VERSION ""

NS_ :

BS_:

BU_: A_IVC BLM CGW VKM

BO_ 1469 IVI_UserSetPref_A4: 8 CGW
  SG_ MeterVolumeRequest : 10|3@0+ (1,0) [0|0] "" A_IVC
  SG_ ADB_ActivationRequest2 : 61|2@0+ (1,0) [0|0] "" A_IVC

BO_ 1470 AVM_N105: 6 CGW
  SG_ RPK_RegistAddress2 : 7|48@0+ (1,0) [0|2.81474976710655E14] "-" VKM

BO_ 1471 PSCU_R1: 4 CGW
  SG_ PassengerMassageIntensityState : 12|3@0+ (1,0) [0|0] "" A_IVC
  SG_ PassengerMassageVelocityState : 15|3@0+ (1,0) [0|0] "" A_IVC
  SG_ PassengerMassageActivationState : 19|1@0+ (1,0) [0|0] "" A_IVC

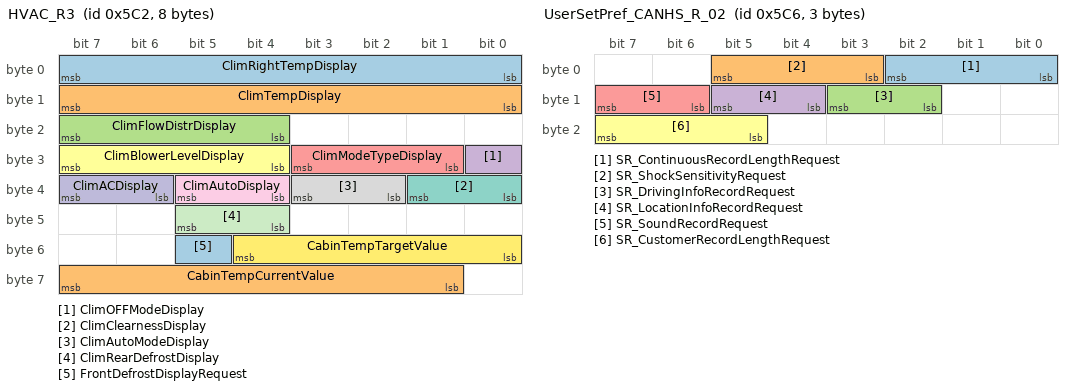
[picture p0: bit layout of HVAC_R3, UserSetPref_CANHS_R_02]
BO_ 1474 HVAC_R3: 8 CGW
  SG_ ClimRightTempDisplay : 7|8@0+ (0.5,0) [10|127.5] "°" A_IVC
  SG_ ClimTempDisplay : 15|8@0+ (0.5,0) [10|127.5] "°" A_IVC
  SG_ ClimFlowDistrDisplay : 23|4@0+ (1,0) [0|0] "" A_IVC
  SG_ ClimOFFModeDisplay : 24|1@0+ (1,0) [0|0] "" A_IVC
  SG_ ClimModeTypeDisplay : 27|3@0+ (1,0) [0|0] "" A_IVC
  SG_ ClimBlowerLevelDisplay : 31|4@0+ (1,0) [0|0] "" A_IVC
  SG_ ClimClearnessDisplay : 33|2@0+ (1,0) [0|0] "" A_IVC
  SG_ ClimAutoModeDisplay : 35|2@0+ (1,0) [0|0] "" A_IVC
  SG_ ClimAutoDisplay : 37|2@0+ (1,0) [0|0] "" A_IVC
  SG_ ClimACDisplay : 39|2@0+ (1,0) [0|0] "" A_IVC
  SG_ ClimRearDefrostDisplay : 45|2@0+ (1,0) [0|0] "" A_IVC
  SG_ CabinTempTargetValue : 52|5@0+ (0.5,16) [16|26] "°C" A_IVC
  SG_ FrontDefrostDisplayRequest : 53|1@0+ (1,0) [0|0] "" A_IVC
  SG_ CabinTempCurrentValue : 63|7@0+ (1,-40) [-40|60] "°C" A_IVC

BO_ 1475 BMS_R2: 8 CGW
  SG_ HVB_Cell111Voltage : 7|12@0+ (0.001,2) [2|4.6] "V" A_IVC
  SG_ HVB_Cell112Voltage : 11|12@0+ (0.001,2) [2|4.6] "V" A_IVC
  SG_ HVB_Cell113Voltage : 31|12@0+ (0.001,2) [2|4.6] "V" A_IVC
  SG_ HVB_Cell114Voltage : 35|12@0+ (0.001,2) [2|4.6] "V" A_IVC
  SG_ HVB_Cell115Voltage : 55|12@0+ (0.001,2) [2|4.6] "V" A_IVC

BO_ 1478 UserSetPref_CANHS_R_02: 3 CGW
  SG_ SR_ContinuousRecordLengthRequest : 2|3@0+ (1,0) [0|0] "" A_IVC
  SG_ SR_ShockSensitivityRequest : 5|3@0+ (1,0) [0|0] "" A_IVC
  SG_ SR_DrivingInfoRecordRequest : 11|2@0+ (1,0) [0|0] "" A_IVC
  SG_ SR_LocationInfoRecordRequest : 13|2@0+ (1,0) [0|0] "" A_IVC
  SG_ SR_SoundRecordRequest : 15|2@0+ (1,0) [0|0] "" A_IVC
  SG_ SR_CustomerRecordLengthRequest : 23|3@0+ (1,0) [0|0] "" A_IVC

BO_ 1479 IVI_R102: 6 CGW
  SG_ ERP_ActivationStatus : 34|1@0+ (1,0) [0|0] "" A_IVC

BO_ 1480 HEVC_A152: 8 CGW
  SG_ ChargeTimeDisplayAtAPrct : 23|12@0+ (1,0) [1|4094] "min" A_IVC
  SG_ ChargeTimeDisplayAtBPrct : 27|12@0+ (1,0) [1|4094] "min" A_IVC
  SG_ ChargeTimeDisplayAtCPrct : 47|12@0+ (1,0) [1|4094] "min" A_IVC
  SG_ ChargeTimeDisplayAtDPrct : 51|12@0+ (1,0) [1|4094] "min" A_IVC

BO_ 1481 BMS_A22: 8 CGW
  SG_ HVB_Cell61Voltage : 7|12@0+ (0.001,2) [2|4.6] "V" A_IVC
  SG_ HVB_Cell62Voltage : 11|12@0+ (0.001,2) [2|4.6] "V" A_IVC
  SG_ HVB_Cell63Voltage : 31|12@0+ (0.001,2) [2|4.6] "V" A_IVC
  SG_ HVB_Cell64Voltage : 35|12@0+ (0.001,2) [2|4.6] "V" A_IVC
  SG_ HVB_Cell65Voltage : 55|12@0+ (0.001,2) [2|4.6] "V" A_IVC

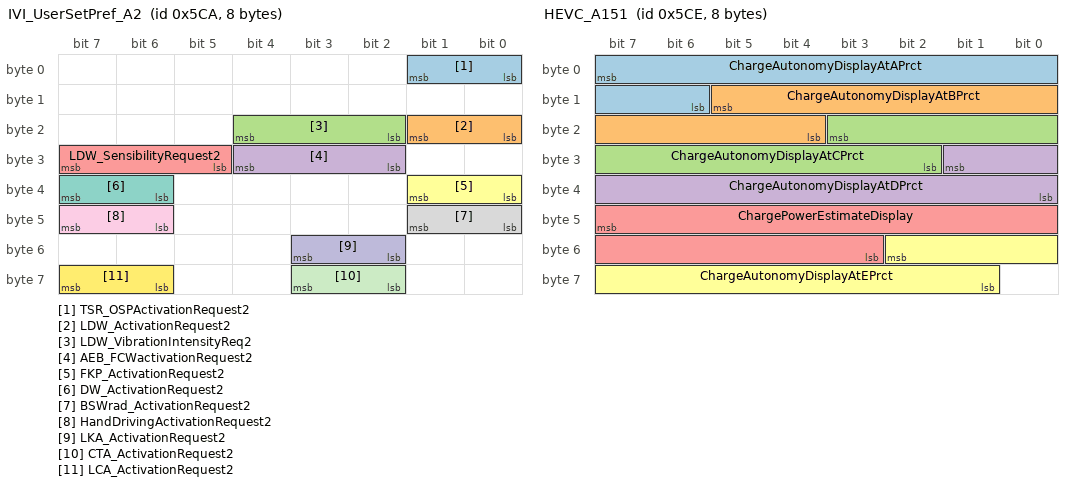
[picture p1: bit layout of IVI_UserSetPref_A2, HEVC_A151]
BO_ 1482 IVI_UserSetPref_A2: 8 CGW
  SG_ TSR_OSPActivationRequest2 : 1|2@0+ (1,0) [0|0] "" A_IVC
  SG_ LDW_ActivationRequest2 : 17|2@0+ (1,0) [0|0] "" A_IVC
  SG_ LDW_VibrationIntensityReq2 : 20|3@0+ (1,0) [0|0] "" A_IVC
  SG_ AEB_FCWactivationRequest2 : 28|3@0+ (1,0) [0|0] "" A_IVC
  SG_ LDW_SensibilityRequest2 : 31|3@0+ (1,0) [0|0] "" A_IVC
  SG_ FKP_ActivationRequest2 : 33|2@0+ (1,0) [0|0] "" A_IVC
  SG_ DW_ActivationRequest2 : 39|2@0+ (1,0) [0|0] "" A_IVC
  SG_ BSWrad_ActivationRequest2 : 41|2@0+ (1,0) [0|0] "" A_IVC
  SG_ HandDrivingActivationRequest2 : 47|2@0+ (1,0) [0|0] "" A_IVC
  SG_ LKA_ActivationRequest2 : 51|2@0+ (1,0) [0|0] "" A_IVC
  SG_ CTA_ActivationRequest2 : 59|2@0+ (1,0) [0|0] "" A_IVC
  SG_ LCA_ActivationRequest2 : 63|2@0+ (1,0) [0|0] "" A_IVC

BO_ 1483 BMS_A21: 8 CGW
  SG_ HVB_Cell56Voltage : 7|12@0+ (0.001,2) [2|4.6] "V" A_IVC
  SG_ HVB_Cell57Voltage : 11|12@0+ (0.001,2) [2|4.6] "V" A_IVC
  SG_ HVB_Cell58Voltage : 31|12@0+ (0.001,2) [2|4.6] "V" A_IVC
  SG_ HVB_Cell59Voltage : 35|12@0+ (0.001,2) [2|4.6] "V" A_IVC
  SG_ HVB_Cell60Voltage : 55|12@0+ (0.001,2) [2|4.6] "V" A_IVC

BO_ 1484 BMS_A20: 8 CGW
  SG_ HVB_Cell51Voltage : 7|12@0+ (0.001,2) [2|4.6] "V" A_IVC
  SG_ HVB_Cell52Voltage : 11|12@0+ (0.001,2) [2|4.6] "V" A_IVC
  SG_ HVB_Cell53Voltage : 31|12@0+ (0.001,2) [2|4.6] "V" A_IVC
  SG_ HVB_Cell54Voltage : 35|12@0+ (0.001,2) [2|4.6] "V" A_IVC
  SG_ HVB_Cell55Voltage : 55|12@0+ (0.001,2) [2|4.6] "V" A_IVC

BO_ 1485 RemoteFunctionService_BCM_Frame: 8 CGW
  SG_ RemoteFunctionService_BCM : 7|64@0+ (1,0) [0|0] "" A_IVC

BO_ 1486 HEVC_A151: 8 CGW
  SG_ ChargeAutonomyDisplayAtAPrct : 7|10@0+ (1,0) [1|1022] "km" A_IVC
  SG_ ChargeAutonomyDisplayAtBPrct : 13|10@0+ (1,0) [1|1022] "km" A_IVC
  SG_ ChargeAutonomyDisplayAtCPrct : 19|10@0+ (1,0) [1|1022] "km" A_IVC
  SG_ ChargeAutonomyDisplayAtDPrct : 25|10@0+ (1,0) [1|1022] "km" A_IVC
  SG_ ChargePowerEstimateDisplay : 47|13@0+ (0.1,0) [0.1|500] "kW" A_IVC
  SG_ ChargeAutonomyDisplayAtEPrct : 50|10@0+ (1,0) [1|1022] "km" A_IVC

BO_ 1488 ADAS_A110: 8 CGW
  SG_ ACC_StatusDisplay_v2 : 63|3@0+ (1,0) [0|0] "" A_IVC

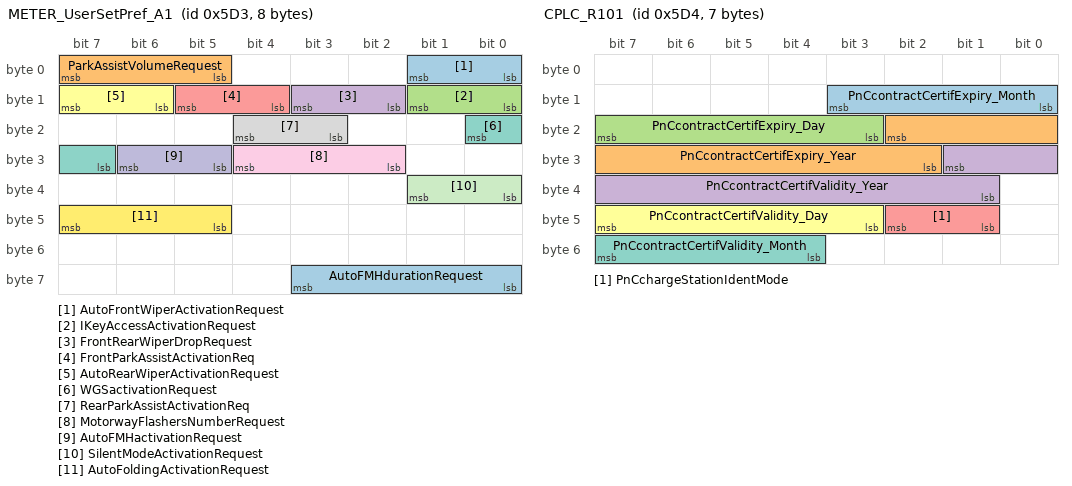
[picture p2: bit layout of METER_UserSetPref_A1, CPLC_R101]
BO_ 1491 METER_UserSetPref_A1: 8 CGW
  SG_ AutoFrontWiperActivationRequest : 1|2@0+ (1,0) [0|0] "" A_IVC
  SG_ ParkAssistVolumeRequest : 7|3@0+ (1,0) [0|0] "" A_IVC
  SG_ IKeyAccessActivationRequest : 9|2@0+ (1,0) [0|0] "" A_IVC
  SG_ FrontRearWiperDropRequest : 11|2@0+ (1,0) [0|0] "" A_IVC
  SG_ FrontParkAssistActivationReq : 13|2@0+ (1,0) [0|0] "" A_IVC
  SG_ AutoRearWiperActivationRequest : 15|2@0+ (1,0) [0|0] "" A_IVC
  SG_ WGSactivationRequest : 16|2@0+ (1,0) [0|0] "" A_IVC
  SG_ RearParkAssistActivationReq : 20|2@0+ (1,0) [0|0] "" A_IVC
  SG_ MotorwayFlashersNumberRequest : 28|3@0+ (1,0) [0|0] "" A_IVC
  SG_ AutoFMHactivationRequest : 30|2@0+ (1,0) [0|0] "" A_IVC
  SG_ SilentModeActivationRequest : 33|2@0+ (1,0) [0|0] "" A_IVC
  SG_ AutoFoldingActivationRequest : 47|3@0+ (1,0) [0|0] "" A_IVC
  SG_ AutoFMHdurationRequest : 59|4@0+ (1,0) [0|0] "" A_IVC

BO_ 1492 CPLC_R101: 7 CGW
  SG_ PnCcontractCertifExpiry_Month : 11|4@0+ (1,0) [0|12] "month" A_IVC
  SG_ PnCcontractCertifExpiry_Year : 18|9@0+ (1,2000) [2000|2500] "year" A_IVC
  SG_ PnCcontractCertifExpiry_Day : 23|5@0+ (1,0) [0|31] "day" A_IVC
  SG_ PnCcontractCertifValidity_Year : 25|9@0+ (1,2000) [2000|2500] "year" A_IVC
  SG_ PnCchargeStationIdentMode : 42|2@0+ (1,0) [0|0] "" A_IVC
  SG_ PnCcontractCertifValidity_Day : 47|5@0+ (1,0) [0|31] "day" A_IVC
  SG_ PnCcontractCertifValidity_Month : 55|4@0+ (1,0) [0|12] "month" A_IVC

BO_ 1493 HEVC_A150: 8 CGW
  SG_ CumulatedEnergyCharged_BLMS : 7|8@0+ (0.5,0) [0|100] "kWh" A_IVC
  SG_ CumulatedEnergyDisharged_BLMS : 15|14@0+ (0.01,0) [0|100] "GWh" A_IVC
  SG_ NumACsmartchargingBreak_BLMS : 17|12@0+ (10,0) [0|40000] "" A_IVC
  SG_ RE_ElecMachineTorque_BLMS : 37|11@0+ (0.5,-300) [-300|500] "Nm" A_IVC
  SG_ RE_ElecMachineWorkingMode_BLMS : 42|1@0+ (1,0) [0|0] "" A_IVC

BO_ 1494 BMS_A19: 8 CGW
  SG_ HVB_Cell46Voltage : 7|12@0+ (0.001,2) [2|4.6] "V" A_IVC
  SG_ HVB_Cell47Voltage : 11|12@0+ (0.001,2) [2|4.6] "V" A_IVC
  SG_ HVB_Cell48Voltage : 31|12@0+ (0.001,2) [2|4.6] "V" A_IVC
  SG_ HVB_Cell49Voltage : 35|12@0+ (0.001,2) [2|4.6] "V" A_IVC
  SG_ HVB_Cell50Voltage : 55|12@0+ (0.001,2) [2|4.6] "V" A_IVC

BO_ 1495 BMS_A18: 8 CGW
  SG_ HVB_Cell41Voltage : 7|12@0+ (0.001,2) [2|4.6] "V" A_IVC
  SG_ HVB_Cell42Voltage : 11|12@0+ (0.001,2) [2|4.6] "V" A_IVC
  SG_ HVB_Cell43Voltage : 31|12@0+ (0.001,2) [2|4.6] "V" A_IVC
  SG_ HVB_Cell44Voltage : 35|12@0+ (0.001,2) [2|4.6] "V" A_IVC
  SG_ HVB_Cell45Voltage : 55|12@0+ (0.001,2) [2|4.6] "V" A_IVC

BO_ 1497 BMS_A17: 8 CGW
  SG_ HVB_Cell36Voltage : 7|12@0+ (0.001,2) [2|4.6] "V" A_IVC
  SG_ HVB_Cell37Voltage : 11|12@0+ (0.001,2) [2|4.6] "V" A_IVC
  SG_ HVB_Cell38Voltage : 31|12@0+ (0.001,2) [2|4.6] "V" A_IVC
  SG_ HVB_Cell39Voltage : 35|12@0+ (0.001,2) [2|4.6] "V" A_IVC
  SG_ HVB_Cell40Voltage : 55|12@0+ (0.001,2) [2|4.6] "V" A_IVC

BO_ 1499 RemoteFunctionService_HFM_Frame: 8 CGW
  SG_ RemoteFunctionService_HFM : 7|64@0+ (1,0) [0|0] "" A_IVC

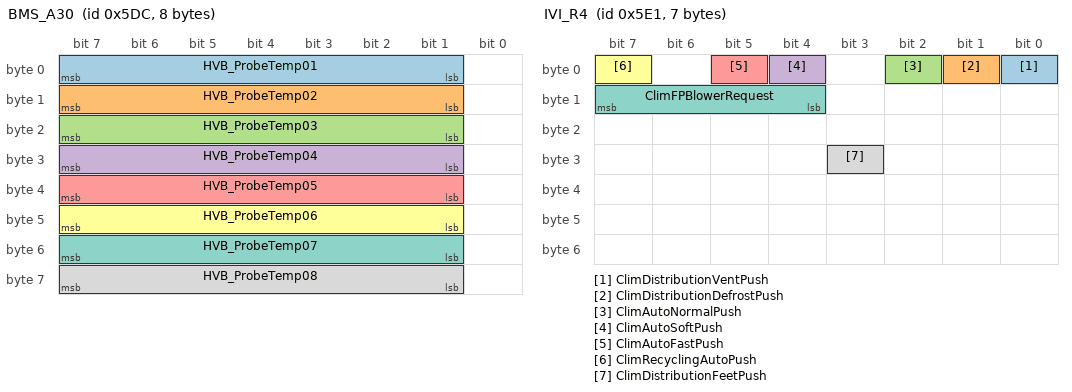
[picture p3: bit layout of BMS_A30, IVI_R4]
BO_ 1500 BMS_A30: 8 CGW
  SG_ HVB_ProbeTemp01 : 7|7@0+ (1,-40) [-40|80] "°C" A_IVC
  SG_ HVB_ProbeTemp02 : 15|7@0+ (1,-40) [-40|80] "°C" A_IVC
  SG_ HVB_ProbeTemp03 : 23|7@0+ (1,-40) [-40|80] "°C" A_IVC
  SG_ HVB_ProbeTemp04 : 31|7@0+ (1,-40) [-40|80] "°C" A_IVC
  SG_ HVB_ProbeTemp05 : 39|7@0+ (1,-40) [-40|80] "°C" A_IVC
  SG_ HVB_ProbeTemp06 : 47|7@0+ (1,-40) [-40|80] "°C" A_IVC
  SG_ HVB_ProbeTemp07 : 55|7@0+ (1,-40) [-40|80] "°C" A_IVC
  SG_ HVB_ProbeTemp08 : 63|7@0+ (1,-40) [-40|80] "°C" A_IVC

BO_ 1501 FRCAMERA_A109: 5 CGW
  SG_ OverspeedAlertStatusDisplay : 38|2@0+ (1,0) [0|0] "" A_IVC

BO_ 1502 CDM_A107: 3 CGW
  SG_ MultiDriveMode_ECM_v2 : 7|4@0+ (1,0) [0|0] "" A_IVC

BO_ 1504 BMS_A101: 8 CGW
  SG_ HVB_Cell96Voltage : 7|12@0+ (0.001,2) [2|4.6] "V" A_IVC
  SG_ HVB_Cell97Voltage : 11|12@0+ (0.001,2) [2|4.6] "V" A_IVC
  SG_ HVB_Cell98Voltage : 31|12@0+ (0.001,2) [2|4.6] "V" A_IVC
  SG_ HVB_Cell99Voltage : 35|12@0+ (0.001,2) [2|4.6] "V" A_IVC
  SG_ HVB_Cell100Voltage : 55|12@0+ (0.001,2) [2|4.6] "V" A_IVC

BO_ 1505 IVI_R4: 7 CGW
  SG_ ClimDistributionVentPush : 0|1@0+ (1,0) [0|1] "" A_IVC
  SG_ ClimDistributionDefrostPush : 1|1@0+ (1,0) [0|1] "" A_IVC
  SG_ ClimAutoNormalPush : 2|1@0+ (1,0) [0|1] "" A_IVC
  SG_ ClimAutoSoftPush : 4|1@0+ (1,0) [0|1] "" A_IVC
  SG_ ClimAutoFastPush : 5|1@0+ (1,0) [0|1] "" A_IVC
  SG_ ClimRecyclingAutoPush : 7|1@0+ (1,0) [0|1] "" A_IVC
  SG_ ClimFPBlowerRequest : 15|4@0+ (1,0) [0|0] "" A_IVC
  SG_ ClimDistributionFeetPush : 27|1@0+ (1,0) [0|1] "" A_IVC

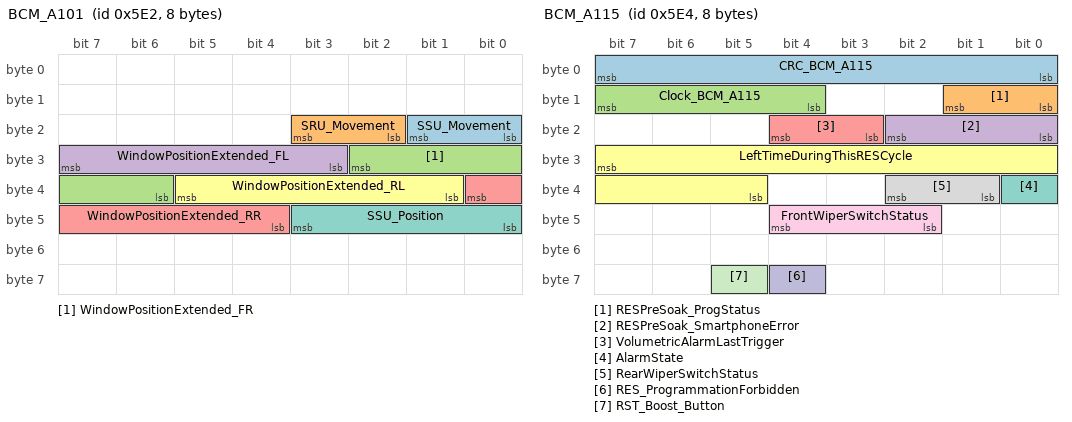
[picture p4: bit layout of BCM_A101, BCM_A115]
BO_ 1506 BCM_A101: 8 CGW
  SG_ SSU_Movement : 17|2@0+ (1,0) [0|0] "" VKM
  SG_ SRU_Movement : 19|2@0+ (1,0) [0|0] "" VKM
  SG_ WindowPositionExtended_FR : 26|5@0+ (1,0) [0|0] "" VKM
  SG_ WindowPositionExtended_FL : 31|5@0+ (1,0) [0|0] "" VKM
  SG_ WindowPositionExtended_RR : 32|5@0+ (1,0) [0|0] "" VKM
  SG_ WindowPositionExtended_RL : 37|5@0+ (1,0) [0|0] "" VKM
  SG_ SSU_Position : 43|4@0+ (1,0) [0|0] "" VKM

BO_ 1508 BCM_A115: 8 CGW
  SG_ CRC_BCM_A115 : 7|8@0+ (1,0) [0|255] "" A_IVC
  SG_ RESPreSoak_ProgStatus : 9|2@0+ (1,0) [0|0] "" A_IVC
  SG_ Clock_BCM_A115 : 15|4@0+ (1,0) [0|15] "" A_IVC
  SG_ RESPreSoak_SmartphoneError : 18|3@0+ (1,0) [0|0] "" A_IVC
  SG_ VolumetricAlarmLastTrigger : 20|2@0+ (1,0) [0|0] "" A_IVC
  SG_ LeftTimeDuringThisRESCycle : 31|11@0+ (1,0) [0|1200] "s" A_IVC
  SG_ AlarmState : 32|1@0+ (1,0) [0|0] "" A_IVC
  SG_ RearWiperSwitchStatus : 34|2@0+ (1,0) [0|0] "" A_IVC
  SG_ FrontWiperSwitchStatus : 44|3@0+ (1,0) [0|0] "" A_IVC
  SG_ RES_ProgrammationForbidden : 60|1@0+ (1,0) [0|0] "" A_IVC
  SG_ RST_Boost_Button : 61|1@0+ (1,0) [0|0] "" A_IVC

BO_ 1509 RemoteFunctionService_TCU_Frame: 8 A_IVC
  SG_ RemoteFunctionService_TCU : 7|64@0+ (1,0) [0|0] "" CGW

BO_ 1510 METER_A107: 8 CGW
  SG_ FixedMaintenanceRange : 7|8@0+ (250,0) [0|63250] "km" A_IVC
  SG_ DistanceToEmptyTank : 15|11@0+ (1,0) [0|2046] "km" A_IVC
  SG_ AlertMinBeforeOverhaul : 17|2@0+ (1,0) [0|0] "" A_IVC
  SG_ MilageMinBeforeOverhaul : 39|8@0+ (250,0) [0|63500] "km" A_IVC
  SG_ TimeBeforeDraining : 47|9@0+ (1,0) [0|511] "day" A_IVC

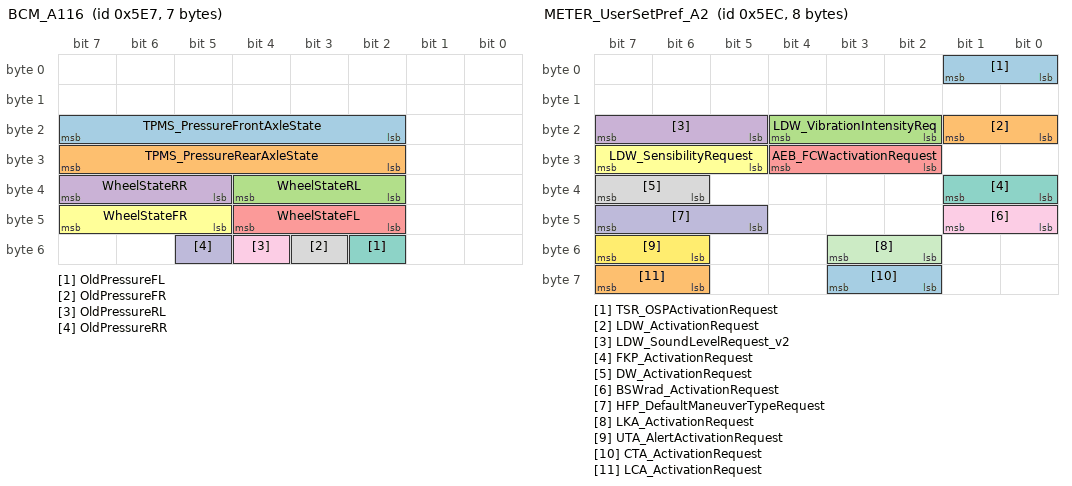
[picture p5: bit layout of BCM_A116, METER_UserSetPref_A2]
BO_ 1511 BCM_A116: 7 CGW
  SG_ TPMS_PressureFrontAxleState : 23|6@0+ (10,150) [150|760] "kPa" A_IVC
  SG_ TPMS_PressureRearAxleState : 31|6@0+ (10,150) [150|760] "kPa" A_IVC
  SG_ WheelStateRL : 36|3@0+ (1,0) [0|0] "" A_IVC
  SG_ WheelStateRR : 39|3@0+ (1,0) [0|0] "" A_IVC
  SG_ WheelStateFL : 44|3@0+ (1,0) [0|0] "" A_IVC
  SG_ WheelStateFR : 47|3@0+ (1,0) [0|0] "" A_IVC
  SG_ OldPressureFL : 50|1@0+ (1,0) [0|0] "" A_IVC
  SG_ OldPressureFR : 51|1@0+ (1,0) [0|0] "" A_IVC
  SG_ OldPressureRL : 52|1@0+ (1,0) [0|0] "" A_IVC
  SG_ OldPressureRR : 53|1@0+ (1,0) [0|0] "" A_IVC

BO_ 1513 AVM_N115: 6 CGW
  SG_ RPK_RegistAddress6 : 7|48@0+ (1,0) [0|2.81474976710655E14] "-" VKM

BO_ 1514 BMS_A16: 8 CGW
  SG_ HVB_Cell31Voltage : 7|12@0+ (0.001,2) [2|4.6] "V" A_IVC
  SG_ HVB_Cell32Voltage : 11|12@0+ (0.001,2) [2|4.6] "V" A_IVC
  SG_ HVB_Cell33Voltage : 31|12@0+ (0.001,2) [2|4.6] "V" A_IVC
  SG_ HVB_Cell34Voltage : 35|12@0+ (0.001,2) [2|4.6] "V" A_IVC
  SG_ HVB_Cell35Voltage : 55|12@0+ (0.001,2) [2|4.6] "V" A_IVC

BO_ 1516 METER_UserSetPref_A2: 8 CGW
  SG_ TSR_OSPActivationRequest : 1|2@0+ (1,0) [0|0] "" A_IVC
  SG_ LDW_ActivationRequest : 17|2@0+ (1,0) [0|0] "" A_IVC
  SG_ LDW_VibrationIntensityReq : 20|3@0+ (1,0) [0|0] "" A_IVC
  SG_ LDW_SoundLevelRequest_v2 : 23|3@0+ (1,0) [0|0] "" A_IVC
  SG_ AEB_FCWactivationRequest : 28|3@0+ (1,0) [0|0] "" A_IVC
  SG_ LDW_SensibilityRequest : 31|3@0+ (1,0) [0|0] "" A_IVC
  SG_ FKP_ActivationRequest : 33|2@0+ (1,0) [0|0] "" A_IVC
  SG_ DW_ActivationRequest : 39|2@0+ (1,0) [0|0] "" A_IVC
  SG_ BSWrad_ActivationRequest : 41|2@0+ (1,0) [0|0] "" A_IVC
  SG_ HFP_DefaultManeuverTypeRequest : 47|3@0+ (1,0) [0|0] "" A_IVC
  SG_ LKA_ActivationRequest : 51|2@0+ (1,0) [0|0] "" A_IVC
  SG_ UTA_AlertActivationRequest : 55|2@0+ (1,0) [0|0] "" A_IVC
  SG_ CTA_ActivationRequest : 59|2@0+ (1,0) [0|0] "" A_IVC
  SG_ LCA_ActivationRequest : 63|2@0+ (1,0) [0|0] "" A_IVC

BO_ 1517 BMS_A15: 8 CGW
  SG_ HVB_Cell26Voltage : 7|12@0+ (0.001,2) [2|4.6] "V" A_IVC
  SG_ HVB_Cell27Voltage : 11|12@0+ (0.001,2) [2|4.6] "V" A_IVC
  SG_ HVB_Cell28Voltage : 31|12@0+ (0.001,2) [2|4.6] "V" A_IVC
  SG_ HVB_Cell29Voltage : 35|12@0+ (0.001,2) [2|4.6] "V" A_IVC
  SG_ HVB_Cell30Voltage : 55|12@0+ (0.001,2) [2|4.6] "V" A_IVC

BO_ 1519 IVI_A101: 8 CGW
  SG_ CurrentUserState_v2 : 23|3@0+ (1,0) [0|0] "" A_IVC
  SG_ MC_PositionRecallRequest : 51|4@0+ (1,0) [0|0] "" A_IVC
  SG_ MC_PositionSaveRequest : 63|4@0+ (1,0) [0|0] "" A_IVC

BO_ 1520 BMS_A14: 8 CGW
  SG_ HVB_Cell21Voltage : 7|12@0+ (0.001,2) [2|4.6] "V" A_IVC
  SG_ HVB_Cell22Voltage : 11|12@0+ (0.001,2) [2|4.6] "V" A_IVC
  SG_ HVB_Cell23Voltage : 31|12@0+ (0.001,2) [2|4.6] "V" A_IVC
  SG_ HVB_Cell24Voltage : 35|12@0+ (0.001,2) [2|4.6] "V" A_IVC
  SG_ HVB_Cell25Voltage : 55|12@0+ (0.001,2) [2|4.6] "V" A_IVC

BO_ 1521 BMS_A13: 8 CGW
  SG_ HVB_Cell16Voltage : 7|12@0+ (0.001,2) [2|4.6] "V" A_IVC
  SG_ HVB_Cell17Voltage : 11|12@0+ (0.001,2) [2|4.6] "V" A_IVC
  SG_ HVB_Cell18Voltage : 31|12@0+ (0.001,2) [2|4.6] "V" A_IVC
  SG_ HVB_Cell19Voltage : 35|12@0+ (0.001,2) [2|4.6] "V" A_IVC
  SG_ HVB_Cell20Voltage : 55|12@0+ (0.001,2) [2|4.6] "V" A_IVC

BO_ 1522 BMS_A12: 8 CGW
  SG_ HVB_Cell11Voltage : 7|12@0+ (0.001,2) [2|4.6] "V" A_IVC
  SG_ HVB_Cell12Voltage : 11|12@0+ (0.001,2) [2|4.6] "V" A_IVC
  SG_ HVB_Cell13Voltage : 31|12@0+ (0.001,2) [2|4.6] "V" A_IVC
  SG_ HVB_Cell14Voltage : 35|12@0+ (0.001,2) [2|4.6] "V" A_IVC
  SG_ HVB_Cell15Voltage : 55|12@0+ (0.001,2) [2|4.6] "V" A_IVC

BO_ 1523 HEVC_R107: 3 CGW
  SG_ HVbatInstantInputPower_v2 : 15|11@0+ (0.25,-255) [-255|255] "kW" A_IVC

BO_ 1524 BMS_A11: 8 CGW
  SG_ HVB_Cell06Voltage : 7|12@0+ (0.001,2) [2|4.6] "V" A_IVC
  SG_ HVB_Cell07Voltage : 11|12@0+ (0.001,2) [2|4.6] "V" A_IVC
  SG_ HVB_Cell08Voltage : 31|12@0+ (0.001,2) [2|4.6] "V" A_IVC
  SG_ HVB_Cell09Voltage : 35|12@0+ (0.001,2) [2|4.6] "V" A_IVC
  SG_ HVB_Cell10Voltage : 55|12@0+ (0.001,2) [2|4.6] "V" A_IVC

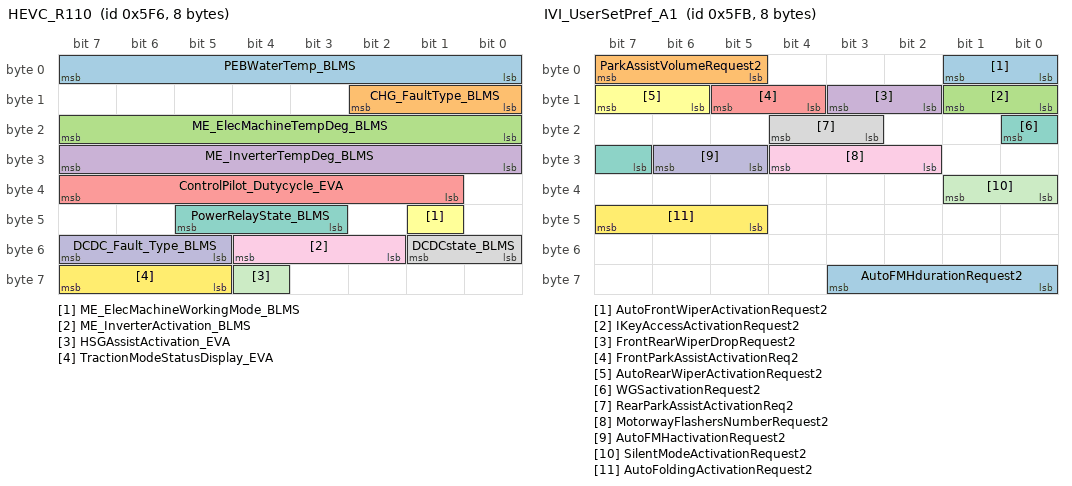
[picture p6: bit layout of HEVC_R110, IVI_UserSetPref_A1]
BO_ 1526 HEVC_R110: 8 CGW
  SG_ PEBWaterTemp_BLMS : 7|8@0+ (1,-40) [-40|120] "°C" A_IVC
  SG_ CHG_FaultType_BLMS : 10|3@0+ (1,0) [0|0] "" A_IVC
  SG_ ME_ElecMachineTempDeg_BLMS : 23|8@0+ (1,-40) [-40|210] "°C" A_IVC
  SG_ ME_InverterTempDeg_BLMS : 31|8@0+ (1,-40) [-40|210] "°C" A_IVC
  SG_ ControlPilot_Dutycycle_EVA : 39|7@0+ (1,0) [0|100] "%" A_IVC
  SG_ ME_ElecMachineWorkingMode_BLMS : 41|1@0+ (1,0) [0|0] "" A_IVC
  SG_ PowerRelayState_BLMS : 45|3@0+ (1,0) [0|0] "" A_IVC
  SG_ DCDCstate_BLMS : 49|2@0+ (1,0) [0|0] "" A_IVC
  SG_ ME_InverterActivation_BLMS : 52|3@0+ (1,0) [0|0] "" A_IVC
  SG_ DCDC_Fault_Type_BLMS : 55|3@0+ (1,0) [0|0] "" A_IVC
  SG_ HSGAssistActivation_EVA : 60|1@0+ (1,0) [0|0] "" A_IVC
  SG_ TractionModeStatusDisplay_EVA : 63|3@0+ (1,0) [0|0] "" A_IVC

BO_ 1527 BMS_A10: 8 CGW
  SG_ HVB_Cell01Voltage : 7|12@0+ (0.001,2) [2|4.6] "V" A_IVC
  SG_ HVB_Cell02Voltage : 11|12@0+ (0.001,2) [2|4.6] "V" A_IVC
  SG_ HVB_Cell03Voltage : 31|12@0+ (0.001,2) [2|4.6] "V" A_IVC
  SG_ HVB_Cell04Voltage : 35|12@0+ (0.001,2) [2|4.6] "V" A_IVC
  SG_ HVB_Cell05Voltage : 55|12@0+ (0.001,2) [2|4.6] "V" A_IVC

BO_ 1530 METER_UserSetPref_A3: 8 CGW
  SG_ BSWson_ActivationRequest : 5|2@0+ (1,0) [0|0] "" A_IVC
  SG_ HUD_TSRactivationRequest : 13|2@0+ (1,0) [0|0] "" A_IVC
  SG_ WDA_ActivationRequest : 43|2@0+ (1,0) [0|0] "" A_IVC

BO_ 1531 IVI_UserSetPref_A1: 8 CGW
  SG_ AutoFrontWiperActivationRequest2 : 1|2@0+ (1,0) [0|0] "" A_IVC
  SG_ ParkAssistVolumeRequest2 : 7|3@0+ (1,0) [0|0] "" A_IVC
  SG_ IKeyAccessActivationRequest2 : 9|2@0+ (1,0) [0|0] "" A_IVC
  SG_ FrontRearWiperDropRequest2 : 11|2@0+ (1,0) [0|0] "" A_IVC
  SG_ FrontParkAssistActivationReq2 : 13|2@0+ (1,0) [0|0] "" A_IVC
  SG_ AutoRearWiperActivationRequest2 : 15|2@0+ (1,0) [0|0] "" A_IVC
  SG_ WGSactivationRequest2 : 16|2@0+ (1,0) [0|0] "" A_IVC
  SG_ RearParkAssistActivationReq2 : 20|2@0+ (1,0) [0|0] "" A_IVC
  SG_ MotorwayFlashersNumberRequest2 : 28|3@0+ (1,0) [0|0] "" A_IVC
  SG_ AutoFMHactivationRequest2 : 30|2@0+ (1,0) [0|0] "" A_IVC
  SG_ SilentModeActivationRequest2 : 33|2@0+ (1,0) [0|0] "" A_IVC
  SG_ AutoFoldingActivationRequest2 : 47|3@0+ (1,0) [0|0] "" A_IVC
  SG_ AutoFMHdurationRequest2 : 59|4@0+ (1,0) [0|0] "" A_IVC

BO_ 1532 BMS_A103: 8 CGW
  SG_ HVB_Cell101Voltage : 7|12@0+ (0.001,2) [2|4.6] "V" A_IVC
  SG_ HVB_Cell102Voltage : 11|12@0+ (0.001,2) [2|4.6] "V" A_IVC
  SG_ HVB_Cell103Voltage : 31|12@0+ (0.001,2) [2|4.6] "V" A_IVC
  SG_ HVB_Cell104Voltage : 35|12@0+ (0.001,2) [2|4.6] "V" A_IVC
  SG_ HVB_Cell105Voltage : 55|12@0+ (0.001,2) [2|4.6] "V" A_IVC

BO_ 1533 METER_A101: 8 CGW
  SG_ V2X_Meter_MainSwitchState : 16|1@0+ (1,0) [0|0] "" A_IVC
  SG_ V2X_Meter_SubSwitchState : 53|8@0+ (1,0) [0|0] "" A_IVC

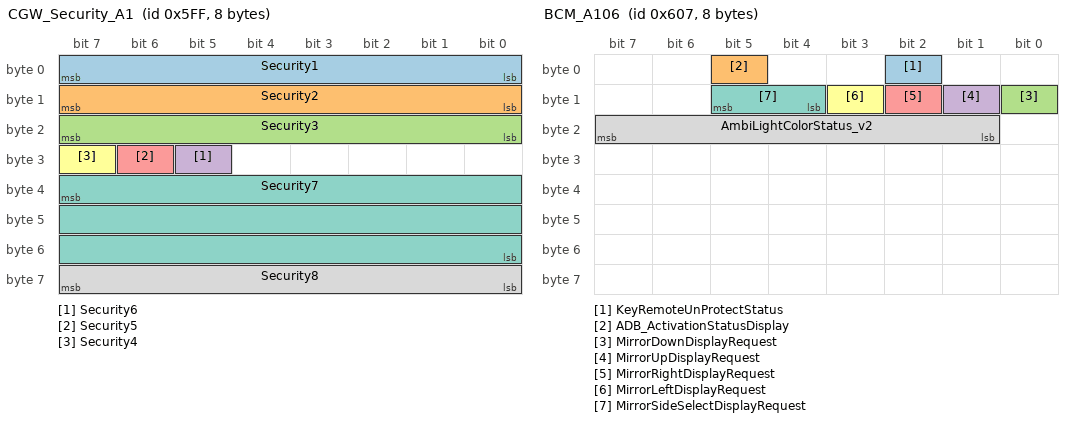
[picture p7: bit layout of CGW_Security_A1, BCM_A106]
BO_ 1535 CGW_Security_A1: 8 CGW
  SG_ Security1 : 7|8@0+ (1,0) [0|0] "" A_IVC
  SG_ Security2 : 15|8@0+ (1,0) [0|0] "" A_IVC
  SG_ Security3 : 23|8@0+ (1,0) [0|0] "" A_IVC
  SG_ Security6 : 29|1@0+ (1,0) [0|0] "" A_IVC
  SG_ Security5 : 30|1@0+ (1,0) [0|0] "" A_IVC
  SG_ Security4 : 31|1@0+ (1,0) [0|0] "" A_IVC
  SG_ Security7 : 39|24@0+ (1,0) [0|0] "" A_IVC
  SG_ Security8 : 63|8@0+ (1,0) [0|255] "" A_IVC

BO_ 1537 ADAS_A119: 8 CGW
  SG_ ACC_TargetDistanceAlert : 10|2@0+ (1,0) [0|0] "" A_IVC
  SG_ ACC_TargetDistanceDisplay : 15|3@0+ (1,0) [0|0] "" A_IVC
  SG_ ACC_SpeedSettingDisplay : 31|8@0+ (1,0) [0|255] "wu" A_IVC
  SG_ ACC_DistanceSettingDisplay : 39|3@0+ (1,0) [0|0] "" A_IVC

BO_ 1538 ADAS_A120: 8 CGW
  SG_ LDW_AlertStatus : 21|2@0+ (1,0) [0|0] "" A_IVC
  SG_ WDA_ActivationState : 49|1@0+ (1,0) [0|0] "" A_IVC
  SG_ WDA_DriverAttentionLevel : 63|4@0+ (1,0) [0|0] "" A_IVC

BO_ 1539 ATCU_A106: 5 CGW
  SG_ GearboxOilTemperature : 15|8@0+ (1,-40) [-40|214] "°C" A_IVC

BO_ 1543 BCM_A106: 8 CGW
  SG_ KeyRemoteUnProtectStatus : 2|1@0+ (1,0) [0|0] "" A_IVC
  SG_ ADB_ActivationStatusDisplay : 5|1@0+ (1,0) [0|0] "" A_IVC
  SG_ MirrorDownDisplayRequest : 8|1@0+ (1,0) [0|0] "" A_IVC
  SG_ MirrorUpDisplayRequest : 9|1@0+ (1,0) [0|0] "" A_IVC
  SG_ MirrorRightDisplayRequest : 10|1@0+ (1,0) [0|0] "" A_IVC
  SG_ MirrorLeftDisplayRequest : 11|1@0+ (1,0) [0|0] "" A_IVC
  SG_ MirrorSideSelectDisplayRequest : 13|2@0+ (1,0) [0|0] "" A_IVC
  SG_ AmbiLightColorStatus_v2 : 23|7@0+ (1,0) [0|0] "" A_IVC

BO_ 1551 HEVC_A127: 8 CGW
  SG_ BatteryWatterTempActivationReq : 16|1@0+ (1,0) [0|0] "" A_IVC
  SG_ WaterBatteryTempTarget : 62|7@0+ (1,-40) [-40|60] "°C" A_IVC

BO_ 1553 HVAC_A106: 8 CGW
  SG_ SecondRowCentralSeatStatus : 2|3@0+ (1,0) [0|0] "" A_IVC
  SG_ FrontRightSeatStatus : 27|3@0+ (1,0) [0|0] "" A_IVC
  SG_ FrontLeftSeatStatus : 30|3@0+ (1,0) [0|0] "" A_IVC
  SG_ ClimCabinTempDisplayUnit : 48|1@0+ (1,0) [0|0] "" A_IVC
  SG_ ClimLastFuncModifiedByCustomer_v2 : 55|4@0+ (1,0) [0|0] "" A_IVC

BO_ 1559 ECM_A129: 2 CGW
  SG_ DCDC_48V_NetworkVoltage_EVA : 7|10@0+ (0.1,0) [0|60] "V" A_IVC

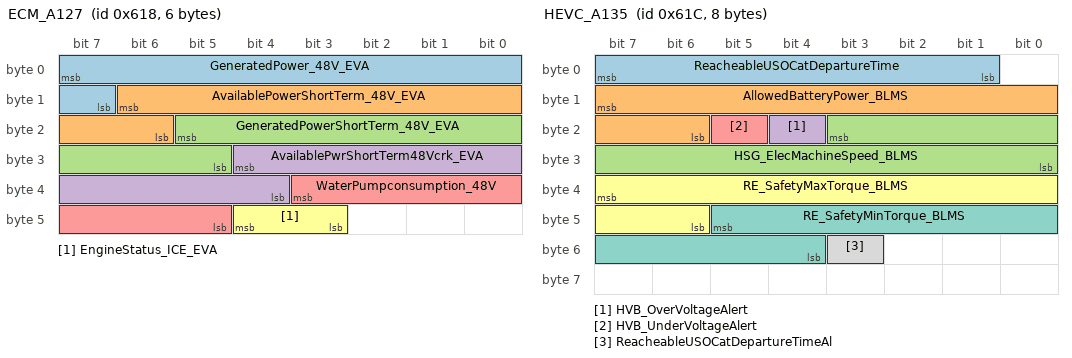
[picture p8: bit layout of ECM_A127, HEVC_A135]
BO_ 1560 ECM_A127: 6 CGW
  SG_ GeneratedPower_48V_EVA : 7|9@0+ (0.125,0) [0|50] "kW" A_IVC
  SG_ AvailablePowerShortTerm_48V_EVA : 14|9@0+ (0.125,0) [0|50] "kW" A_IVC
  SG_ GeneratedPowerShortTerm_48V_EVA : 21|9@0+ (0.125,0) [0|50] "kW" A_IVC
  SG_ AvailablePwrShortTerm48Vcrk_EVA : 28|9@0+ (0.125,0) [0|50] "kW" A_IVC
  SG_ WaterPumpconsumption_48V : 35|7@0+ (10,0) [0|800] "W" A_IVC
  SG_ EngineStatus_ICE_EVA : 44|2@0+ (1,0) [0|0] "" A_IVC

BO_ 1561 HEVC_A131: 8 CGW
  SG_ HVB_MaxCapacity_HEVC_v2 : 9|16@0+ (0.1,0) [0|6553.5] "kWh" A_IVC

BO_ 1562 HEVC_A132: 8 CGW
  SG_ HVB_MaxTempProbe : 7|7@0+ (1,-40) [-40|80] "°C" A_IVC
  SG_ DCcharge_EVTargetCurrent : 17|15@0+ (0.1,-400) [-400|1023] "A" A_IVC
  SG_ HVinterlockAlert : 32|1@0+ (1,0) [0|0] "" A_IVC
  SG_ HVB_MinTempProbe : 47|7@0+ (1,-40) [-40|80] "°C" A_IVC

BO_ 1564 HEVC_A135: 8 CGW
  SG_ ReacheableUSOCatDepartureTime : 7|7@0+ (1,0) [0|100] "%" A_IVC
  SG_ AllowedBatteryPower_BLMS : 15|10@0+ (1,0) [0|512] "kW" A_IVC
  SG_ HSG_ElecMachineSpeed_BLMS : 19|12@0+ (10,-20000) [-20000|20000] "rpm" A_IVC
  SG_ HVB_OverVoltageAlert : 20|1@0+ (1,0) [0|0] "" A_IVC
  SG_ HVB_UnderVoltageAlert : 21|1@0+ (1,0) [0|0] "" A_IVC
  SG_ RE_SafetyMaxTorque_BLMS : 39|10@0+ (0.5,0) [0|500] "Nm" A_IVC
  SG_ RE_SafetyMinTorque_BLMS : 45|10@0+ (0.5,-300) [-300|0] "Nm" A_IVC
  SG_ ReacheableUSOCatDepartureTimeAl : 51|1@0+ (1,0) [0|0] "" A_IVC

BO_ 1568 HEVC_A35: 5 CGW
  SG_ HSG_TorqueRequest_BLMS : 29|9@0+ (1,-250) [-250|250] "Nm" A_IVC

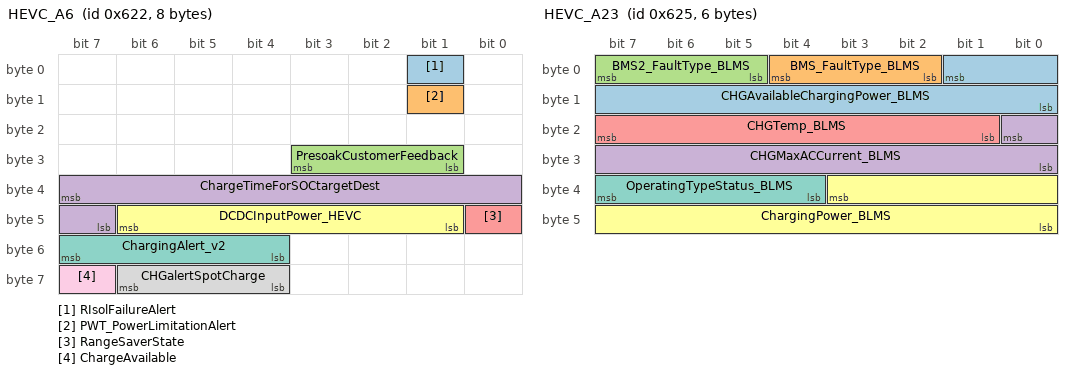
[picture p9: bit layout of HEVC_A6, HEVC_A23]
BO_ 1570 HEVC_A6: 8 CGW
  SG_ RIsolFailureAlert : 1|1@0+ (1,0) [0|0] "" A_IVC
  SG_ PWT_PowerLimitationAlert : 9|1@0+ (1,0) [0|0] "" A_IVC
  SG_ PresoakCustomerFeedback : 27|3@0+ (1,0) [0|0] "" A_IVC
  SG_ ChargeTimeForSOCtargetDest : 39|9@0+ (5,0) [0|2555] "min" A_IVC
  SG_ RangeSaverState : 40|1@0+ (1,0) [0|0] "" A_IVC
  SG_ DCDCInputPower_HEVC : 46|6@0+ (0.1,0) [0|6] "kW" A_IVC
  SG_ ChargingAlert_v2 : 55|4@0+ (1,0) [0|0] "" A_IVC
  SG_ CHGalertSpotCharge : 62|3@0+ (1,0) [0|0] "" A_IVC
  SG_ ChargeAvailable : 63|1@0+ (1,0) [0|0] "" A_IVC

BO_ 1571 HEVC_A136: 8 CGW
  SG_ HVInputPowerAvailableFromBattery : 7|11@0+ (10,0) [0|15000] "W" A_IVC
  SG_ ProgrammedChargeStatus_HEVC : 41|3@0+ (1,0) [0|0] "" A_IVC

BO_ 1572 HEVC_R105: 7 CGW
  SG_ TotalConsumption_LastTrip : 7|12@0+ (0.1,0) [0|409.4] "kWh" A_IVC
  SG_ TotalRecovery_LastTrip : 11|12@0+ (0.1,0) [0|409.4] "kWh" A_IVC
  SG_ EnergyMode : 31|2@0+ (1,0) [0|0] "" A_IVC

BO_ 1573 HEVC_A23: 6 CGW
  SG_ CHGAvailableChargingPower_BLMS : 1|10@0+ (0.05,0) [0|51] "kW" A_IVC
  SG_ BMS_FaultType_BLMS : 4|3@0+ (1,0) [0|0] "" A_IVC
  SG_ BMS2_FaultType_BLMS : 7|3@0+ (1,0) [0|0] "" A_IVC
  SG_ CHGMaxACCurrent_BLMS : 16|9@0+ (0.1,0) [0|51] "A" A_IVC
  SG_ CHGTemp_BLMS : 23|7@0+ (1,0) [0|100] "%" A_IVC
  SG_ ChargingPower_BLMS : 35|12@0+ (0.1,0) [0|400] "kW" A_IVC
  SG_ OperatingTypeStatus_BLMS : 39|4@0+ (1,0) [0|0] "" A_IVC

BO_ 1578 DMC_A101: 8 CGW
  SG_ Drowsy_LevelStatus : 5|3@0+ (1,0) [0|0] "" A_IVC
  SG_ Drowsy_AlertStatus : 7|2@0+ (1,0) [0|0] "" A_IVC
  SG_ Drowsy_AlertActivationState : 15|2@0+ (1,0) [0|0] "" A_IVC
  SG_ Distraction_AlertActivationState : 55|2@0+ (1,0) [0|0] "" A_IVC

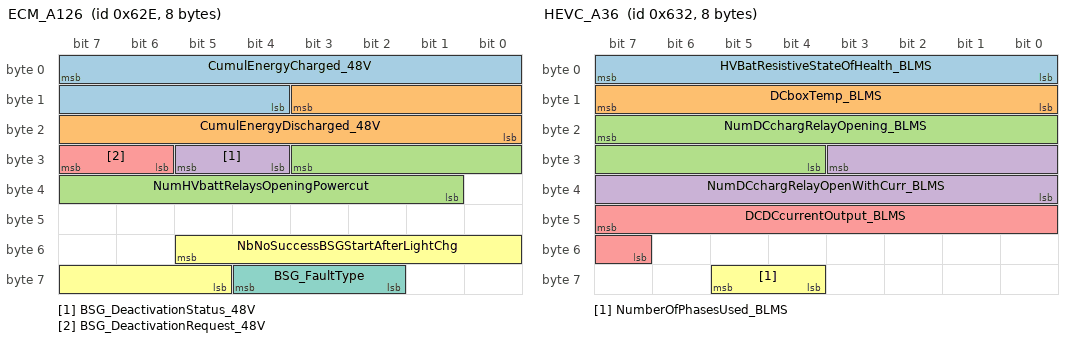
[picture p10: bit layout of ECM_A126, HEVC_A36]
BO_ 1582 ECM_A126: 8 CGW
  SG_ CumulEnergyCharged_48V : 7|12@0+ (0.005,0) [0|20] "MWh" A_IVC
  SG_ CumulEnergyDischarged_48V : 11|12@0+ (0.005,0) [0|20] "MWh" A_IVC
  SG_ NumHVbattRelaysOpeningPowercut : 27|11@0+ (1,0) [0|2047] "-" A_IVC
  SG_ BSG_DeactivationStatus_48V : 29|2@0+ (1,0) [0|0] "" A_IVC
  SG_ BSG_DeactivationRequest_48V : 31|2@0+ (1,0) [0|0] "" A_IVC
  SG_ NbNoSuccessBSGStartAfterLightChg : 53|9@0+ (1,0) [0|511] "-" A_IVC
  SG_ BSG_FaultType : 60|3@0+ (1,0) [0|0] "" A_IVC

BO_ 1585 HEVC_A112: 8 CGW
  SG_ AverageConsumptionZEV_LastStart : 23|10@0+ (0.1,0) [0|102.2] "-" A_IVC
  SG_ AverageConsumptionZEV_LastRefuel : 29|10@0+ (0.1,0) [0|102.2] "" A_IVC

BO_ 1586 HEVC_A36: 8 CGW
  SG_ HVBatResistiveStateOfHealth_BLMS : 7|8@0+ (1,100) [100|354] "%" A_IVC
  SG_ DCboxTemp_BLMS : 15|8@0+ (1,-40) [-40|210] "°C" A_IVC
  SG_ NumDCchargRelayOpening_BLMS : 23|12@0+ (10,0) [0|40000] "wu" A_IVC
  SG_ NumDCchargRelayOpenWithCurr_BLMS : 27|12@0+ (10,0) [0|40000] "wu" A_IVC
  SG_ DCDCcurrentOutput_BLMS : 47|9@0+ (1,0) [0|511] "A" A_IVC
  SG_ NumberOfPhasesUsed_BLMS : 61|2@0+ (1,0) [0|0] "" A_IVC

BO_ 1592 HVAC_A107: 8 CGW
  SG_ HVbatConditioningMode : 21|4@0+ (1,0) [0|0] "" A_IVC
  SG_ CoolingBattery_HVACmode : 29|2@0+ (1,0) [0|0] "" A_IVC
  SG_ HVbatHeater_Power : 34|9@0+ (10,0) [0|5000] "W" A_IVC
  SG_ PresoakImmediate_HVACmode : 37|2@0+ (1,0) [0|0] "" A_IVC
  SG_ PreConditioningBattery_HVACmode : 39|2@0+ (1,0) [0|0] "" A_IVC

BO_ 1595 IVI_A114: 8 CGW
  SG_ Drowsy_AlertActivationRequest2 : 49|2@0+ (1,0) [0|0] "" A_IVC
  SG_ OSE_ActivationRequest2 : 59|2@0+ (1,0) [0|0] "" A_IVC

BO_ 1596 IVI_R103: 8 CGW
  SG_ CurrentPhoneStatus : 11|3@0+ (1,0) [0|0] "" A_IVC
  SG_ CurrentAudioSource_v2 : 15|4@0+ (1,0) [0|0] "" A_IVC
  SG_ CurrentRadioBand_v2 : 23|3@0+ (1,0) [0|0] "" A_IVC

BO_ 1603 HEVC_A149: 8 CGW
  SG_ RE_RotorTemp_BLMS : 55|8@0+ (1,-40) [-40|215] "°C" A_IVC
  SG_ RE_StatorTemp_BLMS : 63|8@0+ (1,-40) [-40|215] "°C" A_IVC

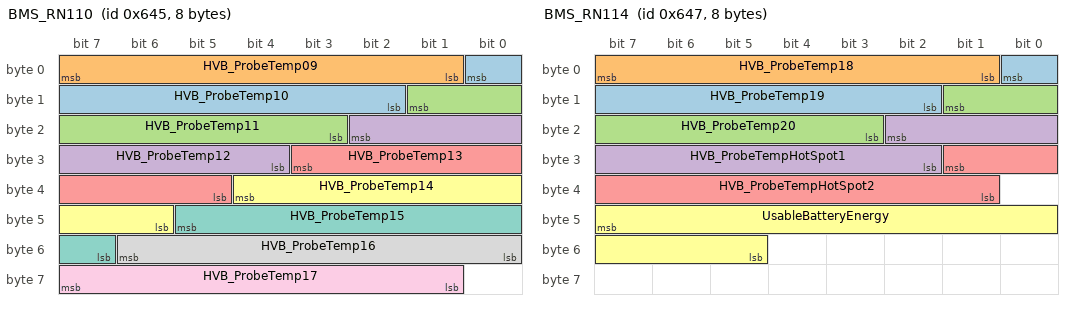
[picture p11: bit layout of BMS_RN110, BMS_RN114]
BO_ 1605 BMS_RN110: 8 CGW
  SG_ HVB_ProbeTemp10 : 0|7@0+ (1,-40) [-40|80] "°C" A_IVC
  SG_ HVB_ProbeTemp09 : 7|7@0+ (1,-40) [-40|80] "°C" A_IVC
  SG_ HVB_ProbeTemp11 : 9|7@0+ (1,-40) [-40|80] "°C" A_IVC
  SG_ HVB_ProbeTemp12 : 18|7@0+ (1,-40) [-40|80] "°C" A_IVC
  SG_ HVB_ProbeTemp13 : 27|7@0+ (1,-40) [-40|80] "°C" A_IVC
  SG_ HVB_ProbeTemp14 : 36|7@0+ (1,-40) [-40|80] "°C" A_IVC
  SG_ HVB_ProbeTemp15 : 45|7@0+ (1,-40) [-40|80] "°C" A_IVC
  SG_ HVB_ProbeTemp16 : 54|7@0+ (1,-40) [-40|80] "°C" A_IVC
  SG_ HVB_ProbeTemp17 : 63|7@0+ (1,-40) [-40|80] "°C" A_IVC

BO_ 1607 BMS_RN114: 8 CGW
  SG_ HVB_ProbeTemp19 : 0|7@0+ (1,-40) [-40|80] "°C" A_IVC
  SG_ HVB_ProbeTemp18 : 7|7@0+ (1,-40) [-40|80] "°C" A_IVC
  SG_ HVB_ProbeTemp20 : 9|7@0+ (1,-40) [-40|80] "°C" A_IVC
  SG_ HVB_ProbeTempHotSpot1 : 18|9@0+ (1,-40) [-40|450] "°C" A_IVC
  SG_ HVB_ProbeTempHotSpot2 : 25|9@0+ (1,-40) [-40|450] "°C" A_IVC
  SG_ UsableBatteryEnergy : 47|11@0+ (0.1,0) [0|200] "KWh" A_IVC

BO_ 1608 CSCM_A102: 7 CGW
  SG_ V2X_EVSEdischarge : 11|2@0+ (1,0) [0|0] "" A_IVC

BO_ 1611 CSCM_A105: 8 CGW
  SG_ DCcharge_EVSEMaximumCurrentLimit : 40|15@0+ (0.1,-400) [-400|1023] "A" A_IVC

BO_ 1614 IVI_A129: 8 CGW
  SG_ CASP_ActivationRequest2 : 7|2@0+ (1,0) [0|0] "" A_IVC

BO_ 1615 HEVC_N105: 8 CGW
  SG_ OBECM_ChargedEnergy_Lifetime : 7|32@0+ (0.1,0) [0|4.294967295E8] "kWh" A_IVC
  SG_ OBECM_TotalDistance_Lifetime : 39|32@0+ (0.1,0) [0|4.294967295E8] "km" A_IVC

BO_ 1616 SONAR_A122: 2 CGW
  SG_ APA_WarningDisplayRequest2 : 7|6@0+ (1,0) [0|0] "" A_IVC

BO_ 1618 HEVC_A38: 8 CGW
  SG_ ACchargeInletTemp_BLMS : 7|8@0+ (1,-40) [-40|210] "°C" A_IVC
  SG_ DCchargeInletTemp_BLMS : 15|8@0+ (1,-40) [-40|210] "°C" A_IVC
  SG_ NumACchargeStarts_BLMS : 23|12@0+ (10,0) [0|40000] "wu" A_IVC
  SG_ NumEPTglobalDerating_BLMS : 52|13@0+ (10,0) [0|50000] "wu" A_IVC

BO_ 1620 HEVC_A37: 8 CGW
  SG_ HVBatterySOC_BLMS : 7|7@0+ (1,0) [0|100] "%" A_IVC
  SG_ FreeDistanceZEVSinceECOreset : 15|13@0+ (0.1,0) [0|800] "wu" A_IVC
  SG_ NumHVbattRelaysOpening_BLMS : 55|15@0+ (10,0) [0|300000] "wu" A_IVC

BO_ 1621 HEVC_N106: 8 CGW
  SG_ OBFCM_TotalDistance_Lifetime : 7|32@0+ (0.1,0) [0|4.294967295E8] "km" A_IVC
  SG_ OBFCM_TotalFuelConsumed_Lifetime : 39|32@0+ (0.01,0) [0|4.294967295E7] "L" A_IVC

BO_ 1623 CPLC_A106: 8 CGW
  SG_ Combo_EVSEMaximumCurrentLimit_v2 : 7|13@0+ (0.1,0) [0|800] "A" A_IVC
  SG_ Combo_EVSEMaximumPowerLimit_v2 : 10|13@0+ (50,0) [0|400000] "W" A_IVC

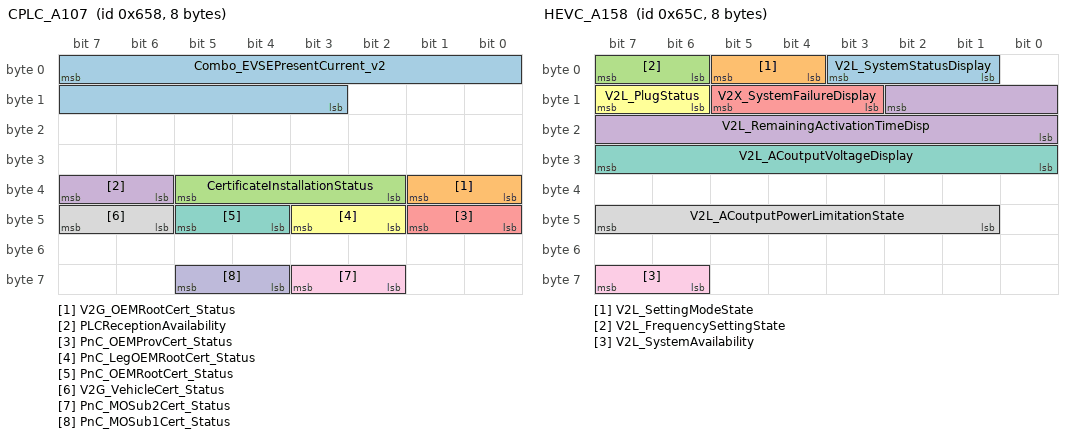
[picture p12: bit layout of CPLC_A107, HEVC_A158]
BO_ 1624 CPLC_A107: 8 CGW
  SG_ Combo_EVSEPresentCurrent_v2 : 7|13@0+ (0.1,0) [0|800] "A" A_IVC
  SG_ V2G_OEMRootCert_Status : 33|2@0+ (1,0) [0|0] "" A_IVC
  SG_ CertificateInstallationStatus : 37|4@0+ (1,0) [0|0] "" A_IVC
  SG_ PLCReceptionAvailability : 39|2@0+ (1,0) [0|0] "" A_IVC
  SG_ PnC_OEMProvCert_Status : 41|2@0+ (1,0) [0|0] "" A_IVC
  SG_ PnC_LegOEMRootCert_Status : 43|2@0+ (1,0) [0|0] "" A_IVC
  SG_ PnC_OEMRootCert_Status : 45|2@0+ (1,0) [0|0] "" A_IVC
  SG_ V2G_VehicleCert_Status : 47|2@0+ (1,0) [0|0] "" A_IVC
  SG_ PnC_MOSub2Cert_Status : 59|2@0+ (1,0) [0|0] "" A_IVC
  SG_ PnC_MOSub1Cert_Status : 61|2@0+ (1,0) [0|0] "" A_IVC

BO_ 1625 CPLC_A109: 8 CGW
  SG_ V2G_EVSEmaximumDischargePower_v2 : 7|13@0+ (0.05,-400) [-400|0] "kW" A_IVC
  SG_ V2X_EVSEmaximumChargePower : 10|13@0+ (0.05,0) [0|400] "kW" A_IVC
  SG_ PnC_Contract_Certificate_Status : 57|2@0+ (1,0) [0|0] "" A_IVC

BO_ 1628 HEVC_A158: 8 CGW
  SG_ V2L_SystemStatusDisplay : 3|3@0+ (1,0) [0|0] "" A_IVC
  SG_ V2L_SettingModeState : 5|2@0+ (1,0) [0|0] "" A_IVC
  SG_ V2L_FrequencySettingState : 7|2@0+ (1,0) [0|0] "" A_IVC
  SG_ V2L_RemainingActivationTimeDisp : 10|11@0+ (1,0) [0|2046] "min" A_IVC
  SG_ V2X_SystemFailureDisplay : 13|3@0+ (1,0) [0|0] "" A_IVC
  SG_ V2L_PlugStatus : 15|2@0+ (1,0) [0|0] "" A_IVC
  SG_ V2L_ACoutputVoltageDisplay : 31|8@0+ (2,0) [0|500] "V" A_IVC
  SG_ V2L_ACoutputPowerLimitationState : 47|7@0+ (0.1,0) [0|10] "kW" A_IVC
  SG_ V2L_SystemAvailability : 63|2@0+ (1,0) [0|0] "" A_IVC

BO_ 1633 CPLC_A110: 4 CGW
  SG_ V2G_Vehicle_CertifStatus : 21|4@0+ (1,0) [0|0] "" A_IVC
  SG_ PnCCPLCActivationStatus : 25|2@0+ (1,0) [0|0] "" A_IVC

BO_ 1634 VDC_R14: 6 CGW
  SG_ LateralTilt_MMI : 7|7@0+ (1,-60) [-60|60] "°" A_IVC
  SG_ LongitudinalTilt_MMI : 15|7@0+ (1,-60) [-60|60] "°" A_IVC

BO_ 1635 HEVC_A162: 6 CGW
  SG_ V2X_HVBat_EnergyDurabilityWarn : 10|2@0+ (1,0) [0|0] "" A_IVC
  SG_ V2X_HVBat_EnergyDurabilityCount : 23|15@0+ (5,0) [0|150000] "KWh" A_IVC
  SG_ StateOfCertifiedEnergy_v2 : 39|8@0+ (0.4,0) [0|100] "%" A_IVC
  SG_ StateOfCertifiedRange_v2 : 47|8@0+ (0.4,0) [0|100] "%" A_IVC

BO_ 1636 PBD_A102: 2 CGW
  SG_ PBD_ActivationState : 1|3@0+ (1,0) [0|0] "" VKM

BO_ 1637 CDM_A112: 8 CGW
  SG_ SuspensionSettingState : 12|3@0+ (1,0) [0|0] "" A_IVC
  SG_ DriveModeState : 28|5@0+ (1,0) [0|0] "" A_IVC

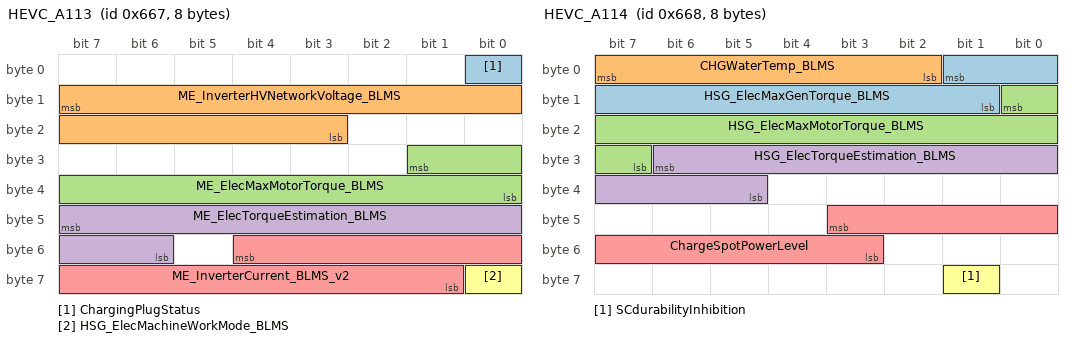
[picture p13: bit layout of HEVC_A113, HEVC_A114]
BO_ 1639 HEVC_A113: 8 CGW
  SG_ ChargingPlugStatus : 0|1@0+ (1,0) [0|0] "" A_IVC
  SG_ ME_InverterHVNetworkVoltage_BLMS : 15|13@0+ (0.1,0) [0|500] "V" A_IVC
  SG_ ME_ElecMaxMotorTorque_BLMS : 25|10@0+ (0.5,-255) [-255|254] "Nm" A_IVC
  SG_ ME_ElecTorqueEstimation_BLMS : 47|10@0+ (0.5,-255) [-255|250] "Nm" A_IVC
  SG_ ME_InverterCurrent_BLMS_v2 : 52|12@0+ (0.5,-550) [-550|550] "A" A_IVC
  SG_ HSG_ElecMachineWorkMode_BLMS : 56|1@0+ (1,0) [0|0] "" A_IVC

BO_ 1640 HEVC_A114: 8 CGW
  SG_ HSG_ElecMaxGenTorque_BLMS : 1|9@0+ (0.5,0) [0|250] "Nm" A_IVC
  SG_ CHGWaterTemp_BLMS : 7|6@0+ (2,-33) [-33|93] "°C" A_IVC
  SG_ HSG_ElecMaxMotorTorque_BLMS : 8|10@0+ (0.5,-255) [-255|254] "Nm" A_IVC
  SG_ HSG_ElecTorqueEstimation_BLMS : 30|10@0+ (0.5,-255) [-255|250] "Nm" A_IVC
  SG_ ChargeSpotPowerLevel : 43|9@0+ (0.3,0) [0|150] "kW" A_IVC
  SG_ SCdurabilityInhibition : 57|1@0+ (1,0) [0|0] "" A_IVC

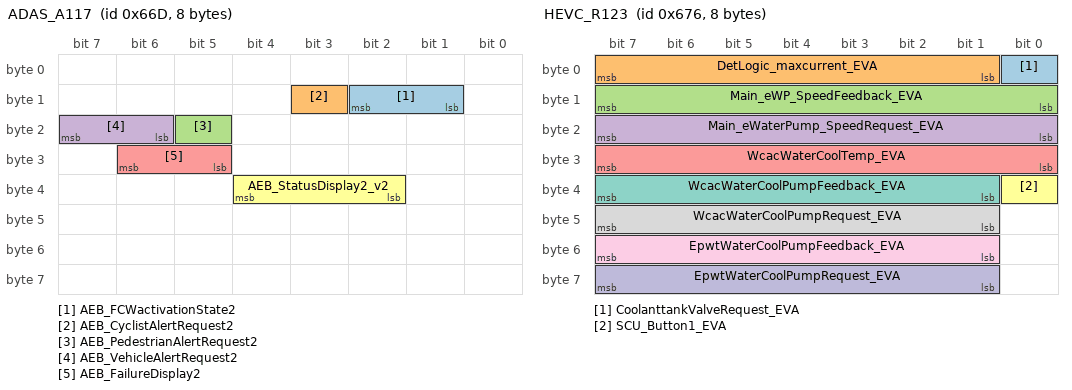
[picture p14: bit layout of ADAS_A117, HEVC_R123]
BO_ 1645 ADAS_A117: 8 CGW
  SG_ AEB_FCWactivationState2 : 10|2@0+ (1,0) [0|0] "" A_IVC
  SG_ AEB_CyclistAlertRequest2 : 11|1@0+ (1,0) [0|0] "" A_IVC
  SG_ AEB_PedestrianAlertRequest2 : 21|1@0+ (1,0) [0|0] "" A_IVC
  SG_ AEB_VehicleAlertRequest2 : 23|2@0+ (1,0) [0|0] "" A_IVC
  SG_ AEB_FailureDisplay2 : 30|2@0+ (1,0) [0|0] "" A_IVC
  SG_ AEB_StatusDisplay2_v2 : 36|3@0+ (1,0) [0|0] "" A_IVC

BO_ 1647 HEVC_A39: 8 CGW
  SG_ ME_RotorTemp_BLMS : 7|8@0+ (1,-40) [-40|215] "°C" A_IVC
  SG_ ME_StatorTemp_BLMS : 15|8@0+ (1,-40) [-40|215] "°C" A_IVC
  SG_ ME_SafetyMinTorque_BLMS : 21|10@0+ (0.5,-300) [-300|0] "Nm" A_IVC
  SG_ ME_SafetyMaxTorque_BLMS : 27|10@0+ (0.5,0) [0|500] "Nm" A_IVC
  SG_ HSG_SafetyMinTorque_BLMS : 33|10@0+ (0.5,-300) [-300|0] "Nm" A_IVC
  SG_ HSG_SafetyMaxTorque_BLMS : 55|10@0+ (0.5,0) [0|500] "Nm" A_IVC

BO_ 1650 DVR_N102: 8 CGW
  SG_ ConnectionData_DVR_WiFi : 7|48@0+ (1,0) [0|0] "" A_IVC
  SG_ DVR_Incident_state : 49|2@0+ (1,0) [0|0] "" A_IVC
  SG_ DataLength_DVR_WiFi : 55|6@0+ (1,0) [0|0] "" A_IVC
  SG_ TransportContent_DVR_WiFi : 59|2@0+ (1,0) [0|0] "" A_IVC
  SG_ DataIndex_DVR_WiFi : 63|4@0+ (1,0) [0|0] "" A_IVC

BO_ 1653 IVI_R109: 2 CGW
  SG_ SC_TargetSOC_EVA : 15|5@0+ (5,0) [0|100] "%" A_IVC

BO_ 1654 HEVC_R123: 8 CGW
  SG_ CoolanttankValveRequest_EVA : 0|1@0+ (1,0) [0|0] "" A_IVC
  SG_ DetLogic_maxcurrent_EVA : 7|7@0+ (1,0) [0|100] "A" A_IVC
  SG_ Main_eWP_SpeedFeedback_EVA : 15|8@0+ (50,0) [0|12500] "rpm" A_IVC
  SG_ Main_eWaterPump_SpeedRequest_EVA : 23|8@0+ (50,0) [0|12500] "rpm" A_IVC
  SG_ WcacWaterCoolTemp_EVA : 31|8@0+ (1,-50) [-50|200] "°C" A_IVC
  SG_ SCU_Button1_EVA : 32|1@0+ (1,0) [0|0] "" A_IVC
  SG_ WcacWaterCoolPumpFeedback_EVA : 39|7@0+ (1,0) [0|100] "pwm" A_IVC
  SG_ WcacWaterCoolPumpRequest_EVA : 47|7@0+ (1,0) [0|100] "pwm" A_IVC
  SG_ EpwtWaterCoolPumpFeedback_EVA : 55|7@0+ (1,0) [0|100] "pwm" A_IVC
  SG_ EpwtWaterCoolPumpRequest_EVA : 63|7@0+ (1,0) [0|100] "pwm" A_IVC

BO_ 1655 HEVC_A163: 8 CGW
  SG_ EVchargingProfileDuration_v2 : 7|16@0+ (10,0) [0|604800] "s" A_IVC
  SG_ EVchargingProfileStatus : 18|3@0+ (1,0) [0|0] "" A_IVC
  SG_ EVchargingProfileSlotNumber : 23|5@0+ (1,0) [0|24] "" A_IVC
  SG_ EVchargingProfilePower_v2 : 31|12@0+ (100,0) [0|400000] "W" A_IVC

BO_ 1659 HFM_A102: 5 CGW
  SG_ IKeyCardDetectionStatus : 3|2@0+ (1,0) [0|0] "" A_IVC,BLM

BO_ 1660 HVAC_A102: 8 CGW
  SG_ SecondRowRightSeatStatus : 4|3@0+ (1,0) [0|0] "" A_IVC
  SG_ SecondRowLeftSeatStatus : 7|3@0+ (1,0) [0|0] "" A_IVC
  SG_ ThirdRowRightSeatStatus : 12|3@0+ (1,0) [0|0] "" A_IVC
  SG_ ThirdRowLeftSeatStatus : 15|3@0+ (1,0) [0|0] "" A_IVC
  SG_ ClimSyncDisplay : 59|2@0+ (1,0) [0|0] "" A_IVC

BO_ 1661 IVI_N104: 8 CGW
  SG_ AltitudePosition : 7|16@0+ (0.1,-500) [-500|3000] "m" A_IVC

BO_ 1662 IVI_A102: 8 CGW
  SG_ ClimClearnessPush : 24|1@0+ (1,0) [0|1] "-" A_IVC
  SG_ ClimForcedRecyclingPush : 36|1@0+ (1,0) [0|1] "-" A_IVC

BO_ 1667 PSDL_A102: 3 CGW
  SG_ PSD_L_ActivationState : 7|3@0+ (1,0) [0|0] "" VKM

BO_ 1668 ECM_A123: 8 CGW
  SG_ CellHighestVoltageIDBLMS_BMS_48V : 7|8@0+ (1,0) [0|255] "-" A_IVC
  SG_ CellLowestVoltageIDBLMS_BMS_48V : 15|8@0+ (1,0) [0|255] "-" A_IVC
  SG_ MaxTempProbeID_BLMS_BMS_48V : 23|8@0+ (1,0) [0|255] "-" A_IVC
  SG_ MinTempProbeID_BLMS_BMS_48V : 31|8@0+ (1,0) [0|255] "-" A_IVC

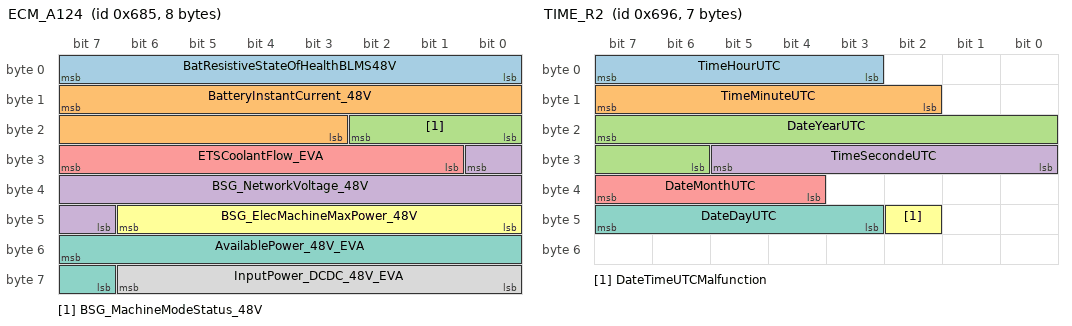
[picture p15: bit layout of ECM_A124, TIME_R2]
BO_ 1669 ECM_A124: 8 CGW
  SG_ BatResistiveStateOfHealthBLMS48V : 7|8@0+ (1,100) [100|354] "%" A_IVC
  SG_ BatteryInstantCurrent_48V : 15|13@0+ (0.25,-1000) [-1000|1000] "A" A_IVC
  SG_ BSG_MachineModeStatus_48V : 18|3@0+ (1,0) [0|0] "" A_IVC
  SG_ BSG_NetworkVoltage_48V : 24|10@0+ (0.1,0) [0|60] "V" A_IVC
  SG_ ETSCoolantFlow_EVA : 31|7@0+ (0.2,0) [0|20] "L/min" A_IVC
  SG_ BSG_ElecMachineMaxPower_48V : 46|7@0+ (0.25,0) [0|25] "kW" A_IVC
  SG_ AvailablePower_48V_EVA : 55|9@0+ (0.125,0) [0|50] "kW" A_IVC
  SG_ InputPower_DCDC_48V_EVA : 62|7@0+ (0.1,-6) [-6|6] "kW" A_IVC

BO_ 1670 IVI_A130: 8 CGW
  SG_ LOB_PositionSaveRequest : 50|3@0+ (1,0) [0|0] "" A_IVC
  SG_ LOB_PositionRecallRequest : 53|3@0+ (1,0) [0|0] "" A_IVC

BO_ 1682 HVAC_A6: 2 CGW
  SG_ ClimHeatedSteeringWheelDisplay : 5|2@0+ (1,0) [0|0] "" A_IVC
  SG_ ClimDualModeDisplay_v2 : 7|2@0+ (1,0) [0|0] "" A_IVC
  SG_ HVAC_PresoakStateDisplay : 15|2@0+ (1,0) [0|0] "" A_IVC

BO_ 1684 AVM_A118: 3 CGW
  SG_ APA_WarningDisplayRequest : 7|6@0+ (1,0) [0|0] "" A_IVC
  SG_ HFP_MapContentDisplay2 : 10|2@0+ (1,0) [0|0] "" A_IVC

BO_ 1685 CGW_A2: 4 CGW
  SG_ CGW_FOTAstatus_v2 : 22|5@0+ (1,0) [0|0] "" A_IVC

BO_ 1686 TIME_R2: 7 A_IVC
  SG_ TimeHourUTC : 7|5@0+ (1,0) [0|23] "h" CGW,VKM
  SG_ TimeMinuteUTC : 15|6@0+ (1,0) [0|59] "min" CGW,VKM
  SG_ DateYearUTC : 23|10@0+ (1,2000) [2000|3000] "year" CGW,VKM
  SG_ TimeSecondeUTC : 29|6@0+ (1,0) [0|59] "s" CGW,VKM
  SG_ DateMonthUTC : 39|4@0+ (1,0) [0|12] "month" CGW,VKM
  SG_ DateTimeUTCMalfunction : 42|1@0+ (1,0) [0|0] "" CGW,VKM
  SG_ DateDayUTC : 47|5@0+ (1,0) [0|31] "day" CGW,VKM

BO_ 1690 METER_A8: 7 CGW
  SG_ InstantConsumptionICEdisplay : 31|10@0+ (0.1,0) [0|102.3] "" A_IVC
  SG_ TripDistanceZEV : 37|17@0+ (0.1,0) [0|10000] "-" A_IVC

BO_ 1703 BCM_R14: 6 CGW
  SG_ ChargeAuthorization_BCM_v2 : 43|3@0+ (1,0) [0|0] "" A_IVC
  SG_ ProgrammedChargeStatus : 45|2@0+ (1,0) [0|0] "" A_IVC

BO_ 1705 FrCamADAS_R102: 7 CGW
  SG_ ISA_ActivationRatio : 1|10@0+ (0.1,0) [0|100] "-" A_IVC
  SG_ ISA_DeactivationRatio : 23|10@0+ (0.1,0) [0|100] "-" A_IVC
  SG_ ISA_FailureRatio : 29|10@0+ (0.1,0) [0|100] "-" A_IVC
  SG_ ISA_SpeedLimitDisplayedRatio : 35|10@0+ (0.1,0) [0|100] "-" A_IVC
  SG_ ISA_SpeedLimitOverriddenRatio : 41|10@0+ (0.1,0) [0|100] "-" A_IVC

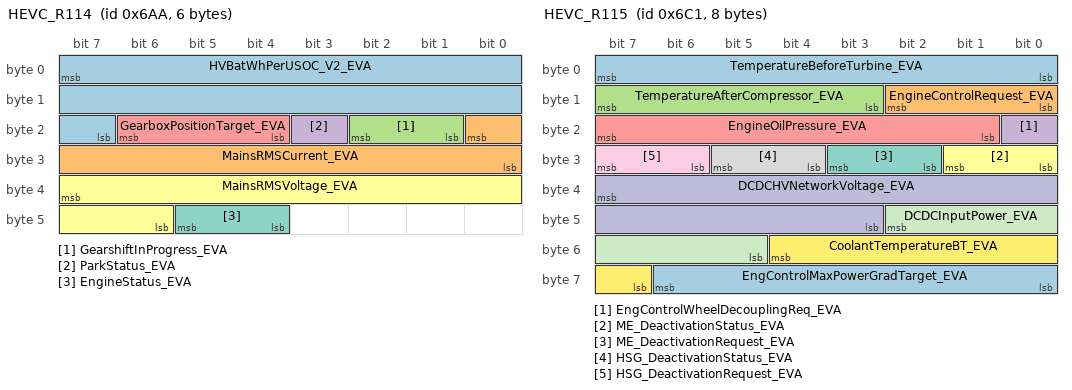
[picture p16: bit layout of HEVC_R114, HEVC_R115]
BO_ 1706 HEVC_R114: 6 CGW
  SG_ HVBatWhPerUSOC_V2_EVA : 7|17@0+ (0.01,0) [0|800] "(W.h)/%" A_IVC
  SG_ MainsRMSCurrent_EVA : 16|9@0+ (0.1,0) [0|51] "A" A_IVC
  SG_ GearshiftInProgress_EVA : 18|2@0+ (1,0) [0|0] "" A_IVC
  SG_ ParkStatus_EVA : 19|1@0+ (1,0) [0|0] "" A_IVC
  SG_ GearboxPositionTarget_EVA : 22|3@0+ (1,0) [0|0] "" A_IVC
  SG_ MainsRMSVoltage_EVA : 39|10@0+ (0.5,0) [0|500] "V" A_IVC
  SG_ EngineStatus_EVA : 45|2@0+ (1,0) [0|0] "" A_IVC

BO_ 1720 METER_UserSetPref_A6: 3 CGW
  SG_ ADB_ActivationRequest : 1|2@0+ (1,0) [0|0] "" A_IVC
  SG_ HandDrivingActivationRequest : 17|2@0+ (1,0) [0|0] "" A_IVC

BO_ 1725 BMS12V_A2: 7 CGW
  SG_ BMS12V_StorageTemperature : 7|8@0+ (0.5,-45) [-45|80] "°C" A_IVC
  SG_ BMS12V_StorageSOH_R : 21|6@0+ (1,100) [100|160] "%" A_IVC
  SG_ BMS12V_cumulated_Ah : 35|10@0+ (300,0) [0|300000] "Ah" A_IVC
  SG_ BMS12V_cells_maxDeltaVoltage : 41|9@0+ (0.005,0) [0|2] "V" A_IVC

BO_ 1727 HEVC_R121: 8 CGW
  SG_ V2G_EVmaxDischargePower_v2_EVA : 7|13@0+ (0.05,-400) [-400|0] "kW" A_IVC
  SG_ V2G_EVminDischargePower_v2_EVA : 10|13@0+ (0.05,-400) [-400|0] "kW" A_IVC
  SG_ EV_PresentActivePower_EVA : 29|13@0+ (0.05,-200) [-200|200] "kW" A_IVC
  SG_ EV_PresentReactivePower_EVA : 32|13@0+ (0.05,-200) [-200|200] "kVAR" A_IVC

BO_ 1729 HEVC_R115: 8 CGW
  SG_ TemperatureBeforeTurbine_EVA : 7|8@0+ (5,0) [0|1100] "°C" A_IVC
  SG_ EngineControlRequest_EVA : 10|3@0+ (1,0) [0|0] "" A_IVC
  SG_ TemperatureAfterCompressor_EVA : 15|5@0+ (10,0) [0|210] "°C" A_IVC
  SG_ EngControlWheelDecouplingReq_EVA : 16|1@0+ (1,0) [0|0] "" A_IVC
  SG_ EngineOilPressure_EVA : 23|7@0+ (0.1,0) [0|12.6] "bar" A_IVC
  SG_ ME_DeactivationStatus_EVA : 25|2@0+ (1,0) [0|0] "" A_IVC
  SG_ ME_DeactivationRequest_EVA : 27|2@0+ (1,0) [0|0] "" A_IVC
  SG_ HSG_DeactivationStatus_EVA : 29|2@0+ (1,0) [0|0] "" A_IVC
  SG_ HSG_DeactivationRequest_EVA : 31|2@0+ (1,0) [0|0] "" A_IVC
  SG_ DCDCHVNetworkVoltage_EVA : 39|13@0+ (0.1,0) [0|500] "V" A_IVC
  SG_ DCDCInputPower_EVA : 42|6@0+ (0.1,0) [0|6] "kW" A_IVC
  SG_ CoolantTemperatureBT_EVA : 52|6@0+ (1,-30) [-30|20] "°C" A_IVC
  SG_ EngControlMaxPowerGradTarget_EVA : 62|7@0+ (500,0) [0|50000] "Watt/s" A_IVC

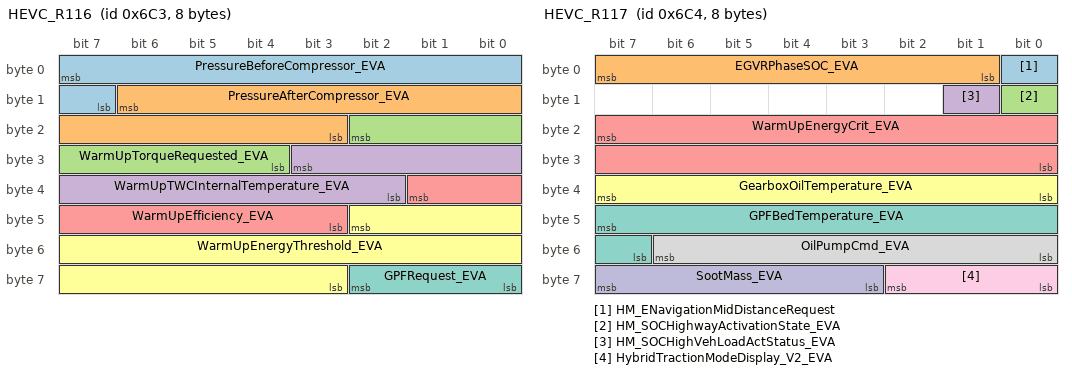
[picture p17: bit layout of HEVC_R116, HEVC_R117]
BO_ 1731 HEVC_R116: 8 CGW
  SG_ PressureBeforeCompressor_EVA : 7|9@0+ (1,500) [500|1000] "mbar" A_IVC
  SG_ PressureAfterCompressor_EVA : 14|12@0+ (1,500) [500|3500] "mbar" A_IVC
  SG_ WarmUpTorqueRequested_EVA : 18|7@0+ (5,0) [0|500] "Nm" A_IVC
  SG_ WarmUpTWCInternalTemperature_EVA : 27|10@0+ (2,0) [0|1050] "°C" A_IVC
  SG_ WarmUpEfficiency_EVA : 33|7@0+ (0.01,0) [0|1] "-" A_IVC
  SG_ WarmUpEnergyThreshold_EVA : 42|16@0+ (1,0) [0|65535] "-" A_IVC
  SG_ GPFRequest_EVA : 58|3@0+ (1,0) [0|0] "" A_IVC

BO_ 1732 HEVC_R117: 8 CGW
  SG_ HM_ENavigationMidDistanceRequest : 0|1@0+ (1,0) [0|0] "" A_IVC
  SG_ EGVRPhaseSOC_EVA : 7|7@0+ (1,0) [0|100] "%" A_IVC
  SG_ HM_SOCHighwayActivationState_EVA : 8|1@0+ (1,0) [0|0] "" A_IVC
  SG_ HM_SOCHighVehLoadActStatus_EVA : 9|1@0+ (1,0) [0|0] "" A_IVC
  SG_ WarmUpEnergyCrit_EVA : 23|16@0+ (1,0) [0|65535] "-" A_IVC
  SG_ GearboxOilTemperature_EVA : 39|8@0+ (1,-40) [-40|214] "°C" A_IVC
  SG_ GPFBedTemperature_EVA : 47|9@0+ (5,0) [0|1400] "°C" A_IVC
  SG_ OilPumpCmd_EVA : 54|7@0+ (1,0) [0|100] "%" A_IVC
  SG_ HybridTractionModeDisplay_V2_EVA : 58|3@0+ (1,0) [0|0] "" A_IVC
  SG_ SootMass_EVA : 63|5@0+ (1,0) [0|20] "g" A_IVC

BO_ 1736 HEVC_A21: 8 CGW
  SG_ BMS_MinTempProbeID_BLMS : 7|8@0+ (1,0) [0|255] "" A_IVC
  SG_ BMS_MaxTempProbeID_BLMS : 15|8@0+ (1,0) [0|255] "" A_IVC
  SG_ BMS_CellHighestVoltageID_BLMS : 23|8@0+ (1,0) [0|255] "" A_IVC
  SG_ BMS_CellLowestVoltageID_BLMS : 31|8@0+ (1,0) [0|255] "" A_IVC
  SG_ HVBatSerialNumber_BLMS : 39|32@0+ (1,0) [0|4294967294] "" A_IVC

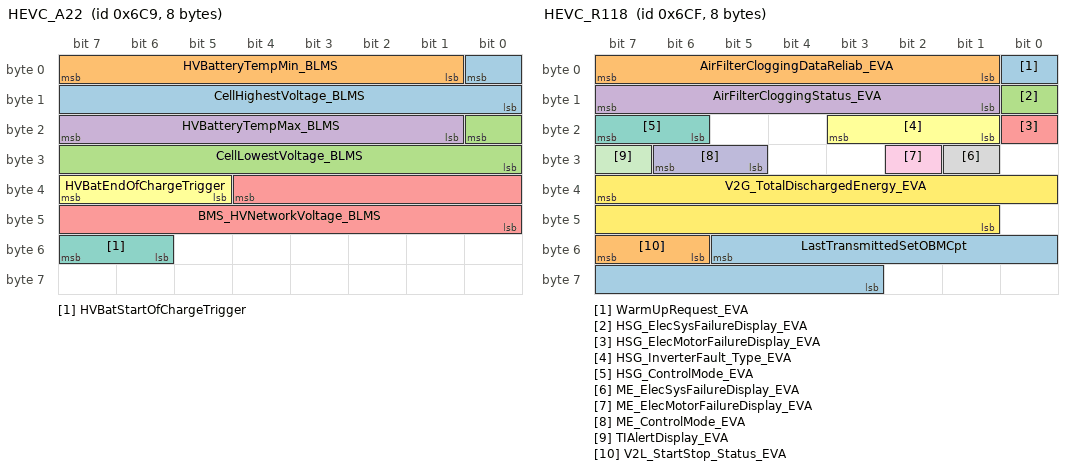
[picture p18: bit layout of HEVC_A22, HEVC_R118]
BO_ 1737 HEVC_A22: 8 CGW
  SG_ CellHighestVoltage_BLMS : 0|9@0+ (0.01,1) [1|5] "V" A_IVC
  SG_ HVBatteryTempMin_BLMS : 7|7@0+ (1,-40) [-40|80] "°C" A_IVC
  SG_ CellLowestVoltage_BLMS : 16|9@0+ (0.01,1) [1|5] "V" A_IVC
  SG_ HVBatteryTempMax_BLMS : 23|7@0+ (1,-40) [-40|80] "°C" A_IVC
  SG_ BMS_HVNetworkVoltage_BLMS : 36|13@0+ (0.1,0) [0|500] "V" A_IVC
  SG_ HVBatEndOfChargeTrigger : 39|3@0+ (1,0) [0|0] "" A_IVC
  SG_ HVBatStartOfChargeTrigger : 55|2@0+ (1,0) [0|0] "" A_IVC

BO_ 1738 METER_A105: 8 CGW
  SG_ VirtualKeySuspendReq : 3|2@0+ (1,0) [0|0] "" BLM
  SG_ CASP_ActivationRequest : 51|2@0+ (1,0) [0|0] "" A_IVC

BO_ 1742 ADAS_A124: 8 CGW
  SG_ ACC_CancelReason_v2 : 7|5@0+ (1,0) [0|0] "" A_IVC
  SG_ AEB_CancelReason_v2 : 15|4@0+ (1,0) [0|0] "" A_IVC
  SG_ LCA_CancelReason : 31|4@0+ (1,0) [0|0] "" A_IVC
  SG_ OSE_CancelReason : 34|3@0+ (1,0) [0|0] "" A_IVC
  SG_ ELKA_CancelReason_v2 : 43|4@0+ (1,0) [0|0] "" A_IVC

BO_ 1743 HEVC_R118: 8 CGW
  SG_ WarmUpRequest_EVA : 0|1@0+ (1,0) [0|0] "" A_IVC
  SG_ AirFilterCloggingDataReliab_EVA : 7|7@0+ (1,0) [0|100] "%" A_IVC
  SG_ HSG_ElecSysFailureDisplay_EVA : 8|1@0+ (1,0) [0|0] "" A_IVC
  SG_ AirFilterCloggingStatus_EVA : 15|7@0+ (1,0) [0|100] "%" A_IVC
  SG_ HSG_ElecMotorFailureDisplay_EVA : 16|1@0+ (1,0) [0|0] "" A_IVC
  SG_ HSG_InverterFault_Type_EVA : 19|3@0+ (1,0) [0|0] "" A_IVC
  SG_ HSG_ControlMode_EVA : 23|2@0+ (1,0) [0|0] "" A_IVC
  SG_ ME_ElecSysFailureDisplay_EVA : 25|1@0+ (1,0) [0|0] "" A_IVC
  SG_ ME_ElecMotorFailureDisplay_EVA : 26|1@0+ (1,0) [0|0] "" A_IVC
  SG_ ME_ControlMode_EVA : 30|2@0+ (1,0) [0|0] "" A_IVC
  SG_ TIAlertDisplay_EVA : 31|1@0+ (1,0) [0|0] "" A_IVC
  SG_ V2G_TotalDischargedEnergy_EVA : 39|15@0+ (5,0) [0|150000] "KWh" A_IVC
  SG_ LastTransmittedSetOBMCpt : 53|11@0+ (1,0) [0|2047] "wu" A_IVC
  SG_ V2L_StartStop_Status_EVA : 55|2@0+ (1,0) [0|0] "" A_IVC

BO_ 1746 CPLC_R102: 6 CGW
  SG_ EVSE_TargetActivePower_v2_EVA : 7|19@0+ (0.001,-200) [-200|200] "kW" A_IVC
  SG_ EVSE_TargetReactivePower_v2_EVA : 20|19@0+ (0.001,-200) [-200|200] "kVAR" A_IVC

BO_ 1748 HFM_VKM_pairing_Frame: 8 CGW
  SG_ HFM_VKM_pairing : 7|64@0+ (1,0) [0|0] "" VKM

BO_ 1749 VKM_N112: 8 VKM
  SG_ VKM_HFM_pairing : 7|64@0+ (1,0) [0|0] "" CGW

BO_ 1753 CPLC_A103: 7 CGW
  SG_ CPLC_FaultType : 51|4@0+ (1,0) [0|0] "" A_IVC

BO_ 1754 CPLC_A104: 8 CGW
  SG_ EVSE_ACmaxCurrent : 30|12@0+ (0.1,0) [0|400] "A" A_IVC
  SG_ PnC_ContractRevocation_Status : 32|1@0+ (1,0) [0|0] "" A_IVC
  SG_ PnC_V2GRootCert_Status : 34|2@0+ (1,0) [0|0] "" A_IVC
  SG_ EVSE_ACnominalVoltage : 47|14@0+ (0.1,0) [0|1000] "V" A_IVC

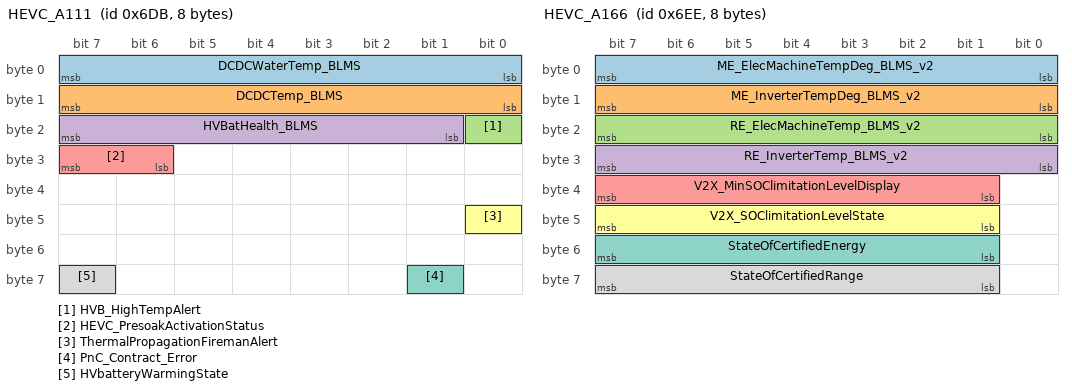
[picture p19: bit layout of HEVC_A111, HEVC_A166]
BO_ 1755 HEVC_A111: 8 CGW
  SG_ DCDCWaterTemp_BLMS : 7|8@0+ (1,-40) [-40|214] "°" A_IVC
  SG_ DCDCTemp_BLMS : 15|8@0+ (1,-40) [-40|214] "°C" A_IVC
  SG_ HVB_HighTempAlert : 16|1@0+ (1,0) [0|0] "" A_IVC
  SG_ HVBatHealth_BLMS : 23|7@0+ (1,0) [0|126] "%" A_IVC
  SG_ HEVC_PresoakActivationStatus : 31|2@0+ (1,0) [0|0] "" A_IVC
  SG_ ThermalPropagationFiremanAlert : 40|1@0+ (1,0) [0|0] "" A_IVC
  SG_ PnC_Contract_Error : 57|1@0+ (1,0) [0|0] "" A_IVC
  SG_ HVbatteryWarmingState : 63|1@0+ (1,0) [0|0] "" A_IVC

BO_ 1756 METER_A109: 8 CGW
  SG_ Privacy_Mode_Request : 55|3@0+ (1,0) [0|0] "" A_IVC

BO_ 1772 METER_A110: 8 CGW
  SG_ FuelGaugeDisplayValue : 47|7@0+ (1,0) [0|100] "%" A_IVC

BO_ 1774 HEVC_A166: 8 CGW
  SG_ ME_ElecMachineTempDeg_BLMS_v2 : 7|8@0+ (0.5,0) [0|100] "%" A_IVC
  SG_ ME_InverterTempDeg_BLMS_v2 : 15|8@0+ (0.5,0) [0|100] "%" A_IVC
  SG_ RE_ElecMachineTemp_BLMS_v2 : 23|8@0+ (0.5,0) [0|100] "%" A_IVC
  SG_ RE_InverterTemp_BLMS_v2 : 31|8@0+ (0.5,0) [0|100] "%" A_IVC
  SG_ V2X_MinSOClimitationLevelDisplay : 39|7@0+ (1,0) [0|100] "%" A_IVC
  SG_ V2X_SOClimitationLevelState : 47|7@0+ (1,0) [0|100] "%" A_IVC
  SG_ StateOfCertifiedEnergy : 55|7@0+ (1,0) [0|100] "%" A_IVC
  SG_ StateOfCertifiedRange : 63|7@0+ (1,0) [0|100] "%" A_IVC

BO_ 1775 TCU_A106: 3 A_IVC
  SG_ PnCcertificateTotalBlockNb_v2 : 7|12@0+ (1,0) [0|4095] "" CGW
  SG_ PnC_IVC_Transfer_Status_V2 : 11|3@0+ (1,0) [0|0] "" CGW
  SG_ ISA_ReportingActivationRequest : 23|2@0+ (1,0) [0|0] "" CGW

BO_ 1778 HEVC_R122: 8 CGW
  SG_ CustomerDepartureTime_EVA : 7|13@0+ (10,0) [0|10080] "min" A_IVC
  SG_ HeatingGridCurrentRequest_EVA : 54|9@0+ (0.1,0) [0|50] "A" A_IVC

BO_ 1779 IVI_R8: 8 CGW
  SG_ ChargeCalAllChange_MMI : 58|2@0+ (1,0) [0|0] "" A_IVC

BO_ 1781 IVI_R10: 8 CGW
  SG_ ChargeDelayedRequest : 46|1@0+ (1,0) [0|0] "" A_IVC
  SG_ ChargeAlwaysRequest : 47|1@0+ (1,0) [0|0] "" A_IVC

BO_ 1782 IVI_R11: 7 CGW
  SG_ PreSoakCalAllChange_MMI : 49|2@0+ (1,0) [0|0] "" A_IVC

BO_ 1789 BCM_A114: 8 CGW
  SG_ RESPreSoak_NextDriverArrivalTime_v2 : 13|14@0+ (1,0) [0|10080] "min" A_IVC
  SG_ BCM_SRU_SwitchState : 32|4@0+ (1,0) [0|0] "" VKM
  SG_ BCM_SRU_ECUDefect : 34|1@0+ (1,0) [0|0] "" VKM
  SG_ ChargeDelayedValue_V2 : 44|14@0+ (1,0) [0|10080] "min" A_IVC

BO_ 1790 HEVC_R108: 8 CGW
  SG_ RE_DeactivationStatus_EVA : 13|2@0+ (1,0) [0|0] "" A_IVC
  SG_ RE_DeactivationRequest_EVA : 15|2@0+ (1,0) [0|0] "" A_IVC
  SG_ PnCchargeStationCompatibility : 53|1@0+ (1,0) [0|0] "" A_IVC
  SG_ V2L_ActivationStatusFeedback_EVA : 58|2@0+ (1,0) [0|0] "" A_IVC

BO_ 1791 HEVC_R109: 8 CGW
  SG_ ME_ElecMachineTorque_BLMS : 46|11@0+ (0.5,-300) [-300|500] "Nm" A_IVC
  SG_ HSG_ElecMachineTorque_BLMS : 51|11@0+ (0.5,-300) [-300|500] "Nm" A_IVC
  SG_ RE_ElecMotorFailureDisplay_EVA : 56|1@0+ (1,0) [0|0] "" A_IVC

BO_ 1792 CDM_to_DTOOL: 8 CGW
  SG_ CDM_to_DTOOL : 7|64@0+ (1,0) [0|0] "" A_IVC

BO_ 1799 DTOOL_to_eHBox: 8 A_IVC
  SG_ DTOOL_to_eHBox : 7|64@0+ (1,0) [0|0] "" CGW

BO_ 1800 DTOOL_to_MID: 8 A_IVC
  SG_ DTOOL_to_MID : 7|64@0+ (1,0) [0|0] "" CGW

BO_ 1801 DTOOL_to_PSD: 8 A_IVC
  SG_ DTOOL_to_PSD : 7|64@0+ (1,0) [0|0] "" CGW

BO_ 1804 DTOOL_to_CDM: 8 A_IVC
  SG_ DTOOL_to_CDM : 7|64@0+ (1,0) [0|0] "" CGW

BO_ 1811 DTOOL_to_PBD: 8 A_IVC
  SG_ DTOOL_to_PBD : 7|64@0+ (1,0) [0|0] "" CGW

BO_ 1812 DTOOL_to_CPANEL: 8 A_IVC
  SG_ DTOOL_to_CPANEL : 7|64@0+ (1,0) [0|0] "" CGW

BO_ 1814 DTOOL_to_PSCU: 8 A_IVC
  SG_ DTOOL_to_PSCU : 7|64@0+ (1,0) [0|0] "" CGW

BO_ 1827 DTOOL_to_RADAR2: 8 A_IVC
  SG_ DTOOL_to_RADAR2 : 7|64@0+ (1,0) [0|0] "" CGW

BO_ 1832 MID_to_DTOOL: 8 CGW
  SG_ MID_to_DTOOL : 7|64@0+ (1,0) [0|0] "" A_IVC

BO_ 1833 PSD_to_DTOOL: 8 CGW
  SG_ PSD_to_DTOOL : 7|64@0+ (1,0) [0|0] "" A_IVC

BO_ 1843 PBD_to_DTOOL: 8 CGW
  SG_ PBD_to_DTOOL : 7|64@0+ (1,0) [0|0] "" A_IVC

BO_ 1844 CPANEL_to_DTOOL: 8 CGW
  SG_ CPANEL_to_DTOOL : 7|64@0+ (1,0) [0|0] "" A_IVC

BO_ 1845 RADAR2_to_DTOOL: 8 CGW
  SG_ RADAR2_to_DTOOL : 7|64@0+ (1,0) [0|0] "" A_IVC

BO_ 1846 PSCU_to_DTOOL: 8 CGW
  SG_ PSCU_to_DTOOL : 7|64@0+ (1,0) [0|0] "" A_IVC

BO_ 1853 DTOOL_to_SRad_RL: 8 A_IVC
  SG_ DTOOL_to_SRad_RL : 7|64@0+ (1,0) [0|0] "" CGW

BO_ 1854 SRad_RL_to_DTOOL: 8 CGW
  SG_ SRad_RL_to_DTOOL : 7|64@0+ (1,0) [0|0] "" A_IVC

BO_ 1855 DTOOL_to_VSP: 8 A_IVC
  SG_ DTOOL_to_VSP : 7|64@0+ (1,0) [0|0] "" CGW

BO_ 1858 DTOOL_to_EPS: 8 A_IVC
  SG_ DTOOL_to_EPS : 7|64@0+ (1,0) [0|0] "" CGW

BO_ 1859 DTOOL_to_METER: 8 A_IVC
  SG_ DTOOL_to_METER : 7|64@0+ (1,0) [0|0] "" CGW

BO_ 1860 DTOOL_to_HVAC: 8 A_IVC
  SG_ DTOOL_to_HVAC : 7|64@0+ (1,0) [0|0] "" CGW

BO_ 1861 DTOOL_to_BCM: 8 A_IVC
  SG_ DTOOL_to_BCM : 7|64@0+ (1,0) [0|0] "" CGW

BO_ 1862 DTOOL_to_DOP_TCU: 8 A_IVC
  SG_ DTOOL_to_DOP_TCU : 7|64@0+ (1,0) [0|0] "" CGW

BO_ 1863 DTOOL_to_NAV: 8 A_IVC
  SG_ DTOOL_to_NAV : 7|64@0+ (1,0) [0|0] "" CGW

BO_ 1864 DTOOL_to_4WD: 8 A_IVC
  SG_ DTOOL_to_4WD : 7|64@0+ (1,0) [0|0] "" CGW

BO_ 1865 DTOOL_to_ANC: 8 A_IVC
  SG_ DTOOL_to_ANC : 7|64@0+ (1,0) [0|0] "" CGW

BO_ 1869 DTOOL_to_USM: 8 A_IVC
  SG_ DTOOL_to_USM : 7|64@0+ (1,0) [0|0] "" CGW

BO_ 1870 DTOOL_to_SONAR: 8 A_IVC
  SG_ DTOOL_to_SONAR : 7|64@0+ (1,0) [0|0] "" CGW

BO_ 1871 DTOOL_to_DSMU: 8 A_IVC
  SG_ DTOOL_to_DSMU : 7|64@0+ (1,0) [0|0] "" CGW

BO_ 1874 DTOOL_to_ACU: 8 A_IVC
  SG_ DTOOL_to_ACU : 7|64@0+ (1,0) [0|0] "" CGW

BO_ 1875 DTOOL_to_FWS: 8 A_IVC
  SG_ DTOOL_to_FWS : 7|64@0+ (1,0) [0|0] "" CGW

BO_ 1876 DTOOL_to_PSB: 8 A_IVC
  SG_ DTOOL_to_PSB : 7|64@0+ (1,0) [0|0] "" CGW

BO_ 1881 DTOOL_to_PSD_L: 8 A_IVC
  SG_ DTOOL_to_PSD_L : 7|64@0+ (1,0) [0|0] "" CGW

BO_ 1884 DTOOL_to_AFS: 8 A_IVC
  SG_ DTOOL_to_AFS : 7|64@0+ (1,0) [0|0] "" CGW

BO_ 1889 VSP_to_DTOOL: 8 CGW
  SG_ VSP_to_DTOOL : 7|64@0+ (1,0) [0|0] "" A_IVC

BO_ 1890 EPS_to_DTOOL: 8 CGW
  SG_ EPS_to_DTOOL : 7|64@0+ (1,0) [0|0] "" A_IVC

BO_ 1891 METER_to_DTOOL: 8 CGW
  SG_ METER_to_DTOOL : 7|64@0+ (1,0) [0|0] "" A_IVC

BO_ 1892 HVAC_to_DTOOL: 8 CGW
  SG_ HVAC_to_DTOOL : 7|64@0+ (1,0) [0|0] "" A_IVC

BO_ 1893 BCM_to_DTOOL: 8 CGW
  SG_ BCM_to_DTOOL : 7|64@0+ (1,0) [0|0] "" A_IVC

BO_ 1895 NAV_to_DTOOL: 8 CGW
  SG_ NAV_to_DTOOL : 7|64@0+ (1,0) [0|0] "" A_IVC

BO_ 1896 FWD_to_DTOOL: 8 CGW
  SG_ FWD_to_DTOOL : 7|64@0+ (1,0) [0|0] "" A_IVC

BO_ 1901 USM_to_DTOOL: 8 CGW
  SG_ USM_to_DTOOL : 7|64@0+ (1,0) [0|0] "" A_IVC

BO_ 1902 SONAR_to_DTOOL: 8 CGW
  SG_ SONAR_to_DTOOL : 7|64@0+ (1,0) [0|0] "" A_IVC

BO_ 1903 DSMU_to_DTOOL: 8 CGW
  SG_ DSMU_to_DTOOL : 7|64@0+ (1,0) [0|0] "" A_IVC

BO_ 1906 ACU_to_DTOOL: 8 CGW
  SG_ ACU_to_DTOOL : 7|64@0+ (1,0) [0|0] "" A_IVC

BO_ 1907 FWS_to_DTOOL: 8 CGW
  SG_ FWS_to_DTOOL : 7|64@0+ (1,0) [0|0] "" A_IVC

BO_ 1908 PSB_to_DTOOL: 8 CGW
  SG_ PSB_to_DTOOL : 7|64@0+ (1,0) [0|0] "" A_IVC

BO_ 1913 PSD_L_to_DTOOL: 8 CGW
  SG_ PSD_L_to_DTOOL : 7|64@0+ (1,0) [0|0] "" A_IVC

BO_ 1916 AFS_to_DTOOL: 8 CGW
  SG_ AFS_to_DTOOL : 7|64@0+ (1,0) [0|0] "" A_IVC

BO_ 1922 DTOOL_to_AMPLI: 8 A_IVC
  SG_ DTOOL_to_AMPLI : 7|64@0+ (1,0) [0|0] "" CGW

BO_ 1925 DTOOL_to_HNS: 8 A_IVC
  SG_ DTOOL_to_HNS : 7|64@0+ (1,0) [0|0] "" CGW

BO_ 1928 DTOOL_to_SceneRecorder: 8 A_IVC
  SG_ DTOOL_to_SceneRecorder : 7|64@0+ (1,0) [0|0] "" CGW

BO_ 1945 DTOOL_to_HFM: 8 A_IVC
  SG_ DTOOL_to_HFM : 7|64@0+ (1,0) [0|0] "" CGW

BO_ 1949 DTOOL_to_SCU: 8 A_IVC
  SG_ DTOOL_to_SCU : 7|64@0+ (1,0) [0|0] "" CGW

BO_ 1954 AMPLI_to_DTOOL: 8 CGW
  SG_ AMPLI_to_DTOOL : 7|64@0+ (1,0) [0|0] "" A_IVC

BO_ 1957 HNS_to_DTOOL: 8 CGW
  SG_ HNS_to_DTOOL : 7|64@0+ (1,0) [0|0] "" A_IVC

BO_ 1960 SceneRecorder_to_DTOOL: 8 CGW
  SG_ SceneRecorder_to_DTOOL : 7|64@0+ (1,0) [0|0] "" A_IVC

BO_ 1962 DTOOL_to_WCBS: 8 A_IVC
  SG_ DTOOL_to_WCBS : 7|64@0+ (1,0) [0|0] "" CGW

BO_ 1965 WCBS_to_DTOOL: 8 CGW
  SG_ WCBS_to_DTOOL : 7|64@0+ (1,0) [0|0] "" A_IVC

BO_ 1975 DTOOL_to_AVM: 8 A_IVC
  SG_ DTOOL_to_AVM : 7|64@0+ (1,0) [0|0] "" CGW

BO_ 1977 HFM_to_DTOOL: 8 CGW
  SG_ HFM_to_DTOOL : 7|64@0+ (1,0) [0|0] "" A_IVC

BO_ 1978 AVM_to_DTOOL: 8 CGW
  SG_ AVM_to_DTOOL : 7|64@0+ (1,0) [0|0] "" A_IVC

BO_ 1981 SCU_to_DTOOL: 8 CGW
  SG_ SCU_to_DTOOL : 7|64@0+ (1,0) [0|0] "" A_IVC

BO_ 1987 DTOOL_to_ADAS: 8 A_IVC
  SG_ DTOOL_to_ADAS : 7|64@0+ (1,0) [0|0] "" CGW

BO_ 1988 eShifter_to_DTOOL: 8 CGW
  SG_ eShifter_to_DTOOL : 7|64@0+ (1,0) [0|0] "" A_IVC

BO_ 1989 DTOOL_to_eShifter: 8 A_IVC
  SG_ DTOOL_to_eShifter : 7|64@0+ (1,0) [0|0] "" CGW

BO_ 1992 CPLC_to_DTOOL: 8 CGW
  SG_ CPLC_to_DTOOL : 7|64@0+ (1,0) [0|0] "" A_IVC

BO_ 1994 DTOOL_to_A_IVC: 8 CGW
  SG_ DTOOL_to_A_IVC : 7|64@0+ (1,0) [0|0] "" A_IVC

BO_ 2004 DTOOL_to_SRad_RR: 8 A_IVC
  SG_ DTOOL_to_SRad_RR : 7|64@0+ (1,0) [0|0] "" CGW

BO_ 2005 SRad_RR_to_DTOOL: 8 CGW
  SG_ SRad_RR_to_DTOOL : 7|64@0+ (1,0) [0|0] "" A_IVC

BO_ 2008 DTOOL_to_CPLC: 8 A_IVC
  SG_ DTOOL_to_CPLC : 7|64@0+ (1,0) [0|0] "" CGW

BO_ 2010 A_IVC_to_DTOOL: 8 A_IVC
  SG_ A_IVC_to_DTOOL : 7|64@0+ (1,0) [0|0] "" CGW

BO_ 2012 DTOOL_to_FRCAMERA: 8 A_IVC
  SG_ DTOOL_to_FRCAMERA : 7|64@0+ (1,0) [0|0] "" CGW

BO_ 2013 FRCAMERA_to_DTOOL: 8 CGW
  SG_ FRCAMERA_to_DTOOL : 7|64@0+ (1,0) [0|0] "" A_IVC

BO_ 2549874689 CPLC_N101: 8 CGW
  SG_ Data_CPLC_ID : 7|56@0+ (1,0) [0|7.2057594037927904E16] "-" A_IVC
  SG_ DataLength_CPLC_ID : 60|5@0+ (1,0) [0|31] "-" A_IVC
  SG_ DataIndex_CPLC_ID : 63|3@0+ (1,0) [0|7] "-" A_IVC

BO_ 2549874701 HEVC_N110: 8 CGW
  SG_ EVEGTR_TotalDistance : 7|32@0+ (0.1,0) [0|4.294967295E8] "km" A_IVC
  SG_ TotalDischargeEnergy_V2X : 39|32@0+ (0.1,0) [0|4.294967295E8] "kWh" A_IVC

BO_ 2549874702 HEVC_N111: 8 CGW
  SG_ CertifiedEnergyConsumption : 7|16@0+ (0.1,0) [0|6553.5] "Wh/km" A_IVC
  SG_ ElapsedTimeSinceLast50pctCHG : 23|16@0+ (1,0) [0|65535] "day" A_IVC
  SG_ HVB_AveTemp_CHG : 39|8@0+ (1,-40) [-40|215] "?" A_IVC
  SG_ HVB_AveTemp_Driving : 47|8@0+ (1,-40) [-40|215] "?" A_IVC
  SG_ HVB_AveTemp_NonUsage : 55|8@0+ (1,-40) [-40|215] "?" A_IVC
  SG_ PercentageOfVirtualDistance : 63|8@0+ (0.4,0) [0|100] "%" A_IVC

BO_ 2549874703 HEVC_N112: 4 CGW
  SG_ DateOfManufacturingOfTheVehicle : 7|27@0+ (1,0) [0|1.34217727E8] "YYYY:MM:DD" A_IVC

BO_ 2549874704 HEVC_N113: 8 CGW
  SG_ TotalDisCHGEnergy_NonTraction : 7|32@0+ (0.1,0) [0|4.294967295E8] "kWh" A_IVC
  SG_ HVbatTotalEnergyThroughput_IVC : 39|32@0+ (100,0) [0|4.294967295E11] "Wh" A_IVC

BO_ 2563507968 SIGMA_CDMTriggerFrame: 7 CGW
  SG_ SIGMA_CDM : 4|29@0+ (1,0) [0|0] "" A_IVC,BLM,VKM
  SG_ SIGMA_DTCCDM : 39|24@0+ (1,0) [0|0] "" A_IVC,BLM,VKM

BO_ 2563508007 SIGMA_eHBoxTriggerFrame: 7 CGW
  SG_ SIGMA_eHBox : 4|29@0+ (1,0) [0|0] "" A_IVC,BLM,VKM
  SG_ SIGMA_DTCeHBox : 39|24@0+ (1,0) [0|0] "" A_IVC,BLM,VKM

BO_ 2563508009 SIGMA_PSD_RTriggerFrame: 7 CGW
  SG_ SIGMA_PSD_R : 4|29@0+ (1,0) [0|0] "" A_IVC,BLM,VKM
  SG_ SIGMA_DTCPSD_R : 39|24@0+ (1,0) [0|0] "" A_IVC,BLM,VKM

BO_ 2563508019 SIGMA_PBDTriggerFrame: 7 CGW
  SG_ SIGMA_PBD : 4|29@0+ (1,0) [0|0] "" A_IVC,BLM,VKM
  SG_ SIGMA_DTCPBD : 39|24@0+ (1,0) [0|0] "" A_IVC,BLM,VKM

BO_ 2563508021 SIGMA_RADARTriggerFrame: 7 CGW
  SG_ SIGMA_RADAR : 4|29@0+ (1,0) [0|0] "" A_IVC,BLM,VKM
  SG_ SIGMA_DTCRADAR : 39|24@0+ (1,0) [0|0] "" A_IVC,BLM,VKM

BO_ 2563508022 SIGMA_PSCUTriggerFrame: 7 CGW
  SG_ SIGMA_PSCU : 4|29@0+ (1,0) [0|0] "" A_IVC,BLM,VKM
  SG_ SIGMA_DTCPSCU : 39|24@0+ (1,0) [0|0] "" A_IVC,BLM,VKM

BO_ 2563508030 SIGMA_SRad_RLTriggerFrame: 7 CGW
  SG_ SIGMA_SRad_RL : 4|29@0+ (1,0) [0|0] "" A_IVC,BLM,VKM
  SG_ SIGMA_DTCSRad_RL : 39|24@0+ (1,0) [0|0] "" A_IVC,BLM,VKM

BO_ 2563508035 SIGMA_eRDC_LTriggerFrame: 7 CGW
  SG_ SIGMA_eRDC_L : 4|29@0+ (1,0) [0|0] "" A_IVC,BLM,VKM
  SG_ SIGMA_DTCeRDC_L : 39|24@0+ (1,0) [0|0] "" A_IVC,BLM,VKM

BO_ 2563508037 SIGMA_eRDC_RTriggerFrame: 7 CGW
  SG_ SIGMA_eRDC_R : 4|29@0+ (1,0) [0|0] "" A_IVC,BLM,VKM
  SG_ SIGMA_DTCeRDC_R : 39|24@0+ (1,0) [0|0] "" A_IVC,BLM,VKM

BO_ 2563508042 SIGMA_ANCTriggerFrame: 7 CGW
  SG_ SIGMA_ANC : 4|29@0+ (1,0) [0|0] "" A_IVC,BLM,VKM
  SG_ SIGMA_DTCANC : 39|24@0+ (1,0) [0|0] "" A_IVC,BLM,VKM

BO_ 2563508064 SIGMA_VDCTriggerFrame: 7 CGW
  SG_ SIGMA_VDC : 4|29@0+ (1,0) [0|0] "" A_IVC,BLM,VKM
  SG_ SIGMA_DTCVDC : 39|24@0+ (1,0) [0|0] "" A_IVC,BLM,VKM

BO_ 2563508066 SIGMA_EPSTriggerFrame: 7 CGW
  SG_ SIGMA_EPS : 4|29@0+ (1,0) [0|0] "" A_IVC,BLM,VKM
  SG_ SIGMA_DTCEPS : 39|24@0+ (1,0) [0|0] "" A_IVC,BLM,VKM

BO_ 2563508067 SIGMA_METERTriggerFrame: 7 CGW
  SG_ SIGMA_METER : 4|29@0+ (1,0) [0|0] "" A_IVC,BLM,VKM
  SG_ SIGMA_DTCMETER : 39|24@0+ (1,0) [0|0] "" A_IVC,BLM,VKM

BO_ 2563508068 SIGMA_HVACTriggerFrame: 7 CGW
  SG_ SIGMA_HVAC : 4|29@0+ (1,0) [0|0] "" A_IVC,BLM,VKM
  SG_ SIGMA_DTCHVAC : 39|24@0+ (1,0) [0|0] "" A_IVC,BLM,VKM

BO_ 2563508069 SIGMA_BCMTriggerFrame: 7 CGW
  SG_ SIGMA_BCM : 4|29@0+ (1,0) [0|0] "" A_IVC,BLM,VKM
  SG_ SIGMA_DTCBCM : 39|24@0+ (1,0) [0|0] "" A_IVC,BLM,VKM

BO_ 2563508071 SIGMA_IVITriggerFrame: 7 CGW
  SG_ SIGMA_IVI : 4|29@0+ (1,0) [0|0] "" A_IVC,BLM,VKM
  SG_ SIGMA_DTCIVI : 39|24@0+ (1,0) [0|0] "" A_IVC,BLM,VKM

BO_ 2563508072 SIGMA_4WDTriggerFrame: 7 CGW
  SG_ SIGMA_4WD : 4|29@0+ (1,0) [0|0] "" A_IVC,BLM,VKM
  SG_ SIGMA_DTC4WD : 39|24@0+ (1,0) [0|0] "" A_IVC,BLM,VKM

BO_ 2563508077 SIGMA_USMTriggerFrame: 7 CGW
  SG_ SIGMA_USM : 4|29@0+ (1,0) [0|0] "" A_IVC,BLM,VKM
  SG_ SIGMA_DTCUSM : 39|24@0+ (1,0) [0|0] "" A_IVC,BLM,VKM

BO_ 2563508078 SIGMA_SONARTriggerFrame: 7 CGW
  SG_ SIGMA_SONAR : 4|29@0+ (1,0) [0|0] "" A_IVC,BLM,VKM
  SG_ SIGMA_DTCSONAR : 39|24@0+ (1,0) [0|0] "" A_IVC,BLM,VKM

BO_ 2563508079 SIGMA_DSMUTriggerFrame: 7 CGW
  SG_ SIGMA_DSMU : 4|29@0+ (1,0) [0|0] "" A_IVC,BLM,VKM
  SG_ SIGMA_DTCDSMU : 39|24@0+ (1,0) [0|0] "" A_IVC,BLM,VKM

BO_ 2563508082 SIGMA_ACUTriggerFrame: 7 CGW
  SG_ SIGMA_ACU : 4|29@0+ (1,0) [0|0] "" A_IVC,BLM,VKM
  SG_ SIGMA_DTCACU : 39|24@0+ (1,0) [0|0] "" A_IVC,BLM,VKM

BO_ 2563508089 SIGMA_PSD_LTriggerFrame: 7 CGW
  SG_ SIGMA_PSD_L : 4|29@0+ (1,0) [0|0] "" A_IVC,BLM,VKM
  SG_ SIGMA_DTCPSD_L : 39|24@0+ (1,0) [0|0] "" A_IVC,BLM,VKM

BO_ 2563508093 SIGMA_ADASTriggerFrame: 7 CGW
  SG_ SIGMA_ADAS : 4|29@0+ (1,0) [0|0] "" A_IVC,BLM,VKM
  SG_ SIGMA_DTCADAS : 39|24@0+ (1,0) [0|0] "" A_IVC,BLM,VKM

BO_ 2563508099 SIGMA_A_IVCTriggerFrame: 7 A_IVC
  SG_ SIGMA_A_IVC : 4|29@0+ (1,0) [0|0] "" BLM,CGW,VKM
  SG_ SIGMA_DTCA_IVC : 39|24@0+ (1,0) [0|0] "" BLM,CGW,VKM

BO_ 2563508108 SIGMA_INV_METriggerFrame: 7 CGW
  SG_ SIGMA_INV_ME : 4|29@0+ (1,0) [0|0] "" A_IVC,BLM,VKM
  SG_ SIGMA_DTCINV_ME : 39|24@0+ (1,0) [0|0] "" A_IVC,BLM,VKM

BO_ 2563508115 SIGMA_OBC_ACTriggerFrame: 7 CGW
  SG_ SIGMA_OBC_AC : 4|29@0+ (1,0) [0|0] "" A_IVC,BLM,VKM
  SG_ SIGMA_DTCOBC_AC : 39|24@0+ (1,0) [0|0] "" A_IVC,BLM,VKM

BO_ 2563508122 SIGMA_HEVCTriggerFrame: 7 CGW
  SG_ SIGMA_HEVC : 4|29@0+ (1,0) [0|0] "" A_IVC,BLM,VKM
  SG_ SIGMA_DTCHEVC : 39|24@0+ (1,0) [0|0] "" A_IVC,BLM,VKM

BO_ 2563508130 SIGMA_AUDIOampTriggerFrame: 7 CGW
  SG_ SIGMA_AUDIOamp : 4|29@0+ (1,0) [0|0] "" A_IVC,BLM,VKM
  SG_ SIGMA_DTCAUDIOamp : 39|24@0+ (1,0) [0|0] "" A_IVC,BLM,VKM

BO_ 2563508133 SIGMA_HNSTriggerFrame: 7 CGW
  SG_ SIGMA_HNS : 4|29@0+ (1,0) [0|0] "" A_IVC,BLM,VKM
  SG_ SIGMA_DTCHNS : 39|24@0+ (1,0) [0|0] "" A_IVC,BLM,VKM

BO_ 2563508139 SIGMA_VKMTriggerFrame: 7 VKM
  SG_ SIGMA_VKM : 4|29@0+ (1,0) [0|0] "" A_IVC,BLM,CGW
  SG_ SIGMA_DTCVKM : 39|24@0+ (1,0) [0|0] "" A_IVC,BLM,CGW

BO_ 2563508153 SIGMA_HFMTriggerFrame: 7 CGW
  SG_ SIGMA_HFM : 4|29@0+ (1,0) [0|0] "" A_IVC,BLM,VKM
  SG_ SIGMA_DTCHFM : 39|24@0+ (1,0) [0|0] "" A_IVC,BLM,VKM

BO_ 2563508154 SIGMA_AVMTriggerFrame: 7 CGW
  SG_ SIGMA_AVM : 4|29@0+ (1,0) [0|0] "" A_IVC,BLM,VKM
  SG_ SIGMA_DTCAVM : 39|24@0+ (1,0) [0|0] "" A_IVC,BLM,VKM

BO_ 2563508157 SIGMA_SCUTriggerFrame: 7 CGW
  SG_ SIGMA_SCU : 4|29@0+ (1,0) [0|0] "" A_IVC,BLM,VKM
  SG_ SIGMA_DTCSCU : 39|24@0+ (1,0) [0|0] "" A_IVC,BLM,VKM

BO_ 2563508164 SIGMA_eShifterTriggerFrame: 7 CGW
  SG_ SIGMA_eShifter : 4|29@0+ (1,0) [0|0] "" A_IVC,BLM,VKM
  SG_ SIGMA_DTCeShifter : 39|24@0+ (1,0) [0|0] "" A_IVC,BLM,VKM

BO_ 2563508181 SIGMA_SRad_RRTriggerFrame: 7 CGW
  SG_ SIGMA_SRad_RR : 4|29@0+ (1,0) [0|0] "" A_IVC,BLM,VKM
  SG_ SIGMA_DTCSRad_RR : 39|24@0+ (1,0) [0|0] "" A_IVC,BLM,VKM

BO_ 2563508189 SIGMA_FrCameraTriggerFrame: 7 CGW
  SG_ SIGMA_FrCamera : 4|29@0+ (1,0) [0|0] "" A_IVC,BLM,VKM
  SG_ SIGMA_DTCFrCamera : 39|24@0+ (1,0) [0|0] "" A_IVC,BLM,VKM

BO_ 2563508200 SIGMA_ECMTriggerFrame: 7 CGW
  SG_ SIGMA_ECM : 4|29@0+ (1,0) [0|0] "" A_IVC,BLM,VKM
  SG_ SIGMA_DTCECM : 39|24@0+ (1,0) [0|0] "" A_IVC,BLM,VKM

BO_ 2563508201 SIGMA_ATCUTriggerFrame: 7 CGW
  SG_ SIGMA_ATCU : 4|29@0+ (1,0) [0|0] "" A_IVC,BLM,VKM
  SG_ SIGMA_DTCATCU : 39|24@0+ (1,0) [0|0] "" A_IVC,BLM,VKM

BO_ 2563508205 SIGMA_BMS_HVTriggerFrame: 7 CGW
  SG_ SIGMA_BMS_HV : 4|29@0+ (1,0) [0|0] "" A_IVC,BLM,VKM
  SG_ SIGMA_DTCBMS_HV : 39|24@0+ (1,0) [0|0] "" A_IVC,BLM,VKM

BO_ 2563508207 SIGMA_INV_HSGTriggerFrame: 7 CGW
  SG_ SIGMA_INV_HSG : 4|29@0+ (1,0) [0|0] "" A_IVC,BLM,VKM
  SG_ SIGMA_DTCINV_HSG : 39|24@0+ (1,0) [0|0] "" A_IVC,BLM,VKM

BO_ 2563567883 SIGMA_BMS_12VTriggerFrame: 7 CGW
  SG_ SIGMA_BMS_12V : 4|29@0+ (1,0) [0|0] "" A_IVC,BLM,VKM
  SG_ SIGMA_DTCBMS_12V : 39|24@0+ (1,0) [0|0] "" A_IVC,BLM,VKM

BO_ 2563567951 SIGMA_EPS_subTriggerFrame: 7 CGW
  SG_ SIGMA_EPS_sub : 4|29@0+ (1,0) [0|0] "" A_IVC,BLM,VKM
  SG_ SIGMA_DTCEPS_sub : 39|24@0+ (1,0) [0|0] "" A_IVC,BLM,VKM

BO_ 2563567958 SIGMA_eShiftActTriggerFrame: 7 CGW
  SG_ SIGMA_eShiftAct : 4|29@0+ (1,0) [0|0] "" A_IVC,BLM,VKM
  SG_ SIGMA_DTCeShiftAct : 39|24@0+ (1,0) [0|0] "" A_IVC,BLM,VKM

BO_ 2563567968 SIGMA_HUDTriggerFrame: 7 CGW
  SG_ SIGMA_HUD : 4|29@0+ (1,0) [0|0] "" A_IVC,BLM,VKM
  SG_ SIGMA_DTCHUD : 39|24@0+ (1,0) [0|0] "" A_IVC,BLM,VKM

BO_ 2563568024 SIGMA_HPCUTriggerFrame: 7 CGW
  SG_ SIGMA_HPCU : 4|29@0+ (1,0) [0|0] "" A_IVC,BLM,VKM
  SG_ SIGMA_DTCHPCU : 39|24@0+ (1,0) [0|0] "" A_IVC,BLM,VKM

BO_ 2563568093 SIGMA_DCDC_HVTriggerFrame: 7 CGW
  SG_ SIGMA_DCDC_HV : 4|29@0+ (1,0) [0|0] "" A_IVC,BLM,VKM
  SG_ SIGMA_DTCDCDC_HV : 39|24@0+ (1,0) [0|0] "" A_IVC,BLM,VKM

BO_ 2563568098 SIGMA_EBATriggerFrame: 7 CGW
  SG_ SIGMA_EBA : 4|29@0+ (1,0) [0|0] "" A_IVC,BLM,VKM
  SG_ SIGMA_DTCEBA : 39|24@0+ (1,0) [0|0] "" A_IVC,BLM,VKM

BO_ 2563568101 SIGMA_INV_RETriggerFrame: 7 CGW
  SG_ SIGMA_INV_RE : 4|29@0+ (1,0) [0|0] "" A_IVC,BLM,VKM
  SG_ SIGMA_DTCINV_RE : 39|24@0+ (1,0) [0|0] "" A_IVC,BLM,VKM

BO_ 2563568130 SIGMA_AirSUSPTriggerFrame: 7 CGW
  SG_ SIGMA_AirSUSP : 4|29@0+ (1,0) [0|0] "" A_IVC,BLM,VKM
  SG_ SIGMA_DTCAirSUSP : 39|24@0+ (1,0) [0|0] "" A_IVC,BLM,VKM

BO_ 2563568148 SIGMA_BSGTriggerFrame: 7 CGW
  SG_ SIGMA_BSG : 4|29@0+ (1,0) [0|0] "" A_IVC,BLM,VKM
  SG_ SIGMA_DTCBSG : 39|24@0+ (1,0) [0|0] "" A_IVC,BLM,VKM

BO_ 2563568163 SIGMA_SRad_FL_TriggerFrame: 7 CGW
  SG_ SIGMA_SRad_FL : 4|29@0+ (1,0) [0|0] "" A_IVC,BLM,VKM
  SG_ SIGMA_DTCSRad_FL : 39|24@0+ (1,0) [0|0] "" A_IVC,BLM,VKM

BO_ 2563568164 SIGMA_SRad_FRTriggerFrame: 7 CGW
  SG_ SIGMA_SRad_FR : 4|29@0+ (1,0) [0|0] "" A_IVC,BLM,VKM
  SG_ SIGMA_DTCSRad_FR : 39|24@0+ (1,0) [0|0] "" A_IVC,BLM,VKM

BO_ 2563568201 SIGMA_STBWTriggerFrame: 7 CGW
  SG_ SIGMA_STBW : 4|29@0+ (1,0) [0|0] "" A_IVC,BLM,VKM
  SG_ SIGMA_DTCSTBW : 39|24@0+ (1,0) [0|0] "" A_IVC,BLM,VKM

BO_ 2563568233 SIGMA_DMCTriggerFrame: 7 CGW
  SG_ SIGMA_DMC : 4|29@0+ (1,0) [0|0] "" A_IVC,BLM,VKM
  SG_ SIGMA_DTCDMC : 39|24@0+ (1,0) [0|0] "" A_IVC,BLM,VKM

BO_ 2563568267 SIGMA_RSCU3RTriggerFrame: 7 CGW
  SG_ SIGMA_RSCU3R : 4|29@0+ (1,0) [0|0] "" A_IVC,BLM,VKM
  SG_ SIGMA_DTCRSCU3R : 39|24@0+ (1,0) [0|0] "" A_IVC,BLM,VKM

BO_ 2563568288 SIGMA_BLM_RPKTriggerFrame: 7 BLM
  SG_ SIGMA_BLM_RPK : 4|29@0+ (1,0) [0|0] "" A_IVC,CGW,VKM
  SG_ SIGMA_DTCBLM_RPK : 39|24@0+ (1,0) [0|0] "" A_IVC,CGW,VKM

BO_ 2563568290 SIGMA_SCCMTriggerFrame: 7 CGW
  SG_ SIGMA_SCCM : 4|29@0+ (1,0) [0|0] "" A_IVC,BLM,VKM
  SG_ SIGMA_DTCSCCM : 39|24@0+ (1,0) [0|0] "" A_IVC,BLM,VKM

BO_ 2563568300 SIGMA_RSCU2RTriggerFrame: 7 CGW
  SG_ SIGMA_RSCU2R : 4|29@0+ (1,0) [0|0] "" A_IVC,BLM,VKM
  SG_ SIGMA_DTCRSCU2R : 39|24@0+ (1,0) [0|0] "" A_IVC,BLM,VKM

BO_ 2563639040 SIGMA_CDM_ReadMeReq_Frame: 8 CGW
  SG_ SIGMA_CDM_ReadMeReqRDIAG : 7|64@0+ (1,0) [0|0] "" A_IVC

BO_ 2563639081 SIGMA_PSD_R_ReadMeReq_Frame: 8 CGW
  SG_ SIGMA_PSD_R_ReadMeReqRDIAG : 7|64@0+ (1,0) [0|0] "" A_IVC

BO_ 2563639091 SIGMA_PBD_ReadMeReq_Frame: 8 CGW
  SG_ SIGMA_PBD_ReadMeReqRDIAG : 7|64@0+ (1,0) [0|0] "" A_IVC

BO_ 2563639107 SIGMA_eRDC_L_ReadMeReq_Frame: 8 CGW
  SG_ SIGMA_eRDC_L_ReadMeReqRDIAG : 7|64@0+ (1,0) [0|0] "" A_IVC

BO_ 2563639109 SIGMA_eRDC_R_ReadMeReq_Frame: 8 CGW
  SG_ SIGMA_eRDC_R_ReadMeReqRDIAG : 7|64@0+ (1,0) [0|0] "" A_IVC

BO_ 2563639136 SIGMA_VDC_ReadMeReq_Frame: 8 CGW
  SG_ SIGMA_ABS_VDC_ReadMeReqRDIAG : 7|64@0+ (1,0) [0|0] "" A_IVC

BO_ 2563639149 SIGMA_USM_ReadMeReq_Frame: 8 CGW
  SG_ SIGMA_USM_ReadMeReqRDIAG : 7|64@0+ (1,0) [0|0] "" A_IVC

BO_ 2563639161 SIGMA_PSD_L_ReadMeReq_Frame: 8 CGW
  SG_ SIGMA_PSD_L_ReadMeReqRDIAG : 7|64@0+ (1,0) [0|0] "" A_IVC

BO_ 2563639180 SIGMA_INV_ME_ReadMeReq_Frame: 8 CGW
  SG_ SIGMA_INV_ME_ReadMeReqRDIAG : 7|64@0+ (1,0) [0|0] "" A_IVC

BO_ 2563639226 SIGMA_AVM_ReadMeReq_Frame: 8 CGW
  SG_ SIGMA_AVM_ReadMeReqRDIAG : 7|64@0+ (1,0) [0|0] "" A_IVC

BO_ 2563639272 SIGMA_ECM_ReadMeReq_Frame: 8 CGW
  SG_ SIGMA_ECM_ReadMeReqRDIAG : 7|64@0+ (1,0) [0|0] "" A_IVC

BO_ 2563639273 SIGMA_ATCU_ReadMeReq_Frame: 8 CGW
  SG_ SIGMA_ATCUReadMeReqRDIAG : 7|64@0+ (1,0) [0|0] "" A_IVC

BO_ 2563639279 SIGMA_INV_HSG_ReadMeReq_Frame: 8 CGW
  SG_ SIGMA_INV_HSG_ReadMeReqRDIAG : 7|64@0+ (1,0) [0|0] "" A_IVC

BO_ 2563699173 SIGMA_INV_RE_ReadMeReq_Frame: 8 CGW
  SG_ SIGMA_INV_RE_ReadMeReqRDIAG : 7|64@0+ (1,0) [0|0] "" A_IVC

BO_ 2563699202 SIGMA_AirSUSP_ReadMeReq_Frame: 8 CGW
  SG_ SIGMA_AirSUSP_ReadMeReqRDIAG : 7|64@0+ (1,0) [0|0] "" A_IVC

BO_ 2564423922 DTOOL_to_ATR: 8 A_IVC
  SG_ DTOOL_to_ATR : 7|64@0+ (1,0) [0|0] "" CGW

BO_ 2564424434 DTOOL_to_AIRSUSP: 8 A_IVC
  SG_ DTOOL_to_AIRSUSP : 7|64@0+ (1,0) [0|0] "" CGW

BO_ 2564426737 DTOOL_to_BMS12Vextd: 8 A_IVC
  SG_ DTOOL_to_BMS12Vextd : 7|64@0+ (1,0) [0|0] "" CGW

BO_ 2564428017 DTOOL_to_HEVCextd_v2: 8 A_IVC
  SG_ DTOOL_to_HEVCextd_v2 : 7|64@0+ (1,0) [0|0] "" CGW

BO_ 2564428529 DTOOL_to_eVTCextd: 8 A_IVC
  SG_ DTOOL_to_eVTCextd : 7|64@0+ (1,0) [0|0] "" CGW

BO_ 2564429042 DTOOL_to_BSGextd: 8 A_IVC
  SG_ DTOOL_to_BSGextd : 7|64@0+ (1,0) [0|0] "" CGW

BO_ 2564429297 DTOOL_to_ECMextd: 8 A_IVC
  SG_ DTOOL_to_ECMextd : 7|64@0+ (1,0) [0|0] "" CGW

BO_ 2564429809 DTOOL_to_VCRextd: 8 A_IVC
  SG_ DTOOL_to_VCRextd : 7|64@0+ (1,0) [0|0] "" CGW

BO_ 2564430065 DTOOL_to_ATCUextd: 8 A_IVC
  SG_ DTOOL_to_ATCUextd : 7|64@0+ (1,0) [0|0] "" CGW

BO_ 2564432882 DTOOL_to_SRad_FL: 8 A_IVC
  SG_ DTOOL_to_SRad_FL : 7|64@0+ (1,0) [0|0] "" CGW

BO_ 2564433138 DTOOL_to_SRad_FR: 8 A_IVC
  SG_ DTOOL_to_SRad_FR : 7|64@0+ (1,0) [0|0] "" CGW

BO_ 2564435441 DTOOL_to_VDCextd: 8 A_IVC
  SG_ DTOOL_to_VDCextd : 7|64@0+ (1,0) [0|0] "" CGW

BO_ 2564441074 DTOOL_to_eRDC_L: 8 A_IVC
  SG_ DTOOL_to_eRDC_L : 7|64@0+ (1,0) [0|0] "" CGW

BO_ 2564441586 DTOOL_to_eRDC_R: 8 A_IVC
  SG_ DTOOL_to_eRDC_R : 7|64@0+ (1,0) [0|0] "" CGW

BO_ 2564442610 DTOOL_to_SBW: 8 A_IVC
  SG_ DTOOL_to_SBW : 7|64@0+ (1,0) [0|0] "" CGW

BO_ 2564443378 DTOOL_to_DOP_RES: 8 A_IVC
  SG_ DTOOL_to_DOP_RES : 7|64@0+ (1,0) [0|0] "" CGW

BO_ 2564445426 DTOOL_to_ELOP: 8 A_IVC
  SG_ DTOOL_to_ELOP : 7|64@0+ (1,0) [0|0] "" CGW

BO_ 2564445937 DTOOL_to_eShiftAct: 8 A_IVC
  SG_ DTOOL_to_eShiftAct : 7|64@0+ (1,0) [0|0] "" CGW

BO_ 2564447986 DTOOL_to_PSB_P: 8 A_IVC
  SG_ DTOOL_to_PSB_P : 7|64@0+ (1,0) [0|0] "" CGW

BO_ 2564448497 DTOOL_to_HUDextd: 8 A_IVC
  SG_ DTOOL_to_HUDextd : 7|64@0+ (1,0) [0|0] "" CGW

BO_ 2564450802 DTOOL_to_DMC: 8 A_IVC
  SG_ DTOOL_to_DMC : 7|64@0+ (1,0) [0|0] "" CGW

BO_ 2564452850 DTOOL_to_LCU_ADBextd: 8 A_IVC
  SG_ DTOOL_to_LCU_ADBextd : 7|64@0+ (1,0) [0|0] "" CGW

BO_ 2564453106 DTOOL_to_ADBdriverL: 8 A_IVC
  SG_ DTOOL_to_ADBdriverL : 7|64@0+ (1,0) [0|0] "" CGW

BO_ 2564453362 DTOOL_to_ADBdriverR: 8 A_IVC
  SG_ DTOOL_to_ADBdriverR : 7|64@0+ (1,0) [0|0] "" CGW

BO_ 2564459506 DTOOL_to_RSCU3R: 8 A_IVC
  SG_ DTOOL_to_RSCU3R : 7|64@0+ (1,0) [0|0] "" CGW

BO_ 2564460018 DTOOL_to_FCP: 8 A_IVC
  SG_ DTOOL_to_FCP : 7|64@0+ (1,0) [0|0] "" CGW

BO_ 2564460274 DTOOL_to_RCP: 8 A_IVC
  SG_ DTOOL_to_RCP : 7|64@0+ (1,0) [0|0] "" CGW

BO_ 2564462833 DTOOL_to_HVAC2: 8 A_IVC
  SG_ DTOOL_to_HVAC2 : 7|64@0+ (1,0) [0|0] "" CGW

BO_ 2564465394 DTOOL_to_SCCM: 8 A_IVC
  SG_ DTOOL_to_SCCM : 7|64@0+ (1,0) [0|0] "" CGW

BO_ 2564467698 DTOOL_to_BLM: 8 CGW
  SG_ DTOOL_to_BLM : 7|64@0+ (1,0) [0|0] "" BLM

BO_ 2564467954 DTOOL_to_RSCU: 8 A_IVC
  SG_ DTOOL_to_RSCU : 7|64@0+ (1,0) [0|0] "" CGW

BO_ 2564468210 DTOOL_to_CMS_P: 8 A_IVC
  SG_ DTOOL_to_CMS_P : 7|64@0+ (1,0) [0|0] "" CGW

BO_ 2564468466 DTOOL_to_CMS_D: 8 A_IVC
  SG_ DTOOL_to_CMS_D : 7|64@0+ (1,0) [0|0] "" CGW

BO_ 2564478193 DTOOL_to_GW: 8 A_IVC
  SG_ DTOOL_to_Gwextd : 7|64@0+ (1,0) [0|0] "" CGW

BO_ 2564478962 DTOOL_to_CSCM: 8 A_IVC
  SG_ DTOOL_to_CSCM : 7|64@0+ (1,0) [0|0] "" CGW

BO_ 2564479729 DTOOL_to_HEVCextd: 8 A_IVC
  SG_ DTOOL_to_HEVCextd : 7|64@0+ (1,0) [0|0] "" CGW

BO_ 2564479985 DTOOL_to_BMSextd: 8 A_IVC
  SG_ DTOOL_to_BMSextd : 7|64@0+ (1,0) [0|0] "" CGW

BO_ 2564480241 DTOOL_to_BMS2extd: 8 A_IVC
  SG_ DTOOL_to_BMS2extd : 7|64@0+ (1,0) [0|0] "" CGW

BO_ 2564480497 DTOOL_to_DCDCextd: 8 A_IVC
  SG_ DTOOL_to_DCDCextd : 7|64@0+ (1,0) [0|0] "" CGW

BO_ 2564480753 DTOOL_to_OBCextd: 8 A_IVC
  SG_ DTOOL_to_OBCextd : 7|64@0+ (1,0) [0|0] "" CGW

BO_ 2564481009 DTOOL_to_INV_MEextd: 8 A_IVC
  SG_ DTOOL_to_INV_MEextd : 7|64@0+ (1,0) [0|0] "" CGW

BO_ 2564481265 DTOOL_to_EVAPextd: 8 A_IVC
  SG_ DTOOL_to_EVAPextd : 7|64@0+ (1,0) [0|0] "" CGW

BO_ 2564481521 DTOOL_to_SCR_UDCUextd: 8 A_IVC
  SG_ DTOOL_to_SCR_UDCUextd : 7|64@0+ (1,0) [0|0] "" CGW

BO_ 2564481777 DTOOL_to_EBAextd: 8 A_IVC
  SG_ DTOOL_to_EBAextd : 7|64@0+ (1,0) [0|0] "" CGW

BO_ 2564482033 DTOOL_to_INV_HSGextd: 8 A_IVC
  SG_ DTOOL_to_INV_HSGextd : 7|64@0+ (1,0) [0|0] "" CGW

BO_ 2564482545 DTOOL_to_INV_RE: 8 A_IVC
  SG_ DTOOL_to_INV_RE : 7|64@0+ (1,0) [0|0] "" CGW

BO_ 2564485387 BMS12Vextd_to_DTOOL: 8 CGW
  SG_ BMS12Vextd_to_DTOOL : 7|64@0+ (1,0) [0|0] "" A_IVC

BO_ 2564485392 HEVC_to_DTOOLextd_v2: 8 CGW
  SG_ HEVC_to_DTOOLextd_v2 : 7|64@0+ (1,0) [0|0] "" A_IVC

BO_ 2564485394 eVTC_to_DTOOLextd: 8 CGW
  SG_ eVTC_to_DTOOLextd : 7|64@0+ (1,0) [0|0] "" A_IVC

BO_ 2564485397 ECM_to_DTOOLextd: 8 CGW
  SG_ ECM_to_DTOOLextd : 7|64@0+ (1,0) [0|0] "" A_IVC

BO_ 2564485399 VCR_to_DTOOLextd: 8 CGW
  SG_ VCR_to_DTOOLextd : 7|64@0+ (1,0) [0|0] "" A_IVC

BO_ 2564485400 ATCU_to_DTOOLextd: 8 CGW
  SG_ ATCU_to_DTOOLextd : 7|64@0+ (1,0) [0|0] "" A_IVC

BO_ 2564485421 VDC_to_DTOOLextd: 8 CGW
  SG_ VDC_to_DTOOLextd : 7|64@0+ (1,0) [0|0] "" A_IVC

BO_ 2564485462 eShiftAct_to_DTOOL: 8 CGW
  SG_ eShiftAct_to_DTOOL : 7|64@0+ (1,0) [0|0] "" A_IVC

BO_ 2564485472 HUD_to_DTOOLextd: 8 CGW
  SG_ HUD_to_DTOOLextd : 7|64@0+ (1,0) [0|0] "" A_IVC

BO_ 2564485528 HVAC2_to_DTOOL: 8 CGW
  SG_ HVAC2_to_DTOOL : 7|64@0+ (1,0) [0|0] "" A_IVC

BO_ 2564485588 GW_to_DTOOL: 8 CGW
  SG_ GW_to_DTOOL : 7|64@0+ (1,0) [0|0] "" A_IVC

BO_ 2564485594 HEVC_to_DTOOLextd: 8 CGW
  SG_ HEVC_to_DTOOLextd : 7|64@0+ (1,0) [0|0] "" A_IVC

BO_ 2564485595 BMS_to_DTOOLextd: 8 CGW
  SG_ BMS_to_DTOOLextd : 7|64@0+ (1,0) [0|0] "" A_IVC

BO_ 2564485596 BMS2_to_DTOOLextd: 8 CGW
  SG_ BMS2_to_DTOOLextd : 7|64@0+ (1,0) [0|0] "" A_IVC

BO_ 2564485597 DCDC_to_DTOOLextd: 8 CGW
  SG_ DCDC_to_DTOOLextd : 7|64@0+ (1,0) [0|0] "" A_IVC

BO_ 2564485598 OBC_to_DTOOLextd: 8 CGW
  SG_ OBC_to_DTOOLextd : 7|64@0+ (1,0) [0|0] "" A_IVC

BO_ 2564485599 INV_ME_to_DTOOLextd: 8 CGW
  SG_ INV_ME_to_DTOOLextd : 7|64@0+ (1,0) [0|0] "" A_IVC

BO_ 2564485600 EVAP_to_DTOOLextd: 8 CGW
  SG_ EVAP_to_DTOOLextd : 7|64@0+ (1,0) [0|0] "" A_IVC

BO_ 2564485601 SCR_UDCU_to_DTOOLextd: 8 CGW
  SG_ SCR_UDCU_to_DTOOLextd : 7|64@0+ (1,0) [0|0] "" A_IVC

BO_ 2564485602 EBA_to_DTOOLextd: 8 CGW
  SG_ EBA_to_DTOOLextd : 7|64@0+ (1,0) [0|0] "" A_IVC

BO_ 2564485603 INV_HSG_to_DTOOLextd: 8 CGW
  SG_ INV_HSG_to_DTOOLextd : 7|64@0+ (1,0) [0|0] "" A_IVC

BO_ 2564485605 INV_RE_to_DTOOL: 8 CGW
  SG_ INV_RE_to_DTOOL : 7|64@0+ (1,0) [0|0] "" A_IVC

BO_ 2564485634 AIRSUSP_to_DTOOL: 8 CGW
  SG_ AIRSUSP_to_DTOOL : 7|64@0+ (1,0) [0|0] "" A_IVC

BO_ 2564485652 BSGextd_to_DTOOL: 8 CGW
  SG_ BSGextd_to_DTOOL : 7|64@0+ (1,0) [0|0] "" A_IVC

BO_ 2564485667 SRad_FL_to_DTOOL: 8 CGW
  SG_ SRad_FL_to_DTOOL : 7|64@0+ (1,0) [0|0] "" A_IVC

BO_ 2564485668 SRad_FR_to_DTOOL: 8 CGW
  SG_ SRad_FR_to_DTOOL : 7|64@0+ (1,0) [0|0] "" A_IVC

BO_ 2564485699 eRDC_L_to_DTOOL: 8 CGW
  SG_ ERDC_L_to_DTOOL : 7|64@0+ (1,0) [0|0] "" A_IVC

BO_ 2564485701 eRDC_R_to_DTOOL: 8 CGW
  SG_ ERDC_R_to_DTOOL : 7|64@0+ (1,0) [0|0] "" A_IVC

BO_ 2564485705 SBW_to_DTOOL: 8 CGW
  SG_ SBW_to_DTOOL : 7|64@0+ (1,0) [0|0] "" A_IVC

BO_ 2564485716 ELOP_to_DTOOL: 8 CGW
  SG_ ELOP_to_DTOOL : 7|64@0+ (1,0) [0|0] "" A_IVC

BO_ 2564485726 PSB_P_to_DTOOL: 8 CGW
  SG_ PSB_P_to_DTOOL : 7|64@0+ (1,0) [0|0] "" A_IVC

BO_ 2564485737 DMC_to_DTOOL: 8 CGW
  SG_ DMC_to_DTOOL : 7|64@0+ (1,0) [0|0] "" A_IVC

BO_ 2564485745 LCU_ADB_to_DTOOLextd: 8 CGW
  SG_ LCU_ADB_to_DTOOLextd : 7|64@0+ (1,0) [0|0] "" A_IVC

BO_ 2564485746 ADBdriverL_To_DTOOL: 8 CGW
  SG_ ADBdriverL_To_DTOOL : 7|64@0+ (1,0) [0|0] "" A_IVC

BO_ 2564485747 ADBdriverR_To_DTOOL: 8 CGW
  SG_ ADBdriverR_To_DTOOL : 7|64@0+ (1,0) [0|0] "" A_IVC

BO_ 2564485771 RSCU3R_to_DTOOL: 8 CGW
  SG_ RSCU3R_to_DTOOL : 7|64@0+ (1,0) [0|0] "" A_IVC

BO_ 2564485773 FCP_to_DTOOL: 8 CGW
  SG_ FCP_to_DTOOL : 7|64@0+ (1,0) [0|0] "" A_IVC

BO_ 2564485774 RCP_to_DTOOL: 8 CGW
  SG_ RCP_to_DTOOL : 7|64@0+ (1,0) [0|0] "" A_IVC

BO_ 2564485794 SCCM_to_DTOOL: 8 CGW
  SG_ SCCM_to_DTOOL : 7|64@0+ (1,0) [0|0] "" A_IVC

BO_ 2564485803 BLM_VK_to_DTOOL: 8 BLM
  SG_ BLM_VK_to_DTOOL : 7|64@0+ (1,0) [0|0] "" A_IVC,CGW

BO_ 2564485804 RSCU_to_DTOOL: 8 CGW
  SG_ RSCU_to_DTOOL : 7|64@0+ (1,0) [0|0] "" A_IVC

BO_ 2564485805 CMS_P_to_DTOOL: 8 CGW
  SG_ CMS_P_to_DTOOL : 7|64@0+ (1,0) [0|0] "" A_IVC

BO_ 2564485806 CMS_D_to_DTOOL: 8 CGW
  SG_ CMS_D_to_DTOOL : 7|64@0+ (1,0) [0|0] "" A_IVC

BO_ 2564485847 CSCM_to_DTOOL: 8 CGW
  SG_ CSCM_to_DTOOL : 7|64@0+ (1,0) [0|0] "" A_IVC

BO_ 2609102848 CGW_WakeUpFrame_extd: 2 CGW
  SG_ CGW_WakeUp_Signal : 7|16@0+ (1,0) [0|0] "" A_IVC

BO_ 2609102855 A_IVC_WakeUpFrame_extd: 2 A_IVC
  SG_ A_IVC_WakeUp_Signal : 7|16@0+ (1,0) [0|0] "" CGW

BO_ 2609102864 BLM_WakeUpFrame_extd: 2 BLM
  SG_ BLM_WakeUp_Signal : 7|16@0+ (1,0) [0|0] "" CGW

BO_ 2609102875 VKM_WakeUpFrame: 2 VKM
  SG_ VKM_WakeUp_Signal : 7|16@0+ (1,0) [0|0] "" CGW

BO_ 2615050482 FTOOLS_IVCtoSWMC: 8 A_IVC
  SG_ FTOOLS_IVCtoSWMC : 7|64@0+ (1,0) [0|0] "" CGW

BO_ 2615061490 FTOOLS_CGWtoBLM: 8 CGW
  SG_ FTOOLS_CGWtoBLM : 7|64@0+ (1,0) [0|0] "" BLM

BO_ 2615079552 FTOOLS_SWMCtoIVC: 8 CGW
  SG_ FTOOLS_SWMCtoIVC : 7|64@0+ (1,0) [0|0] "" A_IVC

BO_ 2615079595 FTOOLS_BLMtoCGW: 8 BLM
  SG_ FTOOLS_BLMtoCGW : 7|64@0+ (1,0) [0|0] "" CGW

BO_TX_BU_ 2564485803 : BLM,VKM;
VAL_ 1469 MeterVolumeRequest 0 "No request" 1 "Volume 1" 2 "Volume 2" 3 "Volume 3" 4 "Not used" 5 "Not used" 6 "Not used" 7 "Reset request";
VAL_ 1469 ADB_ActivationRequest2 0 "No ADB request" 1 "ADB activated" 2 "ADB not activated" 3 "Reset request";
VAL_ 1471 PassengerMassageIntensityState 0 "No intensity" 1 "Intensity 1" 2 "Intensity 2" 3 "Intensity 3" 4 "Intensity 4" 5 "Intensity 5" 6 "Not Used" 7 "Not Used";
VAL_ 1471 PassengerMassageVelocityState 0 "No velocity" 1 "velocity 1" 2 "velocity 2" 3 "velocity 3" 4 "velocity 4" 5 "velocity 5" 6 "Not Used" 7 "Not Used";
VAL_ 1471 PassengerMassageActivationState 0 "Massage OFF" 1 "Massage ON";
VAL_ 1474 ClimRightTempDisplay 0 "No display" 8 "Display Lo" 10 "Display Hi";
VAL_ 1474 ClimTempDisplay 0 "No display" 8 "Display Lo" 10 "Display Hi";
VAL_ 1474 ClimFlowDistrDisplay 0 "No display" 1 "Feet" 2 "Aerator" 3 "Feet + Aerator" 4 "Mild flow" 5 "Feet + Mild flow" 6 "Mild flow + Aerator" 7 "Feet + Aerator Mild flow" 8 "Defrost" 9 "Feet + Defrost" 10 "Aerator + Defrost" 11 "Feet + Aerator + Defrost" 12 "Mild flow + Defrost" 13 "Feet + Mild flow + Defrost" 14 "Aerator + Mild flow + Defrost" 15 "Feet + Aerator + Mild flow + Defrost";
VAL_ 1474 ClimOFFModeDisplay 0 "No Display" 1 "OFF Mode Activated Display";
VAL_ 1474 ClimModeTypeDisplay 0 "No display" 1 "Auto Mode" 2 "Eco Mode" 3 "Clearness Mode" 4 "Manual Mode" 5 "OFF" 6 "Not Used" 7 "Not Used";
VAL_ 1474 ClimBlowerLevelDisplay 0 "No display" 1 "Level 1" 2 "Level 2" 3 "Level 3" 4 "Level 4" 5 "Level 5" 6 "Level 6" 7 "Level 7" 8 "Level 8" 9 "Level 9" 10 "Level 10" 11 "Level 11" 12 "Level 12" 13 "Level 13" 14 "Level 14" 15 "Blower Off";
VAL_ 1474 ClimClearnessDisplay 0 "No display" 1 "Clearness ON" 2 "Clearness OFF" 3 "Not Used";
VAL_ 1474 ClimAutoModeDisplay 0 "No display" 1 "Soft display" 2 "Fast display" 3 "Auto display";
VAL_ 1474 ClimAutoDisplay 0 "No display" 1 "Auto activated" 2 "Auto not activated" 3 "Not used";
VAL_ 1474 ClimACDisplay 0 "No display" 1 "AC ON" 2 "AC OFF" 3 "Not used";
VAL_ 1474 ClimRearDefrostDisplay 0 "No display" 1 "Rear defrost ON" 2 "Rear defrost OFF" 3 "Not Used";
VAL_ 1474 FrontDefrostDisplayRequest 0 "NO Front Defrog Display Request" 1 "Front Degrog Display Request";
VAL_ 1478 SR_ContinuousRecordLengthRequest 0 "No request" 1 "1 minute" 2 "3 minutes" 3 "5 minutes" 4 "Not used" 5 "Not used" 6 "Not used" 7 "Reset request";
VAL_ 1478 SR_ShockSensitivityRequest 0 "No request" 1 "Low" 2 "Mid" 3 "High" 4 "Not used" 5 "Not used" 6 "Not used" 7 "Reset request";
VAL_ 1478 SR_DrivingInfoRecordRequest 0 "No request" 1 "No Record request" 2 "Record request" 3 "Reset request";
VAL_ 1478 SR_LocationInfoRecordRequest 0 "No request" 1 "No record request" 2 "Record request" 3 "Reset request";
VAL_ 1478 SR_SoundRecordRequest 0 "No request" 1 "Sound recorded request" 2 "Sound not recorded request" 3 "Reset request";
VAL_ 1478 SR_CustomerRecordLengthRequest 0 "No request" 1 "1 minute" 2 "3 minutes" 3 "5 minutes" 4 "Not used" 5 "Not used" 6 "Not used" 7 "Reset request";
VAL_ 1479 ERP_ActivationStatus 0 "ERP OFF" 1 "ERP ON";
VAL_ 1480 ChargeTimeDisplayAtAPrct 0 "No Display";
VAL_ 1480 ChargeTimeDisplayAtBPrct 0 "No Display";
VAL_ 1480 ChargeTimeDisplayAtCPrct 0 "No Display";
VAL_ 1480 ChargeTimeDisplayAtDPrct 0 "No Display";
VAL_ 1482 TSR_OSPActivationRequest2 0 "No request" 1 "TSR/OSP ON request" 2 "TSR/OSP OFF request" 3 "Reset Requested";
VAL_ 1482 LDW_ActivationRequest2 0 "No request" 1 "LDW activation request" 2 "LDW de-activation request" 3 "Reset request";
VAL_ 1482 LDW_VibrationIntensityReq2 0 "No request" 1 "Low intensity request" 2 "Middle intensity request" 3 "High intensity request" 4 "Not used" 5 "Not used" 6 "Not used" 7 "Reset request";
VAL_ 1482 AEB_FCWactivationRequest2 0 "No request" 1 "AEB OFF / FCW OFF" 2 "AEB OFF / FCW ON" 3 "AEB ON / FCW OFF" 4 "AEB ON / FCW ON" 5 "Not used" 6 "Not used" 7 "Reset request";
VAL_ 1482 LDW_SensibilityRequest2 0 "No request" 1 "Low sensibility request" 2 "Middle sensibility request" 3 "High sensibility request" 4 "Not Used" 5 "Not Used" 6 "Not Used" 7 "Reset request";
VAL_ 1482 FKP_ActivationRequest2 0 "No Request" 1 "Flank Protection NOT requested" 2 "Flank Protection Requested" 3 "Reset Request";
VAL_ 1482 DW_ActivationRequest2 0 "No request" 1 "DW Activation request" 2 "DW Deactivation request" 3 "Reset request";
VAL_ 1482 BSWrad_ActivationRequest2 0 "No request" 1 "Activation" 2 "Deactivation" 3 "Reset request";
VAL_ 1482 HandDrivingActivationRequest2 0 "No request" 1 "Right Hand Driving requested" 2 "Left Hand Driving requested" 3 "Reset request";
VAL_ 1482 LKA_ActivationRequest2 0 "No request" 1 "Activation" 2 "Deactivation" 3 "Reset request";
VAL_ 1482 CTA_ActivationRequest2 0 "No request" 1 "Activation" 2 "Deactivation" 3 "Reset request";
VAL_ 1482 LCA_ActivationRequest2 0 "No request" 1 "Activation" 2 "Deactivation" 3 "Reset request";
VAL_ 1485 RemoteFunctionService_BCM 0 "Table Value16365";
VAL_ 1486 ChargeAutonomyDisplayAtAPrct 0 "No Display";
VAL_ 1486 ChargeAutonomyDisplayAtBPrct 0 "No Display";
VAL_ 1486 ChargeAutonomyDisplayAtCPrct 0 "No Display";
VAL_ 1486 ChargeAutonomyDisplayAtDPrct 0 "No Display";
VAL_ 1486 ChargePowerEstimateDisplay 0 "No Display";
VAL_ 1486 ChargeAutonomyDisplayAtEPrct 0 "No Display";
VAL_ 1488 ACC_StatusDisplay_v2 0 "No display request" 1 "ACC waiting" 2 "ACC suspended" 3 "ACC activated" 4 "Temporary failure" 5 "Permanent failure" 6 "ACC override" 7 "Not Used";
VAL_ 1491 AutoFrontWiperActivationRequest 0 "No automatic front wiper activation deactivation request" 1 "Automatic Front wiper activation requested" 2 "Automatic Front wiper de-activation requested" 3 "Automatic Front wiper Reset requested";
VAL_ 1491 ParkAssistVolumeRequest 0 "No request " 1 "Level 0 (off)" 2 "Level 1" 3 "Level 2" 4 "Level 3" 5 "Level 4" 6 "Level 5" 7 "Reset request";
VAL_ 1491 IKeyAccessActivationRequest 0 "No Request" 1 "iKey Access Activation request" 2 "iKey Access Desactivation request" 3 "Reset Request";
VAL_ 1491 FrontRearWiperDropRequest 0 "No drop wiper activation de-activation request" 1 "Drop wiper activation requested" 2 "Drop wiper de-activation requested" 3 "Drop wiper reset requested";
VAL_ 1491 FrontParkAssistActivationReq 0 "No request" 1 "Front parking assistance activation requested" 2 "Front parking assistance de-activation requested" 3 "Reset Request";
VAL_ 1491 AutoRearWiperActivationRequest 0 "No automatic rear wiper activation de-activation request" 1 "Automatic Rear wiper activation requested" 2 "Automatic Rear wiper de-activation requested" 3 "Reset request";
VAL_ 1491 WGSactivationRequest 0 "No request" 1 "Activation" 2 "Deactivation" 3 "Reset request";
VAL_ 1491 RearParkAssistActivationReq 0 "No request" 1 "Rear parking assistance activation requested" 2 "Rear parking assistance de-activation requested" 3 "Reset Request";
VAL_ 1491 MotorwayFlashersNumberRequest 0 "No request" 1 "1 flash per CSW mode request" 2 "3 flash per CSW mode request" 3 "5 flash per CSW mode request" 4 "Not used" 5 "Not used" 6 "Not used" 7 "Reset request";
VAL_ 1491 AutoFMHactivationRequest 0 "No request" 1 "Activation" 2 "Deactivation" 3 "Reset request";
VAL_ 1491 SilentModeActivationRequest 0 "No Request" 1 "Silent Mode Activation Request" 2 "Silent mode Deactivation Request" 3 "Reset Request";
VAL_ 1491 AutoFoldingActivationRequest 0 "No request" 1 "Disable" 2 "IGN Unfold" 3 "Unlock + IGN Unfold" 4 "Not used" 5 "Not used" 6 "Not used" 7 "Reset request";
VAL_ 1491 AutoFMHdurationRequest 0 "No request" 1 "30 sec" 2 "45 sec" 3 "60 sec" 4 "90 sec" 5 "120 sec" 6 "150 sec" 7 "180 sec" 8 "Not used" 9 "Not used" 10 "Not used" 11 "Not used" 12 "Not used" 13 "Not used" 14 "Not used" 15 "Reset request";
VAL_ 1492 PnCchargeStationIdentMode 0 "External Identification Mean" 1 "Plug and Charge" 2 "Not used" 3 "Unavailable";
VAL_ 1493 RE_ElecMachineWorkingMode_BLMS 0 "Motor Mode" 1 "Generator Mode";
VAL_ 1499 RemoteFunctionService_HFM 0 "Table Value30439";
VAL_ 1501 OverspeedAlertStatusDisplay 0 "No display" 1 "Activated" 2 "Deactivated" 3 "Failure";
VAL_ 1502 MultiDriveMode_ECM_v2 0 "Mode ECM 1 (Normal)" 1 "Mode ECM 2" 2 "Mode ECM 3 (Sport)" 3 "Mode ECM 4" 4 "Mode ECM 5 (Eco)" 5 "Mode ECM 6 (Race)" 6 "Mode ECM 7 (Snow)" 7 "Mode8" 8 "Mode9" 9 "Mode10" 10 "Mode11" 11 "Mode12" 12 "Mode13" 13 "Mode14" 14 "Not used" 15 "Unavailable";
VAL_ 1505 ClimFPBlowerRequest 0 "No Request" 1 "Level 1" 2 "Level 2" 3 "Level 3" 4 "Level 4" 5 "Level 5" 6 "Level 6" 7 "Level 7" 8 "Level 8" 9 "Level 9" 10 "Level 10" 11 "Level 11" 12 "Level 12" 13 "Level 13" 14 "Level 14" 15 "Blower OFF";
VAL_ 1506 SSU_Movement 0 "Stopped" 1 "Opening / Tilt Up" 2 "Closing / Tilt Down" 3 "Anti Pinch";
VAL_ 1506 SRU_Movement 0 "Stopped" 1 "Opening / Tilt Up" 2 "Closing / Tilt Down" 3 "Anti Pinch";
VAL_ 1506 WindowPositionExtended_FR 0 "Position invalid" 1 "Fully Close 0%" 2 "Position 5%" 3 "Position 10%" 4 "Position 15%" 5 "Position 20%" 6 "Position 25%" 7 "Position 30%" 8 "Position 35%" 9 "Position 40%" 10 "Position 45%" 11 "Position 50%" 12 "Position 55%" 13 "Position 60%" 14 "Position 65%" 15 "Position 70%" 16 "Position 75%" 17 "Position 80%" 18 "Position 85%" 19 "Position 90%" 20 "Position 95%" 21 "Fully Open 100%" 22 "Reserved" 23 "Reserved" 24 "Reserved" 25 "Reserved" 26 "Reserved" 27 "Reserved" 28 "Reserved" 29 "Reserved" 30 "Reserved" 31 "Reserved";
VAL_ 1506 WindowPositionExtended_FL 0 "Position invalid" 1 "Fully Close 0%" 2 "Position 5%" 3 "Position 10%" 4 "Position 15%" 5 "Position 20%" 6 "Position 25%" 7 "Position 30%" 8 "Position 35%" 9 "Position 40%" 10 "Position 45%" 11 "Position 50%" 12 "Position 55%" 13 "Position 60%" 14 "Position 65%" 15 "Position 70%" 16 "Position 75%" 17 "Position 80%" 18 "Position 85%" 19 "Position 90%" 20 "Position 95%" 21 "Fully Open 100%" 22 "Reserved" 23 "Reserved" 24 "Reserved" 25 "Reserved" 26 "Reserved" 27 "Reserved" 28 "Reserved" 29 "Reserved" 30 "Reserved" 31 "Reserved";
VAL_ 1506 WindowPositionExtended_RR 0 "Position invalid" 1 "Fully Close 0%" 2 "Position 5%" 3 "Position 10%" 4 "Position 15%" 5 "Position 20%" 6 "Position 25%" 7 "Position 30%" 8 "Position 35%" 9 "Position 40%" 10 "Position 45%" 11 "Position 50%" 12 "Position 55%" 13 "Position 60%" 14 "Position 65%" 15 "Position 70%" 16 "Position 75%" 17 "Position 80%" 18 "Position 85%" 19 "Position 90%" 20 "Position 95%" 21 "Position 100%" 22 "Not used" 23 "Not used" 24 "Not used" 25 "Not used" 26 "Not used" 27 "Not used" 28 "Not used" 29 "Not used" 30 "Not used" 31 "Not used";
VAL_ 1506 WindowPositionExtended_RL 0 "Position invalid" 1 "Fully Close 0%" 2 "Position 5%" 3 "Position 10%" 4 "Position 15%" 5 "Position 20%" 6 "Position 25%" 7 "Position 30%" 8 "Position 35%" 9 "Position 40%" 10 "Position 45%" 11 "Position 50%" 12 "Position 55%" 13 "Position 60%" 14 "Position 65%" 15 "Position 70%" 16 "Position 75%" 17 "Position 80%" 18 "Position 85%" 19 "Position 90%" 20 "Position 95%" 21 "Fully Open 100%" 22 "Reserved" 23 "Reserved" 24 "Reserved" 25 "Reserved" 26 "Reserved" 27 "Reserved" 28 "Reserved" 29 "Reserved" 30 "Reserved" 31 "Reserved";
VAL_ 1506 SSU_Position 0 "SunShade position invalid" 1 "SunShade position 0 (closed)(Shade Full Close)" 2 "SunShade sector 01(Shade 0%_8.4% Open)" 3 "SunShade position 1(Shade 8.4%_16.7% Open)" 4 "SunShade sector 12(Shade 16.7%_25% Open)" 5 "SunShade position 2(Shade 25.0%_33.4% Open)" 6 "SunShade sector 23(Shade 33.4%_41.6% Open)" 7 "SunShade position 3(Shade 41.6%_50% Open)" 8 "SunShade sector 34(Shade 50%_58.4% Open)" 9 "SunShade position 4(Shade 58.4%_66.7% Open)" 10 "SunShade synchro 1(Shade 66.7%_75.0% Open)" 11 "SunShade synchro 2(Shade 75.0%_83.4% Open)" 12 "SunShade synchro 3(Shade 83.4%_91.6% Open)" 13 "SunShade synchro 4(Shade 91.6%_100.0% Open)" 14 "SunShade synchro 5(Shade full Open software open end)" 15 "SunShade synchro 6(Shade mechanical open end)";
VAL_ 1508 RESPreSoak_ProgStatus 0 "No programmed" 1 "1 time only (RES or Presoak)" 2 "Every two hours (5 times max)" 3 "Not used";
VAL_ 1508 RESPreSoak_SmartphoneError 0 "No Error" 1 "RES not activated" 2 "Duration Error between 2 RES cycles" 3 "TCU authent Error" 4 "Not used" 5 "Not used" 6 "Not used" 7 "Not used";
VAL_ 1508 VolumetricAlarmLastTrigger 0 "no triggering" 1 "volumetric triggering" 2 "anti-lifting triggering" 3 "perimetric triggering";
VAL_ 1508 AlarmState 0 "alarm off" 1 "alarm on";
VAL_ 1508 RearWiperSwitchStatus 0 "Off" 1 "Intermittent" 2 "Continuous" 3 "Not used";
VAL_ 1508 FrontWiperSwitchStatus 0 "Off" 1 "Intermittent or auto" 2 "Low speed" 3 "High speed" 4 "Mist" 5 "Not used" 6 "Not used" 7 "Not used";
VAL_ 1508 RES_ProgrammationForbidden 0 "Programmation authorized" 1 "Programmation forbidden";
VAL_ 1508 RST_Boost_Button 0 "Not pushed" 1 "Pushed";
VAL_ 1509 RemoteFunctionService_TCU 0 "Table Value30440";
VAL_ 1510 FixedMaintenanceRange 254 "Fixed maintenance requested within one month" 255 "Fixed maintenance requested (time over)";
VAL_ 1510 AlertMinBeforeOverhaul 0 "No Alert " 1 "Time Prealert" 2 "Distance Prealert" 3 "Overhaul Alert";
VAL_ 1511 WheelStateRL 0 "Pressure ok and no failure" 1 "Failure" 2 "Underinflation" 3 "Underinflation and failure" 4 "Puncture" 5 "Puncture and failure" 6 "Puncture and underinflation" 7 "Puncture and underinflation and failure";
VAL_ 1511 WheelStateRR 0 "Pressure ok and no failure" 1 "Failure" 2 "Underinflation" 3 "Underinflation and failure" 4 "Puncture" 5 "Puncture and failure" 6 "Puncture and underinflation" 7 "Puncture and underinflation and failure";
VAL_ 1511 WheelStateFL 0 "Pressure ok and no failure" 1 "Failure" 2 "Underinflation" 3 "Underinflation and failure" 4 "Puncture" 5 "Puncture and failure" 6 "Puncture and underinflation" 7 "Puncture and underinflation and failure";
VAL_ 1511 WheelStateFR 0 "Pressure ok and no failure" 1 "Failure" 2 "Underinflation" 3 "Underinflation and failure" 4 "Puncture" 5 "Puncture and failure" 6 "Puncture and underinflation" 7 "Puncture and underinflation and failure";
VAL_ 1511 OldPressureFL 0 "Pressure up to date" 1 "Pressure not up to date";
VAL_ 1511 OldPressureFR 0 "Pressure up to date" 1 "Pressure not up to date";
VAL_ 1511 OldPressureRL 0 "Pressure up to date" 1 "Pressure not up to date";
VAL_ 1511 OldPressureRR 0 "Pressure up to date" 1 "Pressure not up to date";
VAL_ 1516 TSR_OSPActivationRequest 0 "No request" 1 "TSR/OSP ON request" 2 "TSR/OSP OFF request" 3 "Reset Requested";
VAL_ 1516 LDW_ActivationRequest 0 "No request" 1 "LDW activation request" 2 "LDW de-activation request" 3 "Reset request";
VAL_ 1516 LDW_VibrationIntensityReq 0 "No request" 1 "Low intensity request" 2 "Middle intensity request" 3 "High intensity request" 4 "Not used" 5 "Not used" 6 "Not used" 7 "Reset request";
VAL_ 1516 LDW_SoundLevelRequest_v2 0 "No request" 1 "Level 0" 2 "Level 1" 3 "Level 2" 4 "Level 3" 5 "Level 4" 6 "Level 5" 7 "Reset request";
VAL_ 1516 AEB_FCWactivationRequest 0 "No request" 1 "AEB OFF / FCW OFF" 2 "AEB OFF / FCW ON" 3 "AEB ON / FCW OFF" 4 "AEB ON / FCW ON" 5 "Not used" 6 "Not used" 7 "Reset request";
VAL_ 1516 LDW_SensibilityRequest 0 "No request" 1 "Low sensibility request" 2 "Middle sensibility request" 3 "High sensibility request" 4 "Not Used" 5 "Not Used" 6 "Not Used" 7 "Reset request";
VAL_ 1516 FKP_ActivationRequest 0 "No Request" 1 "Flank Protection NOT requested" 2 "Flank Protection Requested" 3 "Reset Request";
VAL_ 1516 DW_ActivationRequest 0 "No request" 1 "DW Activation request" 2 "DW Deactivation request" 3 "Reset request";
VAL_ 1516 BSWrad_ActivationRequest 0 "No request" 1 "Activation request" 2 "Deactivation request" 3 "Reset requested";
VAL_ 1516 HFP_DefaultManeuverTypeRequest 0 "no request" 1 "park in / parallel" 2 "park in / perpendicular" 3 "park in / angled" 4 "park out" 5 "Not used" 6 "Not used" 7 "Reset Request";
VAL_ 1516 LKA_ActivationRequest 0 "No request" 1 "Activation" 2 "Deactivation" 3 "Reset request";
VAL_ 1516 UTA_AlertActivationRequest 0 "No Request" 1 "UTA Alert activation Request" 2 "UTA Alert desactivation Request" 3 "Reset Request";
VAL_ 1516 CTA_ActivationRequest 0 "No request" 1 "Activation" 2 "Deactivation" 3 "Reset request";
VAL_ 1516 LCA_ActivationRequest 0 "No request" 1 "Activation" 2 "Deactivation" 3 "Reset request";
VAL_ 1519 CurrentUserState_v2 0 "Guest" 1 "User 1" 2 "User 2" 3 "User 3" 4 "User 4" 5 "User 5" 6 "Not used" 7 "Unavailable";
VAL_ 1519 MC_PositionRecallRequest 0 "No request" 1 "Recall MC position 1" 2 "Recall MC position 2" 3 "Recall MC position 3" 4 "Recall MC position 4" 5 "Recall MC position 5" 6 "Recall MC position 6" 7 "Recall MC position 7" 8 "Recall MC position 8" 9 "Recall MC position 9" 10 "Recall MC position 10" 11 "Recall MC position 11" 12 "Recall MC position 12" 13 "Recall MC position 13" 14 "Recall MC position 14" 15 "Reset Request";
VAL_ 1519 MC_PositionSaveRequest 0 "No request" 1 "Save MC position 1" 2 "Save MC position 2" 3 "Save MC position 3" 4 "Save MC position 4" 5 "Save MC position 5" 6 "Save MC position 6" 7 "Save MC position 7" 8 "Save MC position 8" 9 "Save MC position 9" 10 "Save MC position 10" 11 "Save MC position 11" 12 "Save MC position 12" 13 "Save MC position 13" 14 "Save MC position 14" 15 "Unavailable";
VAL_ 1526 CHG_FaultType_BLMS 0 "No failure" 1 "Failure 1" 2 "Failure 2" 3 "Failure 3" 4 "Failure 4" 5 "Failure 5" 6 "Failure 6" 7 "Failure 7";
VAL_ 1526 ME_ElecMachineWorkingMode_BLMS 0 "Motor mode" 1 "Generator mode";
VAL_ 1526 PowerRelayState_BLMS 0 "Precharge" 1 "Closed" 2 "Opened" 3 "Transitory state" 4 "Risol Relay P Check" 5 "Risol Relay N Check" 6 "not used" 7 "not used";
VAL_ 1526 DCDCstate_BLMS 0 "Starting mode (power not yet available)" 1 "Standby" 2 "Direct Mode" 3 "Unavailable";
VAL_ 1526 ME_InverterActivation_BLMS 0 "Not used" 1 "Inverter Off" 2 "Inverter On" 3 "Inverter ON + préflux" 4 "Voltage Mode" 5 "Prepare to Sleep" 6 "Inverter on Low Efficiency" 7 "Unavailable value";
VAL_ 1526 DCDC_Fault_Type_BLMS 0 "No Fault type" 1 "Fault type 1 DCDC Stopped CLASS C" 2 "Fault type 2 DCDC Stopped CLASS D" 3 "Fault type 3 DCDC Unballast" 4 "Fault type 4 DCDC Safety Barrier lost" 5 "Fault Type 5" 6 "Reserved" 7 "Reserved";
VAL_ 1526 HSGAssistActivation_EVA 0 "HSG assist not activated" 1 "HSG assist activated";
VAL_ 1526 TractionModeStatusDisplay_EVA 0 "No Display" 1 "Hybrid" 2 "Electric" 3 "Battery save" 4 "Battery Charge" 5 "Not used" 6 "Not used" 7 "Not used";
VAL_ 1530 BSWson_ActivationRequest 0 "No request" 1 "Activation request" 2 "Deactivation request" 3 "Reset request";
VAL_ 1530 HUD_TSRactivationRequest 0 "No request" 1 "Activation request" 2 "De-activation request" 3 "Reset request";
VAL_ 1530 WDA_ActivationRequest 0 "No request" 1 "Activation request" 2 "Deactivation request" 3 "Reset request";
VAL_ 1531 AutoFrontWiperActivationRequest2 0 "No automatic front wiper activation deactivation request" 1 "Automatic Front wiper activation requested" 2 "Automatic Front wiper de-activation requested" 3 "Automatic Front wiper Reset requested";
VAL_ 1531 ParkAssistVolumeRequest2 0 "No request " 1 "Level 0 (off)" 2 "Level 1" 3 "Level 2" 4 "Level 3" 5 "Level 4" 6 "Level 5" 7 "Reset request";
VAL_ 1531 IKeyAccessActivationRequest2 0 "No Request" 1 "iKey Access Activation request" 2 "iKey Access Desactivation request" 3 "Reset Request";
VAL_ 1531 FrontRearWiperDropRequest2 0 "No drop wiper activation de-activation request" 1 "Drop wiper activation requested" 2 "Drop wiper de-activation requested" 3 "Drop wiper reset requested";
VAL_ 1531 FrontParkAssistActivationReq2 0 "No request" 1 "Front parking assistance activation requested" 2 "Front parking assistance de-activation requested" 3 "Reset Request";
VAL_ 1531 AutoRearWiperActivationRequest2 0 "No automatic rear wiper activation de-activation request" 1 "Automatic Rear wiper activation requested" 2 "Automatic Rear wiper de-activation requested" 3 "Reset request";
VAL_ 1531 WGSactivationRequest2 0 "No request" 1 "Activation" 2 "Deactivation" 3 "Reset request";
VAL_ 1531 RearParkAssistActivationReq2 0 "No request" 1 "Rear parking assistance activation requested" 2 "Rear parking assistance de-activation requested" 3 "Reset Request";
VAL_ 1531 MotorwayFlashersNumberRequest2 0 "No request" 1 "1 flash per CSW mode request" 2 "3 flash per CSW mode request" 3 "5 flash per CSW mode request" 4 "Not used" 5 "Not used" 6 "Not used" 7 "Reset request";
VAL_ 1531 AutoFMHactivationRequest2 0 "No request" 1 "Activation" 2 "Deactivation" 3 "Reset request";
VAL_ 1531 SilentModeActivationRequest2 0 "No Request " 1 "Silent mode Activation Request " 2 "Silent Mode Deactivation Request " 3 "Reset Request";
VAL_ 1531 AutoFoldingActivationRequest2 0 "No request" 1 "Disable" 2 "IGN Unfold" 3 "Unlock + IGN Unfold" 4 "Not used" 5 "Not used" 6 "Not used" 7 "Reset request";
VAL_ 1531 AutoFMHdurationRequest2 0 "No request" 1 "30 sec" 2 "45 sec" 3 "60 sec" 4 "90 sec" 5 "120 sec" 6 "150 sec" 7 "180 sec" 8 "Not used" 9 "Not used" 10 "Not used" 11 "Not used" 12 "Not used" 13 "Not used" 14 "Not used" 15 "Reset request";
VAL_ 1533 V2X_Meter_MainSwitchState 0 "Main Switch OFF" 1 "Main Switch ON";
VAL_ 1533 V2X_Meter_SubSwitchState 0 "Table Value221793";
VAL_ 1535 Security1 0 "Table Value16341";
VAL_ 1535 Security2 0 "Table Value16342";
VAL_ 1535 Security3 0 "Table Value16343";
VAL_ 1535 Security6 0 "Table Value16346";
VAL_ 1535 Security5 0 "Table Value16345";
VAL_ 1535 Security4 0 "Table Value16344";
VAL_ 1535 Security7 0 "Table Value16347";
VAL_ 1537 ACC_TargetDistanceAlert 0 "No ACC warning" 1 "ACC approach warning" 2 "ACC collision warning" 3 "ACC cancel warning";
VAL_ 1537 ACC_TargetDistanceDisplay 0 "No detected target" 1 "Long detected distance" 2 "Middle detected distance" 3 "Short detected distance" 4 "Reglementary detected distance" 5 "Reserved" 6 "Reserved" 7 "Reserved";
VAL_ 1537 ACC_DistanceSettingDisplay 0 "No display" 1 "Short distance" 2 "Middle distance" 3 "Long distance" 4 "Reglementary detected distance" 5 "Very long distance" 6 "Reserved" 7 "Reserved";
VAL_ 1538 LDW_AlertStatus 0 "No alert" 1 "Right alert" 2 "Left alert" 3 "Not used";
VAL_ 1538 WDA_ActivationState 0 "Activated" 1 "Deactivated";
VAL_ 1538 WDA_DriverAttentionLevel 0 "No display" 1 "System OFF" 2 "Level 1" 3 "Level 2" 4 "Level 3" 5 "Level 4" 6 "Level 5" 7 "Level 6" 8 "Level 7" 9 "Level 8" 10 "Indicator check" 11 "Not used" 12 "Not used" 13 "Not used" 14 "System stand by" 15 "System malfunction";
VAL_ 1543 KeyRemoteUnProtectStatus 0 "Protect" 1 "UnProtect";
VAL_ 1543 ADB_ActivationStatusDisplay 0 "ADB not activated" 1 "ADB activated";
VAL_ 1543 MirrorDownDisplayRequest 0 "No mirror down display request" 1 "Mirror down display request";
VAL_ 1543 MirrorUpDisplayRequest 0 "No mirror up display request" 1 "Mirror up display request";
VAL_ 1543 MirrorRightDisplayRequest 0 "No mirror right display request" 1 "Mirror right display request";
VAL_ 1543 MirrorLeftDisplayRequest 0 "No mirror left display request" 1 "Mirror left display request";
VAL_ 1543 MirrorSideSelectDisplayRequest 0 "No mirror selected" 1 "Left mirror selected" 2 "Right mirror selected" 3 "Not Used";
VAL_ 1543 AmbiLightColorStatus_v2 0 "Color 1" 1 "Color 2" 2 "Color 3" 3 "Color 4" 4 "Color 5" 5 "Color 6" 6 "Color 7" 7 "Color 8" 8 "Color 9" 9 "Color 10" 10 "Color 11" 11 "Color 12" 12 "Color 13" 13 "Color 14" 14 "Color 15" 15 "Color 16" 16 "Color 17" 17 "Color 18" 18 "Color 19" 19 "Color 20" 20 "Color 21" 21 "Color 22" 22 "Color 23" 23 "Color 24" 24 "Color 25" 25 "Color 26" 26 "Color 27" 27 "Color 28" 28 "Color 29" 29 "Color 30" 30 "Color 31" 31 "Color 32" 32 "Color 33" 33 "Color 34" 34 "Color 35" 35 "Color 36" 36 "Color 37" 37 "Color 38" 38 "Color 39" 39 "Color 40" 40 "Color 41" 41 "Color 42" 42 "Color 43" 43 "Color 44" 44 "Color 45" 45 "Color 46" 46 "Color 47" 47 "Color 48" 48 "Color 49" 49 "Color 50" 50 "Color 51" 51 "Color 52" 52 "Color 53" 53 "Color 54" 54 "Color 55" 55 "Color 56" 56 "Color 57" 57 "Color 58" 58 "Color 59" 59 "Color 60" 60 "Color 61" 61 "Color 62" 62 "Color 63" 63 "Color 64" 64 "Color 65" 65 "Color 66" 66 "Color 67" 67 "Color 68" 68 "Color 69" 69 "Color 70" 70 "Color 71" 71 "Color 72" 72 "Color 73" 73 "Color 74" 74 "Color 75" 75 "Color 76" 76 "Color 77" 77 "Color 78" 78 "Color 79" 79 "Color 80" 80 "Color 81" 81 "Color 82" 82 "Color 83" 83 "Color 84" 84 "Color 85" 85 "Color 86" 86 "Color 87" 87 "Color 88" 88 "Color 89" 89 "Color 90" 90 "Color 91" 91 "Color 92" 92 "Color 93" 93 "Color 94" 94 "Color 95" 95 "Color 96" 96 "Color 97" 97 "Color 98" 98 "Color 99" 99 "Color 100" 100 "Color 101" 101 "Color 102" 102 "Color 103" 103 "Color 104" 104 "Color 105" 105 "Color 106" 106 "Color 107" 107 "Color 108" 108 "Color 109" 109 "Color 110" 110 "Color 111" 111 "Color 112" 112 "Color 113" 113 "Color 114" 114 "Color 115" 115 "Color 116" 116 "Color 117" 117 "Color 118" 118 "Color 119" 119 "Color 120" 120 "Color 121" 121 "Color 122" 122 "Color 123" 123 "Color 124" 124 "Color 125" 125 "Color 126" 126 "Color 127" 127 "Color 128";
VAL_ 1551 BatteryWatterTempActivationReq 0 "No activation request" 1 "Battery water temp activation request";
VAL_ 1553 SecondRowCentralSeatStatus 0 "Unavailable" 1 "OFF display" 2 "Heater Low display" 3 "Heater Middle display" 4 "Heater High display" 5 "Ventilated Low display" 6 "Ventilated Middle display" 7 "Ventilated High display";
VAL_ 1553 FrontRightSeatStatus 0 "Unavailable" 1 "OFF display" 2 "Heater Low display" 3 "Heater Middle display" 4 "Heater High display" 5 "Ventilated Low display" 6 "Ventilated Middle display" 7 "Ventilated High display";
VAL_ 1553 FrontLeftSeatStatus 0 "Unavailable" 1 "OFF display" 2 "Heater Low display" 3 "Heater Middle display" 4 "Heater High display" 5 "Ventilated Low display" 6 "Ventilated Middle display" 7 "Ventilated High display";
VAL_ 1553 ClimCabinTempDisplayUnit 0 "display mode in °C" 1 "display mode in °F";
VAL_ 1553 ClimLastFuncModifiedByCustomer_v2 0 "No last action" 1 "Temperature" 2 "Rear Climate" 3 "Rear defrost" 4 "Clearness" 5 "Flow Distribution" 6 "Forced Recycling" 7 "OFF Button" 8 "Blower Level" 9 "Seat heating / ventilating" 10 "Auto" 11 "AC" 12 "Auto Recycling" 13 "Front defrost" 14 "Sync" 15 "Steering Wheel Heater";
VAL_ 1560 EngineStatus_ICE_EVA 0 "engine stopped" 1 "engine stalled" 2 "engine driven" 3 "engine autonomous";
VAL_ 1562 HVinterlockAlert 0 "No Alert" 1 "High-voltage interlock opened alert";
VAL_ 1564 HVB_OverVoltageAlert 0 "No Alert" 1 "Battery overvoltage alert";
VAL_ 1564 HVB_UnderVoltageAlert 0 "No Alert" 1 "Battery undervoltage alert";
VAL_ 1564 ReacheableUSOCatDepartureTimeAl 0 "No Alert" 1 "Alert";
VAL_ 1570 RIsolFailureAlert 0 "No alert" 1 "Alert";
VAL_ 1570 PWT_PowerLimitationAlert 0 "No alert" 1 "Alert";
VAL_ 1570 PresoakCustomerFeedback 0 "No error" 1 "vehicle already in use" 2 "vehicle not connected to a power source" 3 "traction battery level too low" 4 "presoak not performed for technical reasons" 5 "Not used" 6 "Not used" 7 "Not used";
VAL_ 1570 RangeSaverState 0 "Range saver desactivated" 1 "Range saver activated";
VAL_ 1570 ChargingAlert_v2 0 "No alert" 1 "Plug Unlocking" 2 "Unplug charging cable (EV and/or Spot Side)" 3 "Programmed charge interruption" 4 "Out of Park Position charge interruption" 5 "Start driving charge interruption" 6 "Charge failure" 7 "Prohibition battery rental" 8 "Battery full" 9 "Interruption due to Change profile renegotiation" 10 "Not used" 11 "Not used" 12 "Not used" 13 "Not used" 14 "Not used" 15 "Not used";
VAL_ 1570 CHGalertSpotCharge 0 "No Fault Type" 1 "Battery charge impossible with AC charge" 2 "Battery charge impossible with DC charge" 3 "Connexion Problem" 4 "Spot To Check" 5 "Power Supply Cutoff" 6 "Plug Signal lost" 7 "not used";
VAL_ 1570 ChargeAvailable 0 "Charge not available " 1 "Charge available";
VAL_ 1571 ProgrammedChargeStatus_HEVC 0 "No display (default value)" 1 "Always authorized charge" 2 "Delayed charge" 3 "Programmed charge by Calendar" 4 "Smartcharging" 5 "AC V2G" 6 "Not Used" 7 "Not Used";
VAL_ 1572 EnergyMode 0 "Hybride Mode SOC depleting" 1 "Hybride Mode SOC Constant" 2 "EV Mode" 3 "Not used";
VAL_ 1573 BMS_FaultType_BLMS 0 "No failure" 1 "Reserved for safety" 2 "Reserved for safety" 3 "High Voltage battery level 1 failure" 4 "Reserved for safety" 5 "Safety mode 1 flag" 6 "High Voltage battery level 2 failure" 7 "Reserved for safety";
VAL_ 1573 BMS2_FaultType_BLMS 0 "No failure" 1 "Reserved for safety" 2 "Reserved for safety" 3 "High Voltage battery level 1 failure" 4 "Reserved for safety" 5 "Safety mode 1 flag" 6 "High Voltage battery level 2 failure" 7 "Reserved for safety";
VAL_ 1573 OperatingTypeStatus_BLMS 0 "No request" 1 "Isolated charge" 2 "Non-isolated charge" 3 "External charge (battery outside vehicle)" 4 "Transitory" 5 "Driving" 6 "Init" 7 "DC Charging without RISOL" 8 "risolCheckMode" 9 "DC Charging with RISOL" 10 "V2G" 11 "V2L" 12 "Reserved" 13 "Reserved" 14 "Reserved" 15 "Reserved";
VAL_ 1578 Drowsy_LevelStatus 0 "No display" 1 "Drowsy level 1" 2 "Drowsy level 2" 3 "Drowsy level 3" 4 "Drowsy level 4" 5 "Drowsy level 5" 6 "Drowsy level 6" 7 "Not Used";
VAL_ 1578 Drowsy_AlertStatus 0 "No Alert" 1 "Alert Off" 2 "Warning Alert" 3 "Danger Alert";
VAL_ 1578 Drowsy_AlertActivationState 0 "Unavailable" 1 "Activated" 2 "Deactivated" 3 "Not used";
VAL_ 1578 Distraction_AlertActivationState 0 "Unavailable" 1 "Activated" 2 "Deactivated" 3 "Not used";
VAL_ 1582 BSG_DeactivationStatus_48V 0 "Unavailable" 1 "BSG Stopped" 2 "BSG activated" 3 "Not Used";
VAL_ 1582 BSG_DeactivationRequest_48V 0 "No Request" 1 "Zero Torque Regulation" 2 "Deactivation Request" 3 "Not Used";
VAL_ 1582 BSG_FaultType 0 "No FaultType" 1 "Fault Type 1" 2 "Fault Type 2" 3 "Safety reserved" 4 "Fault Type 3" 5 "Fault Type 4" 6 "Fault Type 5" 7 "Fault Type 6";
VAL_ 1586 NumberOfPhasesUsed_BLMS 0 "one phase" 1 "two phases" 2 "three Phases" 3 "Unvailable Value";
VAL_ 1592 HVbatConditioningMode 0 "No request" 1 "Cooling by Chiller" 2 "Heating Recovery" 3 "Heating by PTC" 4 "Battery Range Boost" 5 "Cooling by Radiator" 6 "Heating Recovery without Battery" 7 "Not used" 8 "Not used" 9 "Not used" 10 "Not used" 11 "Not used" 12 "Not used" 13 "Not used" 14 "Not used" 15 "Not used";
VAL_ 1592 CoolingBattery_HVACmode 0 "No battery cooling requested" 1 "Battery cooling on going" 2 "Not used" 3 "Unavailable";
VAL_ 1592 PresoakImmediate_HVACmode 0 "No Immediate Presoak Requested" 1 "Immediate Presoak in progress" 2 "Not used" 3 "Unavailable";
VAL_ 1592 PreConditioningBattery_HVACmode 0 "No Battery Preconditionning requested" 1 "Battery Preconditionning on going" 2 "Not used" 3 "Unavailable";
VAL_ 1595 Drowsy_AlertActivationRequest2 0 "No request" 1 "Drowsy alert activation" 2 "Drowsy alert deactivation" 3 "Reset request";
VAL_ 1595 OSE_ActivationRequest2 0 "No request" 1 "Activation request" 2 "Deactivation request" 3 "Reset request";
VAL_ 1596 CurrentPhoneStatus 0 "No call on going" 1 "Incoming call" 2 "Call on going" 3 "Automatic put on hold" 4 "Manual put on hold" 5 "Rejected call" 6 "Missed call" 7 "Call ended";
VAL_ 1596 CurrentAudioSource_v2 0 "All Off" 1 "Radio" 2 "CD DA" 3 "CD MP3" 4 "BT" 5 "SD" 6 "Aux" 7 "IPod" 8 "USB1" 9 "USB2" 10 "DVD" 11 "Blu-Ray" 12 "DTV" 13 "CarPlay" 14 "AndroidAuto" 15 "other sources";
VAL_ 1596 CurrentRadioBand_v2 0 "FM" 1 "AM" 2 "Digital radio" 3 "SXM" 4 "HD Radio" 5 "DAB" 6 "DRM" 7 "Not used";
VAL_ 1608 V2X_EVSEdischarge 0 "Other" 1 "Charging" 2 "Discharging" 3 "Charging/Discharging";
VAL_ 1614 CASP_ActivationRequest2 0 "No Request" 1 "Activation request" 2 "Deactivation request" 3 "Reset request";
VAL_ 1616 APA_WarningDisplayRequest2 0 "no message" 1 "message1" 2 "message2" 3 "message3" 4 "message4" 5 "message5" 6 "message6" 7 "message7" 8 "message8" 9 "message9" 10 "message10" 11 "message11" 12 "message12" 13 "message13" 14 "message14" 15 "message15" 16 "message16" 17 "message17" 18 "message18" 19 "message19" 20 "message20" 21 "message21" 22 "message22" 23 "message23" 24 "message24" 25 "message25" 26 "message26" 27 "message27" 28 "message28" 29 "message29" 30 "message30" 31 "message31" 32 "message32" 33 "message33" 34 "message34" 35 "message35" 36 "message36" 37 "message37" 38 "message38" 39 "message39" 40 "message40" 41 "message41" 42 "message42" 43 "message43" 44 "message44" 45 "message45" 46 "message46" 47 "message47" 48 "message48" 49 "message49" 50 "message50" 51 "message51" 52 "message52" 53 "message53" 54 "message54" 55 "message55" 56 "message56" 57 "message57" 58 "message58" 59 "message59" 60 "message60" 61 "message61" 62 "message62" 63 "Not used";
VAL_ 1624 V2G_OEMRootCert_Status 0 "Not Installed" 1 "Installed" 2 "Expired" 3 "Errors";
VAL_ 1624 CertificateInstallationStatus 0 "No display (default value)" 1 "Reception in progress" 2 "Transfer successful" 3 "Certificate consistent" 4 "Operation successful (installation/uninstallation)" 5 "Transfer error: bloc sequence not valid" 6 "Transfer error: resegmenting error" 7 "Certificate error: not valid (expired)" 8 "Certificate error: signature verification error" 9 "Certificate error: private key decryption error" 10 "Certificate error: certificate not matching private/public key" 11 "OCSP response expired" 12 "Revocation failed" 13 "Not Used" 14 "Operation failed (installation/uninstallation)" 15 "Not Used";
VAL_ 1624 PLCReceptionAvailability 0 "Default value" 1 "Ready to receive" 2 "Not ready to receive" 3 "Not Used";
VAL_ 1624 PnC_OEMProvCert_Status 0 "Not Installed" 1 "Installed" 2 "Expired" 3 "Errors";
VAL_ 1624 PnC_LegOEMRootCert_Status 0 "Not Installed" 1 "Installed" 2 "Expired" 3 "Errors";
VAL_ 1624 PnC_OEMRootCert_Status 0 "Not Installed" 1 "Installed" 2 "Expired" 3 "Errors";
VAL_ 1624 V2G_VehicleCert_Status 0 "Not Installed" 1 "Installed" 2 "Expired" 3 "Errors";
VAL_ 1624 PnC_MOSub2Cert_Status 0 "Not Installed" 1 "Installed" 2 "Expired" 3 "Errors";
VAL_ 1624 PnC_MOSub1Cert_Status 0 "Not Installed" 1 "Installed" 2 "Expired" 3 "Errors";
VAL_ 1625 PnC_Contract_Certificate_Status 0 "Not installed" 1 "installed" 2 "expired" 3 "errors";
VAL_ 1628 V2L_SystemStatusDisplay 0 "No display" 1 "ALL OFF" 2 "V2L Inside ON" 3 "V2L Outside ON" 4 "V2L Both ON" 5 "V2L Disabled with error" 6 "Not Used" 7 "Unavailable value";
VAL_ 1628 V2L_SettingModeState 0 "ALL OFF" 1 "System OFF" 2 "System ON" 3 "Not Used";
VAL_ 1628 V2L_FrequencySettingState 0 "50 Hz" 1 "60 Hz" 2 "Not used" 3 "Unavailable";
VAL_ 1628 V2X_SystemFailureDisplay 0 "No display" 1 "V2X stopped because of low SOC" 2 "Low SOC for V2X" 3 "V2X System failure(Leakage current detection etc)" 4 "V2G aborted due to communication failure" 5 "V2G aborted due to technical failure" 6 "V2L stopped due to timeout" 7 "Unavailable value";
VAL_ 1628 V2L_PlugStatus 0 "No display" 1 "V2L plug available" 2 "V2L plug not available" 3 "Not Used";
VAL_ 1628 V2L_SystemAvailability 0 "No display" 1 "V2L Inside available" 2 "V2L Outside available" 3 "V2L Both available";
VAL_ 1633 V2G_Vehicle_CertifStatus 0 "No Display" 1 "Vehicle Certificate Installed" 2 "Vehicle Certificate not Installed" 3 "Installation in Progress" 4 "Ready to receive" 5 "Signature Verification error" 6 "Resegmenting error" 7 "Transfer error" 8 "Vehicle Certificate expired" 9 "Not used" 10 "Not used" 11 "Not used" 12 "Not used" 13 "Not used" 14 "Not used" 15 "Unavailable value";
VAL_ 1633 PnCCPLCActivationStatus 0 "Enable" 1 "Disable" 2 "Not used" 3 "Unavailable";
VAL_ 1635 V2X_HVBat_EnergyDurabilityWarn 0 "No warning / No Display" 1 "1st inhibition warning" 2 "2nd inhibition warning" 3 "Inhibition of V2G service";
VAL_ 1636 PBD_ActivationState 0 "No activation" 1 "Opening_movement_ongoing" 2 "Closing_movement_ongoing" 3 "Movement_delayed" 4 "Antipinch_movement_ongoing" 5 "Not Used" 6 "Not Used" 7 "Not Used";
VAL_ 1637 SuspensionSettingState 0 "Mode VADA 1 (Normal)" 1 "Mode VADA 2 (Comfort)" 2 "Mode VADA 3 (Sport)" 3 "Mode VADA 4" 4 "Mode VADA 5" 5 "Mode VADA 6 (Race)" 6 "Not used" 7 "Not used";
VAL_ 1637 DriveModeState 0 "Mode 0=NORMAL/STANDARD/AUTO" 1 "Mode 1=ECO" 2 "Mode 2=SPORT/TARMAC" 3 "Mode 3=SPORT+/POWER" 4 "Mode 4=COMFORT" 5 "Mode 5=PERSONAL" 6 "Mode 6=SNOW" 7 "Mode 7" 8 "Mode 8=OFF-ROAD/GRAVEL" 9 "Mode 9=MUD/RUT" 10 "Mode 10=SAND" 11 "Mode 11=TOW" 12 "Mode 12=ALL ROAD/ROCK" 13 "Mode 13=EXTREM" 14 "Mode 14=PERFO" 15 "Mode 15=VITAMIN" 16 "Mode 16=RACE" 17 "Mode 17" 18 "Mode 18" 19 "Mode 19" 20 "Mode 20" 21 "Mode 21" 22 "Mode 22" 23 "Mode 23" 24 "Mode 24" 25 "Mode 25" 26 "Mode 26" 27 "Mode 27" 28 "Mode 28" 29 "Mode 29" 30 "Mode 30" 31 "Unavailable";
VAL_ 1639 ChargingPlugStatus 0 "Not connected" 1 "Connected";
VAL_ 1639 HSG_ElecMachineWorkMode_BLMS 0 "Motor mode" 1 "Generator mode";
VAL_ 1640 SCdurabilityInhibition 0 "No smartcharging inhibition" 1 "Smartcharging inhibited";
VAL_ 1645 AEB_FCWactivationState2 0 "AEB OFF / FCW OFF" 1 "AEB OFF / FCW ON" 2 "Not used" 3 "AEB ON / FCW ON";
VAL_ 1645 AEB_CyclistAlertRequest2 0 "No AEB cyclist alert" 1 "AEB cyclist alert";
VAL_ 1645 AEB_PedestrianAlertRequest2 0 "No AEB PEDESTRIAN alert" 1 "AEB PEDESTRIAN alert";
VAL_ 1645 AEB_VehicleAlertRequest2 0 "No AEB vehicle alert" 1 "AEB vehicle Approach alert" 2 "AEB vehicle Collision alert" 3 "AEB vehicle Alert reminder";
VAL_ 1645 AEB_FailureDisplay2 0 "No display" 1 "Temporary Failure Display" 2 "Permanent Failure Display" 3 "Not used";
VAL_ 1645 AEB_StatusDisplay2_v2 0 "No display" 1 "AEB Off" 2 "operation" 3 "Not operation" 4 "Temporary failure" 5 "Permanent failure" 6 "Initial" 7 "Not Used";
VAL_ 1650 ConnectionData_DVR_WiFi 0 "Table Value414235";
VAL_ 1650 DVR_Incident_state 0 "Unavailable" 1 "Incident Recording start" 2 "Incident Recording end" 3 "Not used";
VAL_ 1650 DataLength_DVR_WiFi 0 "0" 1 "1" 2 "2" 3 "3" 4 "4" 5 "5" 6 "6" 7 "7" 8 "8" 9 "9" 10 "10" 11 "11" 12 "12" 13 "13" 14 "14" 15 "15" 16 "16" 17 "17" 18 "18" 19 "19" 20 "20" 21 "21" 22 "22" 23 "23" 24 "24" 25 "25" 26 "26" 27 "27" 28 "28" 29 "29" 30 "30" 31 "31" 32 "32" 33 "Not used" 34 "Not used" 35 "Not used" 36 "Not used" 37 "Not used" 38 "Not used" 39 "Not used" 40 "Not used" 41 "Not used" 42 "Not used" 43 "Not used" 44 "Not used" 45 "Not used" 46 "Not used" 47 "Not used" 48 "Not used" 49 "Not used" 50 "Not used" 51 "Not used" 52 "Not used" 53 "Not used" 54 "Not used" 55 "Not used" 56 "Not used" 57 "Not used" 58 "Not used" 59 "Not used" 60 "Not used" 61 "Not used" 62 "Not used" 63 "Invalid";
VAL_ 1650 TransportContent_DVR_WiFi 0 "SSID" 1 "Password" 2 "Reserved" 3 "Invalid value";
VAL_ 1650 DataIndex_DVR_WiFi 0 "0" 1 "1" 2 "2" 3 "3" 4 "4" 5 "5" 6 "Reserved" 7 "Reserved" 8 "Reserved" 9 "Reserved" 10 "Reserved" 11 "Reserved" 12 "Reserved" 13 "Reserved" 14 "Reserved" 15 "Invalid";
VAL_ 1654 CoolanttankValveRequest_EVA 0 "no valve requested" 1 "valve requested";
VAL_ 1654 SCU_Button1_EVA 0 "No request" 1 "Button 1 requested";
VAL_ 1655 EVchargingProfileStatus 0 "No Schedule transmitted" 1 "Schedule #1 transmission in progress" 2 "Schedule #2 transmission in progress" 3 "Schedule #3 transmission in progress" 4 "Transmission is finished" 5 "Error" 6 "Not used" 7 "Not used";
VAL_ 1659 IKeyCardDetectionStatus 0 "No information (unavailable)" 1 "IKey in the vehicle" 2 "IKey not in the vehicle" 3 "Not Used";
VAL_ 1660 SecondRowRightSeatStatus 0 "Unvailable" 1 "OFF display" 2 "Heater Low display" 3 "Heater Middle display" 4 "Heater High display" 5 "Ventilated Low display" 6 "Ventilated Middle display" 7 "Ventilated High display";
VAL_ 1660 SecondRowLeftSeatStatus 0 "Unvailable" 1 "OFF display" 2 "Heater Low display" 3 "Heater Middle display" 4 "Heater High display" 5 "Ventilated Low display" 6 "Ventilated Middle display" 7 "Ventilated High display";
VAL_ 1660 ThirdRowRightSeatStatus 0 "Unvailable" 1 "OFF display" 2 "Heater Low display" 3 "Heater Middle display" 4 "Heater High display" 5 "Ventilated Low display" 6 "Ventilated Middle display" 7 "Ventilated High display";
VAL_ 1660 ThirdRowLeftSeatStatus 0 "Unvailable" 1 "OFF display" 2 "Heater Low display" 3 "Heater Middle display" 4 "Heater High display" 5 "Ventilated Low display" 6 "Ventilated Middle display" 7 "Ventilated High display";
VAL_ 1660 ClimSyncDisplay 0 "No display" 1 "Sync mode ON" 2 "Sync mode OFF" 3 "Not Used";
VAL_ 1667 PSD_L_ActivationState 0 "No activation" 1 "Opening_movement_ongoing" 2 "Closing_movement_ongoing" 3 "Movement_delayed" 4 "Antipinch_movement_ongoing" 5 "Not Used" 6 "Not Used" 7 "Not Used";
VAL_ 1669 BSG_MachineModeStatus_48V 0 "Init" 1 "Transitory" 2 "Standby" 3 "Torque Mode" 4 "Voltage Mode" 5 "Speed Mode" 6 "Not Used" 7 "Unavailable Value";
VAL_ 1670 LOB_PositionSaveRequest 0 "No request" 1 "SAVE LOB position 1" 2 "SAVE LOB position 2" 3 "SAVE LOB position 3" 4 "SAVE LOB position 4" 5 "SAVE LOB position 5" 6 "SAVE LOB position 6" 7 "Not Used";
VAL_ 1670 LOB_PositionRecallRequest 0 "No request" 1 "RECALL LOB position 1" 2 "RECALL LOB position 2" 3 "RECALL LOB position 3" 4 "RECALL LOB position 4" 5 "RECALL LOB position 5" 6 "RECALL LOB position 6" 7 "Reset request";
VAL_ 1682 ClimHeatedSteeringWheelDisplay 0 "No display" 1 "Heated Steering Wheel ON" 2 "Heated Steering Wheel OFF" 3 "Not used";
VAL_ 1682 ClimDualModeDisplay_v2 0 "No Display" 1 "Dual Mode ON" 2 "Dual Mode OFF" 3 "Not used";
VAL_ 1682 HVAC_PresoakStateDisplay 0 "No Presoak in progress" 1 "Presoak Forbidden" 2 "Presoak in progress" 3 "Unavailable";
VAL_ 1684 APA_WarningDisplayRequest 0 "no message" 1 "message1" 2 "message2" 3 "message3" 4 "message4" 5 "message5" 6 "message6" 7 "message7" 8 "message8" 9 "message9" 10 "message10" 11 "message11" 12 "message12" 13 "message13" 14 "message14" 15 "message15" 16 "message16" 17 "message17" 18 "message18" 19 "message19" 20 "message20" 21 "message21" 22 "message22" 23 "message23" 24 "message24" 25 "message25" 26 "message26" 27 "message27" 28 "message28" 29 "message29" 30 "message30" 31 "message31" 32 "message32" 33 "message33" 34 "message34" 35 "message35" 36 "message36" 37 "message37" 38 "message38" 39 "message39" 40 "message40" 41 "message41" 42 "message42" 43 "message43" 44 "message44" 45 "message45" 46 "message46" 47 "message47" 48 "message48" 49 "message49" 50 "message50" 51 "message51" 52 "message52" 53 "message53" 54 "message54" 55 "message55" 56 "message56" 57 "message57" 58 "message58" 59 "message59" 60 "message60" 61 "message61" 62 "message62" 63 "Not used";
VAL_ 1684 HFP_MapContentDisplay2 0 "Empty Display" 1 "Scanning Display" 2 "ParkOutConfirmation Display" 3 "Guidance Display";
VAL_ 1685 CGW_FOTAstatus_v2 0 "Idle" 1 "Inventory read in progress" 2 "Inventory read complete" 3 "Menu Package distribution in progress" 4 "Menu Package Integrity check in progress" 5 "Menu Package Integrity check complete" 6 "Gateway Package Distribution in progress" 7 "Gateway Package Integrity check in progress" 8 "Gateway Package Distribution complete" 9 "Parameters check in progress State" 10 "Installation in progress State" 11 "Installation complete State" 12 "Ready for activation State" 13 "Vehicle Condition check in progress" 14 "Switch in progress State" 15 "Reboot in progress" 16 "Component version check in progress" 17 "Configuration install in progress" 18 "Configuration complete" 19 "Activation complete" 20 "Finishing in progress" 21 "FOTA CLIENT related Error detected" 22 "FOTA CLIENT related cancel complete" 23 "Cancel in progress" 24 "Cancel failed" 25 "Cancel complete" 26 "Rollback in progress" 27 "Rollback complete" 28 "Not used" 29 "Not used" 30 "Not used" 31 "Invalid";
VAL_ 1686 DateTimeUTCMalfunction 0 "No malfunction" 1 "Malfunction";
VAL_ 1703 ChargeAuthorization_BCM_v2 0 "Always Authorized" 1 "Forbidden by programmation" 2 "Authorized by programmation" 3 "Authorized by Smarcharging activation" 4 "Forbidden by suspended charge function" 5 "Not used" 6 "Not used" 7 "Not used";
VAL_ 1703 ProgrammedChargeStatus 0 "Always authorized charge" 1 "Delayed charge" 2 "Programmed charge by Calendar" 3 "Not Used";
VAL_ 1706 GearshiftInProgress_EVA 0 "start of gear shifting" 1 "end of gear shifting" 2 "Gear shift in progress" 3 "Not Used";
VAL_ 1706 ParkStatus_EVA 0 "Park not engaged" 1 "Park engaged";
VAL_ 1706 GearboxPositionTarget_EVA 0 "Parking - P" 1 "Reverse - R" 2 "Neutral - N" 3 "Drive - D" 4 "Manual mode - M" 5 "L" 6 "Ds" 7 "B (Brake)";
VAL_ 1706 EngineStatus_EVA 0 "engine stopped" 1 "engine stalled" 2 "engine driven" 3 "engine autonomous";
VAL_ 1720 ADB_ActivationRequest 0 "No ADB request" 1 "ADB activated" 2 "ADB not activated" 3 "Reset request";
VAL_ 1720 HandDrivingActivationRequest 0 "No request" 1 "Right Hand Driving requested" 2 "Left Hand Driving requested" 3 "Reset request";
VAL_ 1729 EngineControlRequest_EVA 0 "Highest Priority" 1 "High Priority" 2 "Low Priority" 3 "2 Low Priority" 4 "No Request" 5 "Not Used" 6 "Not Used" 7 "Not Used";
VAL_ 1729 EngControlWheelDecouplingReq_EVA 0 "Not Requested" 1 "Requested";
VAL_ 1729 ME_DeactivationStatus_EVA 0 "Normal" 1 "Voltage mode activated" 2 "Zero-torque regulation activated" 3 "ME stopped";
VAL_ 1729 ME_DeactivationRequest_EVA 0 "Normal" 1 "Torque interruption request _ voltage mode allowed" 2 "Torque interruption request _ zero torque regulation all" 3 "Torque interruption request _ immediate shut off";
VAL_ 1729 HSG_DeactivationStatus_EVA 0 "Normal" 1 "Voltage mode activated" 2 "Zero-torque regulation activated" 3 "Electrical Machine stopped";
VAL_ 1729 HSG_DeactivationRequest_EVA 0 "Normal" 1 "Torque interruption request _ voltage mode allowed" 2 "Torque interruption request _ zero torque regulation all" 3 "Torque interruption request _ immediate shutoff";
VAL_ 1731 GPFRequest_EVA 0 "heating mod" 1 "RG Lean Burn" 2 "FM" 3 "road request" 4 "cooling" 5 "FCOI" 6 "Not Used" 7 "Not Used";
VAL_ 1732 HM_ENavigationMidDistanceRequest 0 "Enavigation Mid Distance not Requested" 1 "Enavigation Mid Distance Requested";
VAL_ 1732 HM_SOCHighwayActivationState_EVA 0 "SOC Highway not activated" 1 "SOC Highway Activated";
VAL_ 1732 HM_SOCHighVehLoadActStatus_EVA 0 "SOC High Vehicle Load not Activated" 1 "SOC High Vehicle Load Activated";
VAL_ 1732 HybridTractionModeDisplay_V2_EVA 0 "No display" 1 "ZEV mode activated" 2 "Auto mode activated" 3 "Charge Battery" 4 "Sport mode activated" 5 "Temporary no ZEV" 6 "Save Battery level activated" 7 "Not Used";
VAL_ 1737 HVBatEndOfChargeTrigger 0 "No end of charge" 1 "Plug Unlocking" 2 "Unplug charging cable" 3 "Vehicle not immobilized interruption" 4 "Start driving charge interruption" 5 "Prohibition battery rental" 6 "Charge failure" 7 "Programmed charge interruption";
VAL_ 1737 HVBatStartOfChargeTrigger 0 "No charge in progress" 1 "Spot activation" 2 "Schedule to immediate charge" 3 "Plug charging cable";
VAL_ 1738 VirtualKeySuspendReq 0 "No Request" 1 "VK Suspend" 2 "VK Resume" 3 "VK Factory Reset (Switch to Default VK State)";
VAL_ 1738 CASP_ActivationRequest 0 "No Request" 1 "Activation request" 2 "Deactivation request" 3 "Reset request";
VAL_ 1742 ACC_CancelReason_v2 0 "No Alert" 1 "ACC Refused : IntelligentParkAssist / HFPB activated" 2 "Tire slipped" 3 "Parking Brake activated" 4 "Seat belt was unfastened" 5 "Door was opened" 6 "Fr Camera High temperature" 7 "Fr Camera Visibility is Impaired" 8 "FRCamera Permanent Failure" 9 "FrRadar Blocked " 10 "FrRadar Permanent Failure" 11 "Can't hold vehicle(Epkb is not applied)" 12 "ACC refused: RaceMode" 13 "Others By User" 14 "ACC Refused : HDC Active" 15 "ACC Permanent Failure" 16 "ACC Refused : VDC Off" 17 "ACC Refused : Out Of Speed Range" 18 "ACC Refused : AEB Off" 19 "ACC_Refused: Other" 20 "Bad Wheathear" 21 "ACC_Refused: EVPriorityMode activated" 22 "Not used" 23 "Not used" 24 "Not used" 25 "Not used" 26 "Not used" 27 "Not used" 28 "Not used" 29 "Not used" 30 "Not used" 31 "Not used";
VAL_ 1742 AEB_CancelReason_v2 0 "No display" 1 "VDC desactivated by driver (Canceled by)" 2 "VDC in regulation (Canceled by)" 3 "FrCam Blocked" 4 "FrCam High tempearture" 5 "FrCam Permanent Failure" 6 "Radar blocked" 7 "Radar Permanent Failure" 8 "Front side radar blocked" 9 "Front side radar permanent failure" 10 "Trailer Presence" 11 "Race mode" 12 "Bad weather" 13 "Accel Pedal high temp" 14 "ADAS ECU Temporary failure" 15 "ADAS ECU Permanent failure";
VAL_ 1742 LCA_CancelReason 0 "No alert" 1 "LCA refused : ACC not activated" 2 "LCA Permanent Failure" 3 "FrCamera High temperature" 4 "FrCamera Visibility is Impaired" 5 "FrCamera Permanent Failure" 6 "FrRadar Blocked" 7 "FrRadar permanent failure" 8 "LCA Refused : HOD" 9 "LCA Cancel : Target lost" 10 "LCA Cancel : other" 11 "LCA Refused : other" 12 "LCA Refused : Race mode" 13 "Bad weather" 14 "Not used" 15 "Not used";
VAL_ 1742 OSE_CancelReason 0 "No display" 1 "Trailer Presence" 2 "Side Radar Blocked" 3 "Side Radar Permanent Failure" 4 "Left Side Radar Occlusion" 5 "Right Side Radar Occlusion" 6 "Left and Right Side Radar Occlusion" 7 "OSE Permanent Failure";
VAL_ 1742 ELKA_CancelReason_v2 0 "No alert" 1 "Front Camera blocked" 2 "Front Camera permanent failure" 3 "Front Camera high temperature" 4 "Radar blocked" 5 "Radar permanent failure" 6 "Rear Side radar blocked" 7 "Rear Side radar permanent failure" 8 "Trailer presence" 9 "Front Side radar blocked" 10 "Front Side radar permanent failure" 11 "VDC desactivated by driver State" 12 "VDC in regulation State" 13 "Deactivated: Race Mode" 14 "ADAS ECU Temporary failure" 15 "ADAS ECU Permanent failure";
VAL_ 1743 WarmUpRequest_EVA 0 "Not Activated" 1 "Activated";
VAL_ 1743 HSG_ElecSysFailureDisplay_EVA 0 "No Alert" 1 "Alert";
VAL_ 1743 HSG_ElecMotorFailureDisplay_EVA 0 "No Alert" 1 "Alert";
VAL_ 1743 HSG_InverterFault_Type_EVA 0 "No Fault type" 1 "Fault type 1" 2 "Fault type 2" 3 "Safety Reserved" 4 "Fault type 3" 5 "Fault type 4" 6 "Fault type 5" 7 "Reserved";
VAL_ 1743 HSG_ControlMode_EVA 0 "torque mode" 1 "speed mode" 2 "voltage mode" 3 "Not Used";
VAL_ 1743 ME_ElecSysFailureDisplay_EVA 0 "No Alert" 1 "Alert";
VAL_ 1743 ME_ElecMotorFailureDisplay_EVA 0 "No Alert" 1 "Alert";
VAL_ 1743 ME_ControlMode_EVA 0 "torque mode" 1 "speed mode" 2 "voltage mode" 3 "Not Used";
VAL_ 1743 TIAlertDisplay_EVA 0 "No TI Alert" 1 "TI Alert";
VAL_ 1743 V2L_StartStop_Status_EVA 0 "Not available" 1 "start" 2 "in progress" 3 "stop";
VAL_ 1748 HFM_VKM_pairing 0 "Table Value609464";
VAL_ 1749 VKM_HFM_pairing 0 "Table Value609472";
VAL_ 1753 CPLC_FaultType 0 "No Fault" 1 "Contract NOK" 2 "Energy Transfer mode type not supported" 3 "PLC comm failure HLCcommstatus" 4 "EVSE comm Failure" 5 "EVSE Not Ready" 6 "EVSE Shutdown" 7 "EVSE Utility Interrupt Event" 8 "EVSE Isolation Monitoring Active" 9 "EVSE Emergency Shutdown" 10 "EVSE Malfunction Protocol with EVSE (Station charging)" 11 "EVSE_Renegociate" 12 "EVSE Pause" 13 "Certificate Error" 14 "Not used" 15 "Not used";
VAL_ 1754 PnC_ContractRevocation_Status 0 "Not Revoked" 1 "Revoked";
VAL_ 1754 PnC_V2GRootCert_Status 0 "Not Installed" 1 "Installed" 2 "Expired" 3 "Errors";
VAL_ 1755 HVB_HighTempAlert 0 "No Overheat alert" 1 "Overheat alert";
VAL_ 1755 HEVC_PresoakActivationStatus 0 "Presoak Forbidden" 1 "No Presoak in progress" 2 "Presoak in progress" 3 "Unavailable";
VAL_ 1755 ThermalPropagationFiremanAlert 0 "eCall for Firemen not requested" 1 "eCall for Firemen requested";
VAL_ 1755 PnC_Contract_Error 0 "No Display" 1 "Error";
VAL_ 1755 HVbatteryWarmingState 0 "Battery warming OFF" 1 "Battery warming ON";
VAL_ 1756 Privacy_Mode_Request 0 "No request" 1 "Data Sharing forbidden " 2 "Data Sharing allowed" 3 "Geolocation Sharing forbidden" 4 "Reserved" 5 "Reserved" 6 "Reserved" 7 "Reset Request";
VAL_ 1775 PnC_IVC_Transfer_Status_V2 0 "Default value" 1 "Transfer in progress" 2 "Transfer completed" 3 "Ready to transfer" 4 "Not used" 5 "Not used" 6 "Not used" 7 "Unavailable";
VAL_ 1775 ISA_ReportingActivationRequest 0 "No request" 1 "Activation request" 2 "Deactivation request" 3 "Not Used";
VAL_ 1779 ChargeCalAllChange_MMI 0 "No Request" 1 "Change all charge calendars request" 2 "Reset all charge calendars request" 3 "Not used";
VAL_ 1781 ChargeDelayedRequest 0 "No request" 1 "Delayed charge request";
VAL_ 1781 ChargeAlwaysRequest 0 "No request" 1 "Always charge request";
VAL_ 1782 PreSoakCalAllChange_MMI 0 "No Request" 1 "Change all presoak calendars request" 2 "Reset all presoak calendars request" 3 "Not used";
VAL_ 1789 BCM_SRU_SwitchState 0 "Switch position invalid" 1 "SunRoof Switch position 0" 2 "SunRoof Switch position 1" 3 "SunRoof Switch position 2" 4 "SunRoof Switch position 3" 5 "SunRoof Switch position 4" 6 "SunRoof Switch position 5" 7 "SunRoof Switch position 6" 8 "SunRoof Switch position 7" 9 "SunRoof Switch position 8" 10 "SunRoof Switch position 9" 11 "SunRoof Switch position 10" 12 "SunRoof Switch position 11" 13 "SunRoof Switch position 12" 14 "SunRoof Switch position 13" 15 "SunRoof Switch recall";
VAL_ 1789 BCM_SRU_ECUDefect 0 "Error ECU, Relay, Hall or Motor; defect not active" 1 "Error ECU, Relay, Hall or Motor; defect active";
VAL_ 1790 RE_DeactivationStatus_EVA 0 "Normal" 1 "Voltage mode activated" 2 "Zero-torque regulation activated" 3 "RE stopped";
VAL_ 1790 RE_DeactivationRequest_EVA 0 "Normal" 1 "Torque interruption request / voltage mode allowed" 2 "Torque interruption request / zero-torque regulation all" 3 "Torque interruption request / immediate shut-off";
VAL_ 1790 PnCchargeStationCompatibility 0 "No Display" 1 "not compatible";
VAL_ 1790 V2L_ActivationStatusFeedback_EVA 0 "Off" 1 "Inside V2L is ON" 2 "Outside V2L is ON" 3 "Inside and outside V2L is ON";
VAL_ 1791 RE_ElecMotorFailureDisplay_EVA 0 "No Alert" 1 "Alert";
VAL_ 1800 DTOOL_to_MID 0 "Table Value407700";
VAL_ 1832 MID_to_DTOOL 0 "Table Value407699";
VAL_ 1862 DTOOL_to_DOP_TCU 0 "Table Value27361";
VAL_ 1988 eShifter_to_DTOOL 0 "Table Value153063";
VAL_ 1989 DTOOL_to_eShifter 0 "Table Value153062";
VAL_ 2563507968 SIGMA_CDM 0 "Table Value16461";
VAL_ 2563507968 SIGMA_DTCCDM 0 "Table Value26862";
VAL_ 2563508007 SIGMA_eHBox 0 "Table Value430561";
VAL_ 2563508007 SIGMA_DTCeHBox 0 "Table Value430559";
VAL_ 2563508009 SIGMA_PSD_R 0 "Table Value153060";
VAL_ 2563508009 SIGMA_DTCPSD_R 0 "Table Value153056";
VAL_ 2563508019 SIGMA_PBD 0 "Table Value16399";
VAL_ 2563508019 SIGMA_DTCPBD 0 "Table Value26865";
VAL_ 2563508021 SIGMA_RADAR 0 "Table Value16466";
VAL_ 2563508021 SIGMA_DTCRADAR 0 "Table Value26884";
VAL_ 2563508022 SIGMA_PSCU 0 "Table Value16465";
VAL_ 2563508022 SIGMA_DTCPSCU 0 "Table Value26866";
VAL_ 2563508030 SIGMA_SRad_RL 0 "Table Value16470";
VAL_ 2563508030 SIGMA_DTCSRad_RL 0 "Table Value26868";
VAL_ 2563508035 SIGMA_eRDC_L 0 "Table Value252236";
VAL_ 2563508035 SIGMA_DTCeRDC_L 0 "Table Value252232";
VAL_ 2563508037 SIGMA_eRDC_R 0 "Table Value252238";
VAL_ 2563508037 SIGMA_DTCeRDC_R 0 "Table Value252233";
VAL_ 2563508042 SIGMA_ANC 0 "Table Value16458";
VAL_ 2563508042 SIGMA_DTCANC 0 "Table Value26859";
VAL_ 2563508064 SIGMA_VDC 0 "Table Value16380";
VAL_ 2563508064 SIGMA_DTCVDC 0 "Table Value26886";
VAL_ 2563508066 SIGMA_EPS 0 "Table Value16377";
VAL_ 2563508066 SIGMA_DTCEPS 0 "Table Value26879";
VAL_ 2563508067 SIGMA_METER 0 "Table Value16379";
VAL_ 2563508067 SIGMA_DTCMETER 0 "Table Value26883";
VAL_ 2563508068 SIGMA_HVAC 0 "Table Value28686";
VAL_ 2563508068 SIGMA_DTCHVAC 0 "Table Value28682";
VAL_ 2563508069 SIGMA_BCM 0 "Table Value16381";
VAL_ 2563508069 SIGMA_DTCBCM 0 "Table Value26877";
VAL_ 2563508071 SIGMA_IVI 0 "Table Value16383";
VAL_ 2563508071 SIGMA_DTCIVI 0 "Table Value26882";
VAL_ 2563508072 SIGMA_4WD 0 "Table Value28679";
VAL_ 2563508072 SIGMA_DTC4WD 0 "Table Value28678";
VAL_ 2563508077 SIGMA_USM 0 "Table Value16384";
VAL_ 2563508077 SIGMA_DTCUSM 0 "Table Value26885";
VAL_ 2563508078 SIGMA_SONAR 0 "Table Value28703";
VAL_ 2563508078 SIGMA_DTCSONAR 0 "Table Value28702";
VAL_ 2563508079 SIGMA_DSMU 0 "Table Value16462";
VAL_ 2563508079 SIGMA_DTCDSMU 0 "Table Value26863";
VAL_ 2563508082 SIGMA_ACU 0 "Table Value16374";
VAL_ 2563508082 SIGMA_DTCACU 0 "Table Value26874";
VAL_ 2563508089 SIGMA_PSD_L 0 "Table Value153059";
VAL_ 2563508089 SIGMA_DTCPSD_L 0 "Table Value153054";
VAL_ 2563508093 SIGMA_ADAS 0 "Table Value16457";
VAL_ 2563508093 SIGMA_DTCADAS 0 "Table Value26875";
VAL_ 2563508099 SIGMA_A_IVC 0 "Table Value16456";
VAL_ 2563508099 SIGMA_DTCA_IVC 0 "Table Value26858";
VAL_ 2563508108 SIGMA_INV_ME 0 "Table Value27356";
VAL_ 2563508108 SIGMA_DTCINV_ME 0 "Table Value27351";
VAL_ 2563508115 SIGMA_OBC_AC 0 "Table Value28687";
VAL_ 2563508115 SIGMA_DTCOBC_AC 0 "Table Value28683";
VAL_ 2563508122 SIGMA_HEVC 0 "Table Value27338";
VAL_ 2563508122 SIGMA_DTCHEVC 0 "Table Value27347";
VAL_ 2563508130 SIGMA_AUDIOamp 0 "Table Value16459";
VAL_ 2563508130 SIGMA_DTCAUDIOamp 0 "Table Value26860";
VAL_ 2563508133 SIGMA_HNS 0 "Table Value27353";
VAL_ 2563508133 SIGMA_DTCHNS 0 "Table Value27348";
VAL_ 2563508139 SIGMA_VKM 0 "Table Value252239";
VAL_ 2563508139 SIGMA_DTCVKM 0 "Table Value252234";
VAL_ 2563508153 SIGMA_HFM 0 "Table Value16382";
VAL_ 2563508153 SIGMA_DTCHFM 0 "Table Value26881";
VAL_ 2563508154 SIGMA_AVM 0 "Table Value27338";
VAL_ 2563508154 SIGMA_DTCAVM 0 "Table Value27343";
VAL_ 2563508157 SIGMA_SCU 0 "Table Value28688";
VAL_ 2563508157 SIGMA_DTCSCU 0 "Table Value28684";
VAL_ 2563508164 SIGMA_eShifter 0 "Table Value153058";
VAL_ 2563508164 SIGMA_DTCeShifter 0 "Table Value153055";
VAL_ 2563508181 SIGMA_SRad_RR 0 "Table Value16471";
VAL_ 2563508181 SIGMA_DTCSRad_RR 0 "Table Value26871";
VAL_ 2563508189 SIGMA_FrCamera 0 "Table Value16378";
VAL_ 2563508189 SIGMA_DTCFrCamera 0 "Table Value26880";
VAL_ 2563508200 SIGMA_ECM 0 "Table Value16376";
VAL_ 2563508200 SIGMA_DTCECM 0 "Table Value26878";
VAL_ 2563508201 SIGMA_ATCU 0 "Table Value16375";
VAL_ 2563508201 SIGMA_DTCATCU 0 "Table Value26876";
VAL_ 2563508205 SIGMA_BMS_HV 0 "Table Value27340";
VAL_ 2563508205 SIGMA_DTCBMS_HV 0 "Table Value27344";
VAL_ 2563508207 SIGMA_INV_HSG 0 "Table Value27355";
VAL_ 2563508207 SIGMA_DTCINV_HSG 0 "Table Value27350";
VAL_ 2563567883 SIGMA_BMS_12V 0 "Table Value16460";
VAL_ 2563567883 SIGMA_DTCBMS_12V 0 "Table Value26861";
VAL_ 2563567951 SIGMA_EPS_sub 0 "Table Value28685";
VAL_ 2563567951 SIGMA_DTCEPS_sub 0 "Table Value28681";
VAL_ 2563567958 SIGMA_eShiftAct 0 "Table Value153057";
VAL_ 2563567958 SIGMA_DTCeShiftAct 0 "Table Value153053";
VAL_ 2563567968 SIGMA_HUD 0 "Table Value27354";
VAL_ 2563567968 SIGMA_DTCHUD 0 "Table Value27349";
VAL_ 2563568024 SIGMA_HPCU 0 "Table Value55692";
VAL_ 2563568024 SIGMA_DTCHPCU 0 "Table Value55693";
VAL_ 2563568093 SIGMA_DCDC_HV 0 "Table Value28677";
VAL_ 2563568093 SIGMA_DTCDCDC_HV 0 "Table Value28680";
VAL_ 2563568098 SIGMA_EBA 0 "Table Value16463";
VAL_ 2563568098 SIGMA_DTCEBA 0 "Table Value26864";
VAL_ 2563568101 SIGMA_INV_RE 0 "Table Value27357";
VAL_ 2563568101 SIGMA_DTCINV_RE 0 "Table Value27352";
VAL_ 2563568130 SIGMA_AirSUSP 0 "Table Value359670";
VAL_ 2563568130 SIGMA_DTCAirSUSP 0 "Table Value359671";
VAL_ 2563568148 SIGMA_BSG 0 "Table Value27341";
VAL_ 2563568148 SIGMA_DTCBSG 0 "Table Value27345";
VAL_ 2563568163 SIGMA_SRad_FL 0 "Table Value16468";
VAL_ 2563568163 SIGMA_DTCSRad_FL 0 "Table Value26869";
VAL_ 2563568164 SIGMA_SRad_FR 0 "Table Value16469";
VAL_ 2563568164 SIGMA_DTCSRad_FR 0 "Table Value26870";
VAL_ 2563568201 SIGMA_STBW 0 "Table Value161590";
VAL_ 2563568201 SIGMA_DTCSTBW 0 "Table Value161588";
VAL_ 2563568233 SIGMA_DMC 0 "Table Value27342";
VAL_ 2563568233 SIGMA_DTCDMC 0 "Table Value27346";
VAL_ 2563568267 SIGMA_RSCU3R 0 "Table Value407697";
VAL_ 2563568267 SIGMA_DTCRSCU3R 0 "Table Value407696";
VAL_ 2563568288 SIGMA_BLM_RPK 0 "Table Value55679";
VAL_ 2563568288 SIGMA_DTCBLM_RPK 0 "Table Value55690";
VAL_ 2563568290 SIGMA_SCCM 0 "Table Value16467";
VAL_ 2563568290 SIGMA_DTCSCCM 0 "Table Value26867";
VAL_ 2563568300 SIGMA_RSCU2R 0 "Table Value359675";
VAL_ 2563568300 SIGMA_DTCRSCU2R 0 "Table Value359672";
VAL_ 2563639040 SIGMA_CDM_ReadMeReqRDIAG 0 "Table Value28692";
VAL_ 2563639081 SIGMA_PSD_R_ReadMeReqRDIAG 0 "Table Value359674";
VAL_ 2563639091 SIGMA_PBD_ReadMeReqRDIAG 0 "Table Value28694";
VAL_ 2563639107 SIGMA_eRDC_L_ReadMeReqRDIAG 0 "Table Value252235";
VAL_ 2563639109 SIGMA_eRDC_R_ReadMeReqRDIAG 0 "Table Value252237";
VAL_ 2563639136 SIGMA_ABS_VDC_ReadMeReqRDIAG 0 "Table Value28689";
VAL_ 2563639149 SIGMA_USM_ReadMeReqRDIAG 0 "Table Value407698";
VAL_ 2563639161 SIGMA_PSD_L_ReadMeReqRDIAG 0 "Table Value359673";
VAL_ 2563639180 SIGMA_INV_ME_ReadMeReqRDIAG 0 "Table Value430660";
VAL_ 2563639226 SIGMA_AVM_ReadMeReqRDIAG 0 "Table Value28691";
VAL_ 2563639272 SIGMA_ECM_ReadMeReqRDIAG 0 "Table Value28693";
VAL_ 2563639273 SIGMA_ATCUReadMeReqRDIAG 0 "Table Value28690";
VAL_ 2563639279 SIGMA_INV_HSG_ReadMeReqRDIAG 0 "Table Value430659";
VAL_ 2563699173 SIGMA_INV_RE_ReadMeReqRDIAG 0 "Table Value430661";
VAL_ 2563699202 SIGMA_AirSUSP_ReadMeReqRDIAG 0 "Table Value362331";
VAL_ 2564445937 DTOOL_to_eShiftAct 0 "Table Value153061";
VAL_ 2564478962 DTOOL_to_CSCM 0 "Table Value27360";
VAL_ 2564485847 CSCM_to_DTOOL 0 "Table Value27358";
VAL_ 2609102848 CGW_WakeUp_Signal 0 "Table Value16477";
VAL_ 2609102855 A_IVC_WakeUp_Signal 0 "Table Value16474";
VAL_ 2609102864 BLM_WakeUp_Signal 0 "Table Value28695";
VAL_ 2609102875 VKM_WakeUp_Signal 0 "Table Value609474";
VAL_ 2615050482 FTOOLS_IVCtoSWMC 0 "Table Value16359";
VAL_ 2615061490 FTOOLS_CGWtoBLM 0 "Table Value27365";
VAL_ 2615079552 FTOOLS_SWMCtoIVC 0 "Table Value16361";
VAL_ 2615079595 FTOOLS_BLMtoCGW 0 "Table Value27364";
